VERSION ""

NS_ :

BS_:

BU_: LMFS RMFS TPMS TCU_ERAGLONASS E_APU PCCM NOX_2 NOX_1 ENGINE_CONTROL_MODULE TRANSMISSION INTARDER EBS TACHOGRAPH INSTRUMENT_CLUSTER CAMERA RADAR BCM

BO_ 2566741502 DM43: 22 Vector__XXX
 SG_ FlashRedStopLamp : 12|2@1+ (1,0) [0|3] "" Vector__XXX
 SG_ FlashProtectLamp : 8|2@1+ (1,0) [0|3] "" Vector__XXX
 SG_ FlashMalfuncIndicatorLamp : 14|2@1+ (1,0) [0|3] "" Vector__XXX
 SG_ FlashAmberWarningLamp : 10|2@1+ (1,0) [0|3] "" Vector__XXX
 SG_ MalfunctionIndicatorLampStatus : 6|2@1+ (1,0) [0|3] "" Vector__XXX
 SG_ AmberWarningLampStatus : 2|2@1+ (1,0) [0|3] "" Vector__XXX
 SG_ RedStopLampState : 4|2@1+ (1,0) [0|3] "" Vector__XXX
 SG_ ProtectLampStatus : 0|2@1+ (1,0) [0|3] "" Vector__XXX
 SG_ DTC5 : 144|32@1+ (1,0) [0|4294967295] "" Vector__XXX
 SG_ DTC4 : 112|32@1+ (1,0) [0|4294967295] "" Vector__XXX
 SG_ DTC3 : 80|32@1+ (1,0) [0|4294967295] "" Vector__XXX
 SG_ DTC2 : 48|32@1+ (1,0) [0|4294967295] "" Vector__XXX
 SG_ DTC1 : 16|32@1+ (1,0) [0|4294967295] "" Vector__XXX

BO_ 2566741758 DM42: 22 Vector__XXX
 SG_ FlashRedStopLamp : 12|2@1+ (1,0) [0|3] "" Vector__XXX
 SG_ FlashProtectLamp : 8|2@1+ (1,0) [0|3] "" Vector__XXX
 SG_ FlashMalfuncIndicatorLamp : 14|2@1+ (1,0) [0|3] "" Vector__XXX
 SG_ FlashAmberWarningLamp : 10|2@1+ (1,0) [0|3] "" Vector__XXX
 SG_ MalfunctionIndicatorLampStatus : 6|2@1+ (1,0) [0|3] "" Vector__XXX
 SG_ AmberWarningLampStatus : 2|2@1+ (1,0) [0|3] "" Vector__XXX
 SG_ RedStopLampState : 4|2@1+ (1,0) [0|3] "" Vector__XXX
 SG_ ProtectLampStatus : 0|2@1+ (1,0) [0|3] "" Vector__XXX
 SG_ DTC5 : 144|32@1+ (1,0) [0|4294967295] "" Vector__XXX
 SG_ DTC4 : 112|32@1+ (1,0) [0|4294967295] "" Vector__XXX
 SG_ DTC3 : 80|32@1+ (1,0) [0|4294967295] "" Vector__XXX
 SG_ DTC2 : 48|32@1+ (1,0) [0|4294967295] "" Vector__XXX
 SG_ DTC1 : 16|32@1+ (1,0) [0|4294967295] "" Vector__XXX

BO_ 2566742014 DM41: 22 Vector__XXX
 SG_ FlashRedStopLamp : 12|2@1+ (1,0) [0|3] "" Vector__XXX
 SG_ FlashProtectLamp : 8|2@1+ (1,0) [0|3] "" Vector__XXX
 SG_ FlashMalfuncIndicatorLamp : 14|2@1+ (1,0) [0|3] "" Vector__XXX
 SG_ FlashAmberWarningLamp : 10|2@1+ (1,0) [0|3] "" Vector__XXX
 SG_ MalfunctionIndicatorLampStatus : 6|2@1+ (1,0) [0|3] "" Vector__XXX
 SG_ AmberWarningLampStatus : 2|2@1+ (1,0) [0|3] "" Vector__XXX
 SG_ RedStopLampState : 4|2@1+ (1,0) [0|3] "" Vector__XXX
 SG_ ProtectLampStatus : 0|2@1+ (1,0) [0|3] "" Vector__XXX
 SG_ DTC5 : 144|32@1+ (1,0) [0|4294967295] "" Vector__XXX
 SG_ DTC4 : 112|32@1+ (1,0) [0|4294967295] "" Vector__XXX
 SG_ DTC3 : 80|32@1+ (1,0) [0|4294967295] "" Vector__XXX
 SG_ DTC2 : 48|32@1+ (1,0) [0|4294967295] "" Vector__XXX
 SG_ DTC1 : 16|32@1+ (1,0) [0|4294967295] "" Vector__XXX

BO_ 2560622334 DM35: 22 Vector__XXX
 SG_ FlashRedStopLamp : 12|2@1+ (1,0) [0|3] "" Vector__XXX
 SG_ FlashProtectLamp : 8|2@1+ (1,0) [0|3] "" Vector__XXX
 SG_ FlashMalfuncIndicatorLamp : 14|2@1+ (1,0) [0|3] "" Vector__XXX
 SG_ FlashAmberWarningLamp : 10|2@1+ (1,0) [0|3] "" Vector__XXX
 SG_ MalfunctionIndicatorLampStatus : 6|2@1+ (1,0) [0|3] "" Vector__XXX
 SG_ AmberWarningLampStatus : 2|2@1+ (1,0) [0|3] "" Vector__XXX
 SG_ RedStopLampState : 4|2@1+ (1,0) [0|3] "" Vector__XXX
 SG_ ProtectLampStatus : 0|2@1+ (1,0) [0|3] "" Vector__XXX
 SG_ DTC5 : 144|32@1+ (1,0) [0|4294967295] "" Vector__XXX
 SG_ DTC4 : 112|32@1+ (1,0) [0|4294967295] "" Vector__XXX
 SG_ DTC3 : 80|32@1+ (1,0) [0|4294967295] "" Vector__XXX
 SG_ DTC2 : 48|32@1+ (1,0) [0|4294967295] "" Vector__XXX
 SG_ DTC1 : 16|32@1+ (1,0) [0|4294967295] "" Vector__XXX

BO_ 2566744062 ZNVW: 8 Vector__XXX
 SG_ ZeroNetVehicleWeightChange : 0|2@1+ (1,0) [0|3] "" Vector__XXX

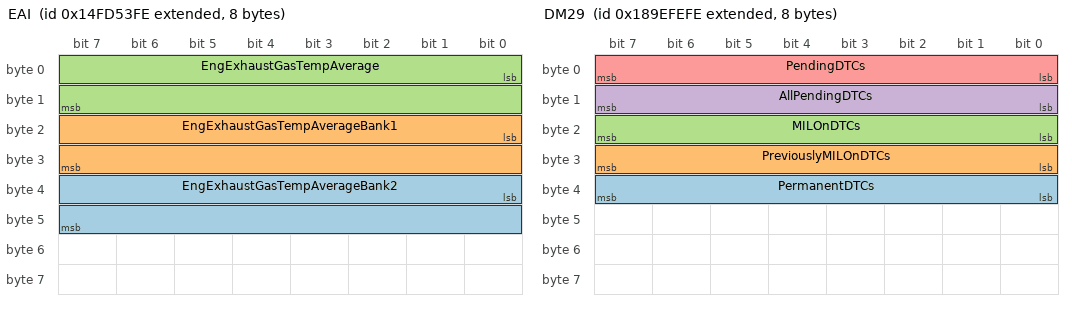
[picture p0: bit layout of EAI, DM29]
BO_ 2499630078 EAI: 8 Vector__XXX
 SG_ EngExhaustGasTempAverageBank2 : 32|16@1+ (0.03125,-273) [-273|1734.96875] "deg C" Vector__XXX
 SG_ EngExhaustGasTempAverageBank1 : 16|16@1+ (0.03125,-273) [-273|1734.96875] "deg C" Vector__XXX
 SG_ EngExhaustGasTempAverage : 0|16@1+ (0.03125,-273) [-273|1734.96875] "deg C" Vector__XXX

BO_ 2560556798 DM29: 8 Vector__XXX
 SG_ PermanentDTCs : 32|8@1+ (1,0) [0|255] "" Vector__XXX
 SG_ PreviouslyMILOnDTCs : 24|8@1+ (1,0) [0|255] "" Vector__XXX
 SG_ MILOnDTCs : 16|8@1+ (1,0) [0|255] "" Vector__XXX
 SG_ AllPendingDTCs : 8|8@1+ (1,0) [0|255] "" Vector__XXX
 SG_ PendingDTCs : 0|8@1+ (1,0) [0|255] "" Vector__XXX

BO_ 2566750462 DM28: 22 Vector__XXX
 SG_ FlashRedStopLamp : 12|2@1+ (1,0) [0|3] "" Vector__XXX
 SG_ FlashProtectLamp : 8|2@1+ (1,0) [0|3] "" Vector__XXX
 SG_ FlashMalfuncIndicatorLamp : 14|2@1+ (1,0) [0|3] "" Vector__XXX
 SG_ FlashAmberWarningLamp : 10|2@1+ (1,0) [0|3] "" Vector__XXX
 SG_ MalfunctionIndicatorLampStatus : 6|2@1+ (1,0) [0|3] "" Vector__XXX
 SG_ AmberWarningLampStatus : 2|2@1+ (1,0) [0|3] "" Vector__XXX
 SG_ RedStopLampState : 4|2@1+ (1,0) [0|3] "" Vector__XXX
 SG_ ProtectLampStatus : 0|2@1+ (1,0) [0|3] "" Vector__XXX
 SG_ DTC5 : 144|32@1+ (1,0) [0|4294967295] "" Vector__XXX
 SG_ DTC4 : 112|32@1+ (1,0) [0|4294967295] "" Vector__XXX
 SG_ DTC3 : 80|32@1+ (1,0) [0|4294967295] "" Vector__XXX
 SG_ DTC2 : 48|32@1+ (1,0) [0|4294967295] "" Vector__XXX
 SG_ DTC1 : 16|32@1+ (1,0) [0|4294967295] "" Vector__XXX

BO_ 2566750974 DM27: 22 Vector__XXX
 SG_ FlashRedStopLamp : 12|2@1+ (1,0) [0|3] "" Vector__XXX
 SG_ FlashProtectLamp : 8|2@1+ (1,0) [0|3] "" Vector__XXX
 SG_ FlashMalfuncIndicatorLamp : 14|2@1+ (1,0) [0|3] "" Vector__XXX
 SG_ FlashAmberWarningLamp : 10|2@1+ (1,0) [0|3] "" Vector__XXX
 SG_ MalfunctionIndicatorLampStatus : 6|2@1+ (1,0) [0|3] "" Vector__XXX
 SG_ AmberWarningLampStatus : 2|2@1+ (1,0) [0|3] "" Vector__XXX
 SG_ RedStopLampState : 4|2@1+ (1,0) [0|3] "" Vector__XXX
 SG_ ProtectLampStatus : 0|2@1+ (1,0) [0|3] "" Vector__XXX
 SG_ DTC5 : 144|32@1+ (1,0) [0|4294967295] "" Vector__XXX
 SG_ DTC4 : 112|32@1+ (1,0) [0|4294967295] "" Vector__XXX
 SG_ DTC3 : 80|32@1+ (1,0) [0|4294967295] "" Vector__XXX
 SG_ DTC2 : 48|32@1+ (1,0) [0|4294967295] "" Vector__XXX
 SG_ DTC1 : 16|32@1+ (1,0) [0|4294967295] "" Vector__XXX

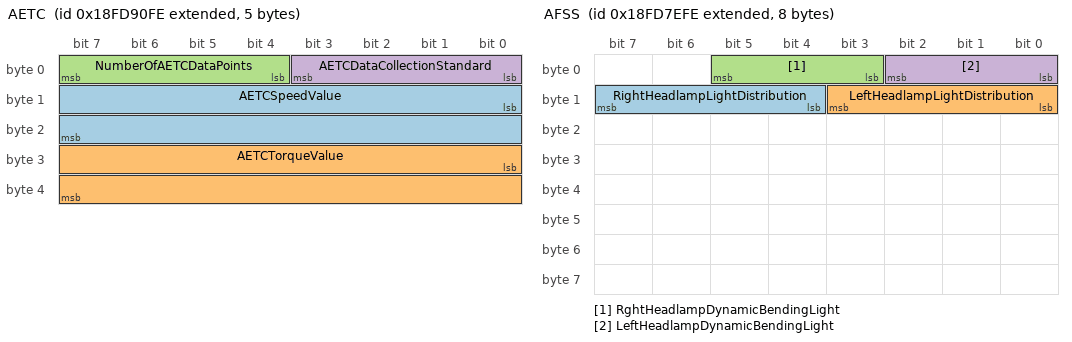
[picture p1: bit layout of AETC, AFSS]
BO_ 2566754558 AETC: 5 Vector__XXX
 SG_ AETCSpeedValue : 8|16@1- (1,0) [0|8031.875] "rpm" Vector__XXX
 SG_ AETCTorqueValue : 24|16@1+ (1,0) [0|64255] "Nm" Vector__XXX
 SG_ NumberOfAETCDataPoints : 4|4@1+ (1,0) [0|15] "" Vector__XXX
 SG_ AETCDataCollectionStandard : 0|4@1+ (1,0) [0|15] "" Vector__XXX

BO_ 2566749950 AFSS: 8 Vector__XXX
 SG_ RightHeadlampLightDistribution : 12|4@1+ (1,0) [0|15] "" Vector__XXX
 SG_ LeftHeadlampLightDistribution : 8|4@1+ (1,0) [0|15] "" Vector__XXX
 SG_ RghtHeadlampDynamicBendingLight : 3|3@1+ (1,0) [0|7] "" Vector__XXX
 SG_ LeftHeadlampDynamicBendingLight : 0|3@1+ (1,0) [0|7] "" Vector__XXX

BO_ 2566838539 AUXIO_T_EBS: 8 EBS
 SG_ AuxI_O16 : 24|2@1+ (1,0) [0|3] ""  PCCM,BCM
 SG_ AuxI_O15 : 26|2@1+ (1,0) [0|3] ""  PCCM,BCM
 SG_ AuxI_O14 : 28|2@1+ (1,0) [0|3] ""  PCCM,BCM
 SG_ AuxI_O13 : 30|2@1+ (1,0) [0|3] ""  PCCM,BCM
 SG_ AuxI_O12 : 16|2@1+ (1,0) [0|3] ""  PCCM,BCM
 SG_ AuxI_O11 : 18|2@1+ (1,0) [0|3] ""  PCCM,BCM
 SG_ AuxI_O10 : 20|2@1+ (1,0) [0|3] ""  PCCM,BCM
 SG_ AuxI_O09 : 22|2@1+ (1,0) [0|3] ""  PCCM,BCM
 SG_ AuxI_O08_GearboxNeutralPos_AUX : 8|2@1+ (1,0) [0|3] ""  PCCM,BCM
 SG_ AuxI_O07_TrailerABSFulOper_AUX : 10|2@1+ (1,0) [0|3] ""  PCCM,BCM
 SG_ AuxI_O06_TrailerABSDetected_AUX : 12|2@1+ (1,0) [0|3] ""  PCCM,BCM
 SG_ AuxI_O05_TrailerConnected_AUX : 14|2@1+ (1,0) [0|3] ""  PCCM,BCM
 SG_ AuxI_O04 : 0|2@1+ (1,0) [0|3] ""  PCCM,BCM
 SG_ AuxI_O03 : 2|2@1+ (1,0) [0|3] ""  PCCM,BCM
 SG_ AuxI_O01 : 6|2@1+ (1,0) [0|3] ""  PCCM,BCM
 SG_ AuxI_OChannel2 : 48|16@1+ (1,0) [0|65535] "counts"  PCCM,BCM
 SG_ AuxI_OChannel1 : 32|16@1+ (1,0) [0|65535] "counts"  PCCM,BCM

BO_ 2561146622 AUXIO2: 8 Vector__XXX
 SG_ AuxI_O45 : 62|2@1+ (1,0) [0|3] "" Vector__XXX
 SG_ AuxI_O46 : 60|2@1+ (1,0) [0|3] "" Vector__XXX
 SG_ AuxI_O47 : 58|2@1+ (1,0) [0|3] "" Vector__XXX
 SG_ AuxI_O48 : 56|2@1+ (1,0) [0|3] "" Vector__XXX
 SG_ AuxI_O41 : 54|2@1+ (1,0) [0|3] "" Vector__XXX
 SG_ AuxI_O42 : 52|2@1+ (1,0) [0|3] "" Vector__XXX
 SG_ AuxI_O43 : 50|2@1+ (1,0) [0|3] "" Vector__XXX
 SG_ AuxI_O44 : 48|2@1+ (1,0) [0|3] "" Vector__XXX
 SG_ AuxI_O37 : 46|2@1+ (1,0) [0|3] "" Vector__XXX
 SG_ AuxI_O38 : 44|2@1+ (1,0) [0|3] "" Vector__XXX
 SG_ AuxI_O39 : 42|2@1+ (1,0) [0|3] "" Vector__XXX
 SG_ AuxI_O40 : 40|2@1+ (1,0) [0|3] "" Vector__XXX
 SG_ AuxI_O33 : 38|2@1+ (1,0) [0|3] "" Vector__XXX
 SG_ AuxI_O34 : 36|2@1+ (1,0) [0|3] "" Vector__XXX
 SG_ AuxI_O35 : 34|2@1+ (1,0) [0|3] "" Vector__XXX
 SG_ AuxI_O36 : 32|2@1+ (1,0) [0|3] "" Vector__XXX
 SG_ AuxI_O29 : 30|2@1+ (1,0) [0|3] "" Vector__XXX
 SG_ AuxI_O30 : 28|2@1+ (1,0) [0|3] "" Vector__XXX
 SG_ AuxI_O31 : 26|2@1+ (1,0) [0|3] "" Vector__XXX
 SG_ AuxI_O32 : 24|2@1+ (1,0) [0|3] "" Vector__XXX
 SG_ AuxI_O25 : 22|2@1+ (1,0) [0|3] "" Vector__XXX
 SG_ AuxI_O26 : 20|2@1+ (1,0) [0|3] "" Vector__XXX
 SG_ AuxI_O27 : 18|2@1+ (1,0) [0|3] "" Vector__XXX
 SG_ AuxI_O28 : 16|2@1+ (1,0) [0|3] "" Vector__XXX
 SG_ AuxI_O21 : 14|2@1+ (1,0) [0|3] "" Vector__XXX
 SG_ AuxI_O22 : 12|2@1+ (1,0) [0|3] "" Vector__XXX
 SG_ AuxI_O23 : 10|2@1+ (1,0) [0|3] "" Vector__XXX
 SG_ AuxI_O24 : 8|2@1+ (1,0) [0|3] "" Vector__XXX
 SG_ AuxI_O17 : 6|2@1+ (1,0) [0|3] "" Vector__XXX
 SG_ AuxI_O18 : 4|2@1+ (1,0) [0|3] "" Vector__XXX
 SG_ AuxI_O19 : 2|2@1+ (1,0) [0|3] "" Vector__XXX
 SG_ AuxI_O20 : 0|2@1+ (1,0) [0|3] "" Vector__XXX

BO_ 2561081086 AUXIO3: 8 Vector__XXX
 SG_ AuxI_O77 : 62|2@1+ (1,0) [0|3] "" Vector__XXX
 SG_ AuxI_O78 : 60|2@1+ (1,0) [0|3] "" Vector__XXX
 SG_ AuxI_O79 : 58|2@1+ (1,0) [0|3] "" Vector__XXX
 SG_ AuxI_O80 : 56|2@1+ (1,0) [0|3] "" Vector__XXX
 SG_ AuxI_O73 : 54|2@1+ (1,0) [0|3] "" Vector__XXX
 SG_ AuxI_O74 : 52|2@1+ (1,0) [0|3] "" Vector__XXX
 SG_ AuxI_O75 : 50|2@1+ (1,0) [0|3] "" Vector__XXX
 SG_ AuxI_O76 : 48|2@1+ (1,0) [0|3] "" Vector__XXX
 SG_ AuxI_O69 : 46|2@1+ (1,0) [0|3] "" Vector__XXX
 SG_ AuxI_O70 : 44|2@1+ (1,0) [0|3] "" Vector__XXX
 SG_ AuxI_O71 : 42|2@1+ (1,0) [0|3] "" Vector__XXX
 SG_ AuxI_O72 : 40|2@1+ (1,0) [0|3] "" Vector__XXX
 SG_ AuxI_O65 : 38|2@1+ (1,0) [0|3] "" Vector__XXX
 SG_ AuxI_O66 : 36|2@1+ (1,0) [0|3] "" Vector__XXX
 SG_ AuxI_O67 : 34|2@1+ (1,0) [0|3] "" Vector__XXX
 SG_ AuxI_O68 : 32|2@1+ (1,0) [0|3] "" Vector__XXX
 SG_ AuxI_O61 : 30|2@1+ (1,0) [0|3] "" Vector__XXX
 SG_ AuxI_O62 : 28|2@1+ (1,0) [0|3] "" Vector__XXX
 SG_ AuxI_O63 : 26|2@1+ (1,0) [0|3] "" Vector__XXX
 SG_ AuxI_O64 : 24|2@1+ (1,0) [0|3] "" Vector__XXX
 SG_ AuxI_O57 : 22|2@1+ (1,0) [0|3] "" Vector__XXX
 SG_ AuxI_O58 : 20|2@1+ (1,0) [0|3] "" Vector__XXX
 SG_ AuxI_O59 : 18|2@1+ (1,0) [0|3] "" Vector__XXX
 SG_ AuxI_O60 : 16|2@1+ (1,0) [0|3] "" Vector__XXX
 SG_ AuxI_O53 : 14|2@1+ (1,0) [0|3] "" Vector__XXX
 SG_ AuxI_O54 : 12|2@1+ (1,0) [0|3] "" Vector__XXX
 SG_ AuxI_O55 : 10|2@1+ (1,0) [0|3] "" Vector__XXX
 SG_ AuxI_O56 : 8|2@1+ (1,0) [0|3] "" Vector__XXX
 SG_ AuxI_O49 : 6|2@1+ (1,0) [0|3] "" Vector__XXX
 SG_ AuxI_O50 : 4|2@1+ (1,0) [0|3] "" Vector__XXX
 SG_ AuxI_O51 : 2|2@1+ (1,0) [0|3] "" Vector__XXX
 SG_ AuxI_O52 : 0|2@1+ (1,0) [0|3] "" Vector__XXX

BO_ 2561015550 AUXIO4: 8 Vector__XXX
 SG_ AuxI_O92 : 16|2@1+ (1,0) [0|3] "" Vector__XXX
 SG_ AuxI_O85 : 14|2@1+ (1,0) [0|3] "" Vector__XXX
 SG_ AuxI_O86 : 12|2@1+ (1,0) [0|3] "" Vector__XXX
 SG_ AuxI_O87 : 10|2@1+ (1,0) [0|3] "" Vector__XXX
 SG_ AuxI_O88 : 8|2@1+ (1,0) [0|3] "" Vector__XXX
 SG_ AuxI_O81 : 6|2@1+ (1,0) [0|3] "" Vector__XXX
 SG_ AuxI_O82 : 4|2@1+ (1,0) [0|3] "" Vector__XXX
 SG_ AuxI_O83 : 2|2@1+ (1,0) [0|3] "" Vector__XXX
 SG_ AuxI_O84 : 0|2@1+ (1,0) [0|3] "" Vector__XXX
 SG_ AuxI_O109 : 62|2@1+ (1,0) [0|3] "" Vector__XXX
 SG_ AuxI_O110 : 60|2@1+ (1,0) [0|3] "" Vector__XXX
 SG_ AuxI_O111 : 58|2@1+ (1,0) [0|3] "" Vector__XXX
 SG_ AuxI_O112 : 56|2@1+ (1,0) [0|3] "" Vector__XXX
 SG_ AuxI_O105 : 54|2@1+ (1,0) [0|3] "" Vector__XXX
 SG_ AuxI_O106 : 52|2@1+ (1,0) [0|3] "" Vector__XXX
 SG_ AuxI_O107 : 50|2@1+ (1,0) [0|3] "" Vector__XXX
 SG_ AuxI_O108 : 48|2@1+ (1,0) [0|3] "" Vector__XXX
 SG_ AuxI_O101 : 46|2@1+ (1,0) [0|3] "" Vector__XXX
 SG_ AuxI_O102 : 44|2@1+ (1,0) [0|3] "" Vector__XXX
 SG_ AuxI_O103 : 42|2@1+ (1,0) [0|3] "" Vector__XXX
 SG_ AuxI_O104 : 40|2@1+ (1,0) [0|3] "" Vector__XXX
 SG_ AuxI_O97 : 38|2@1+ (1,0) [0|3] "" Vector__XXX
 SG_ AuxI_O98 : 36|2@1+ (1,0) [0|3] "" Vector__XXX
 SG_ AuxI_O99 : 34|2@1+ (1,0) [0|3] "" Vector__XXX
 SG_ AuxI_O100 : 32|2@1+ (1,0) [0|3] "" Vector__XXX
 SG_ AuxI_O93 : 30|2@1+ (1,0) [0|3] "" Vector__XXX
 SG_ AuxI_O94 : 28|2@1+ (1,0) [0|3] "" Vector__XXX
 SG_ AuxI_O95 : 26|2@1+ (1,0) [0|3] "" Vector__XXX
 SG_ AuxI_O96 : 24|2@1+ (1,0) [0|3] "" Vector__XXX
 SG_ AuxI_O89 : 22|2@1+ (1,0) [0|3] "" Vector__XXX
 SG_ AuxI_O90 : 20|2@1+ (1,0) [0|3] "" Vector__XXX
 SG_ AuxI_O91 : 18|2@1+ (1,0) [0|3] "" Vector__XXX

BO_ 2566746622 BSA: 8 Vector__XXX
 SG_ TrailerBrakeStrokeAxle5Right : 57|3@1+ (1,0) [0|7] "" Vector__XXX
 SG_ TrailerBrakeStrokeAxle5Left : 54|3@1+ (1,0) [0|7] "" Vector__XXX
 SG_ TrailerBrakeStrokeAxle4Right : 51|3@1+ (1,0) [0|7] "" Vector__XXX
 SG_ TrailerBrakeStrokeAxle4Left : 48|3@1+ (1,0) [0|7] "" Vector__XXX
 SG_ TrailerBrakeStrokeAxle3Right : 45|3@1+ (1,0) [0|7] "" Vector__XXX
 SG_ TrailerBrakeStrokeAxle3Left : 42|3@1+ (1,0) [0|7] "" Vector__XXX
 SG_ TrailerBrakeStrokeAxle2Right : 39|3@1+ (1,0) [0|7] "" Vector__XXX
 SG_ TrailerBrakeStrokeAxle2Left : 36|3@1+ (1,0) [0|7] "" Vector__XXX
 SG_ TrailerBrakeStrokeAxle1Right : 33|3@1+ (1,0) [0|7] "" Vector__XXX
 SG_ TrailerBrakeStrokeAxle1Left : 30|3@1+ (1,0) [0|7] "" Vector__XXX
 SG_ TractorBrakeStrokeAxle5Right : 27|3@1+ (1,0) [0|7] "" Vector__XXX
 SG_ TractorBrakeStrokeAxle5Left : 24|3@1+ (1,0) [0|7] "" Vector__XXX
 SG_ TractorBrakeStrokeAxle4Right : 21|3@1+ (1,0) [0|7] "" Vector__XXX
 SG_ TractorBrakeStrokeAxle4Left : 18|3@1+ (1,0) [0|7] "" Vector__XXX
 SG_ TractorBrakeStrokeAxle3Right : 15|3@1+ (1,0) [0|7] "" Vector__XXX
 SG_ TractorBrakeStrokeAxle3Left : 12|3@1+ (1,0) [0|7] "" Vector__XXX
 SG_ TractorBrakeStrokeAxle2Right : 9|3@1+ (1,0) [0|7] "" Vector__XXX
 SG_ TractorBrakeStrokeAxle2Left : 6|3@1+ (1,0) [0|7] "" Vector__XXX
 SG_ TractorBrakeStrokeAxle1Right : 3|3@1+ (1,0) [0|7] "" Vector__XXX
 SG_ TractorBrakeStrokeAxle1Left : 0|3@1+ (1,0) [0|7] "" Vector__XXX

BO_ 2566845950 AMB: 8 Vector__XXX
 SG_ EngAirIntakeTemp : 40|8@1+ (1,-40) [-40|210] "deg C" Vector__XXX
 SG_ BarometricPress : 0|8@1+ (0.5,0) [0|125] "kPa" Vector__XXX

BO_ 2566840062 AIR2: 8 Vector__XXX
 SG_ EngAirStartPress : 0|8@1+ (4,0) [0|1000] "kPa" Vector__XXX

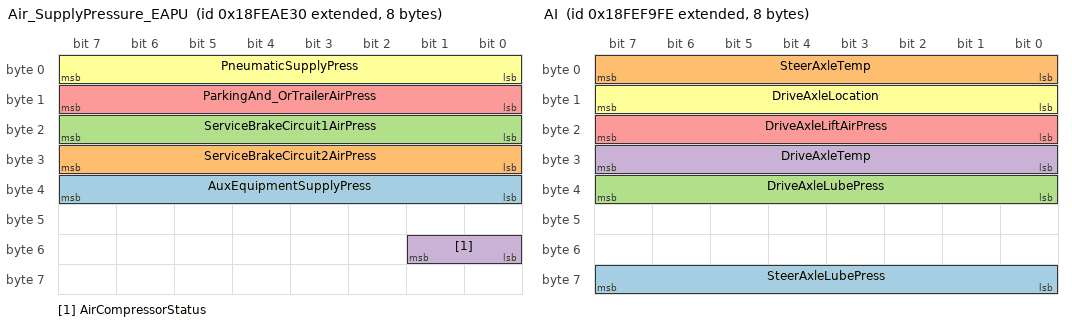
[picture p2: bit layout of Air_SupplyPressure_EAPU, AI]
BO_ 2566827568 Air_SupplyPressure_EAPU: 8 E_APU
 SG_ AuxEquipmentSupplyPress : 32|8@1+ (8,0) [0|2000] "kPa"  PCCM
 SG_ ServiceBrakeCircuit2AirPress : 24|8@1+ (8,0) [0|2000] "kPa"  PCCM,INSTRUMENT_CLUSTER,BCM
 SG_ ServiceBrakeCircuit1AirPress : 16|8@1+ (8,0) [0|2000] "kPa"  PCCM,INSTRUMENT_CLUSTER,BCM
 SG_ AirCompressorStatus : 48|2@1+ (1,0) [0|3] ""  PCCM,INSTRUMENT_CLUSTER,BCM
 SG_ ParkingAnd_OrTrailerAirPress : 8|8@1+ (8,0) [0|2000] "kPa"  PCCM,INSTRUMENT_CLUSTER,BCM
 SG_ PneumaticSupplyPress : 0|8@1+ (8,0) [0|2000] "kPa"  PCCM,INSTRUMENT_CLUSTER,BCM

BO_ 2566846974 AI: 8 Vector__XXX
 SG_ SteerAxleLubePress : 56|8@1+ (4,0) [0|1000] "kPa" Vector__XXX
 SG_ SteerAxleTemp : 0|8@1+ (1,-40) [-40|210] "deg C" Vector__XXX
 SG_ DriveAxleLubePress : 32|8@1+ (4,0) [0|1000] "kPa" Vector__XXX
 SG_ DriveAxleTemp : 24|8@1+ (1,-40) [-40|210] "deg C" Vector__XXX
 SG_ DriveAxleLiftAirPress : 16|8@1+ (4,0) [0|1000] "kPa" Vector__XXX
 SG_ DriveAxleLocation : 8|8@1+ (1,0) [0|255] "" Vector__XXX

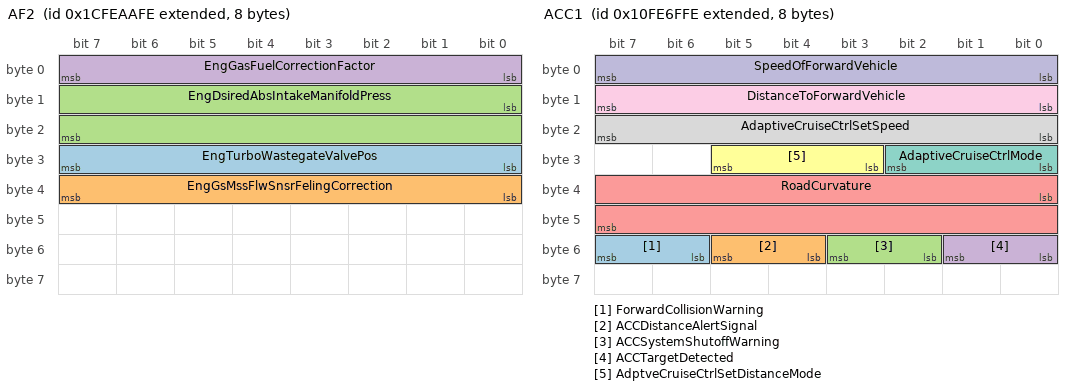
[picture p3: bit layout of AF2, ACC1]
BO_ 2633935614 AF2: 8 Vector__XXX
 SG_ EngTurboWastegateValvePos : 24|8@1+ (0.4,0) [0|100] "%" Vector__XXX
 SG_ EngGsMssFlwSnsrFelingCorrection : 32|8@1+ (1,-125) [-125|125] "%" Vector__XXX
 SG_ EngDsiredAbsIntakeManifoldPress : 8|16@1+ (0.1,0) [0|6425.5] "kPa" Vector__XXX
 SG_ EngGasFuelCorrectionFactor : 0|8@1+ (1,0) [0|250] "%" Vector__XXX

BO_ 2566803745 ACC2: 8 BCM
 SG_ RequestedACCDistanceMode : 5|3@1+ (1,0) [0|7] "SED"  RADAR
 SG_ ACCUsageDemand_ACC2 : 0|2@1+ (1,0) [0|3] ""  RADAR

BO_ 2432593918 ACC1: 8 Vector__XXX
 SG_ ForwardCollisionWarning : 54|2@1+ (1,0) [0|3] "" Vector__XXX
 SG_ ACCDistanceAlertSignal : 52|2@1+ (1,0) [0|3] "" Vector__XXX
 SG_ ACCSystemShutoffWarning : 50|2@1+ (1,0) [0|3] "" Vector__XXX
 SG_ ACCTargetDetected : 48|2@1+ (1,0) [0|3] "" Vector__XXX
 SG_ RoadCurvature : 32|16@1+ (0.0078125,-250) [-250|251.992] "1/km" Vector__XXX
 SG_ AdptveCruiseCtrlSetDistanceMode : 27|3@1+ (1,0) [0|7] "" Vector__XXX
 SG_ AdaptiveCruiseCtrlMode : 24|3@1+ (1,0) [0|7] "" Vector__XXX
 SG_ AdaptiveCruiseCtrlSetSpeed : 16|8@1+ (1,0) [0|250] "km/h" Vector__XXX
 SG_ DistanceToForwardVehicle : 8|8@1+ (1,0) [0|250] "m" Vector__XXX
 SG_ SpeedOfForwardVehicle : 0|8@1+ (1,0) [0|250] "km/h" Vector__XXX

BO_ 2633935102 AC: 8 Vector__XXX
 SG_ ArticulationAngle : 0|8@1+ (1,-125) [-125|125] "deg" Vector__XXX

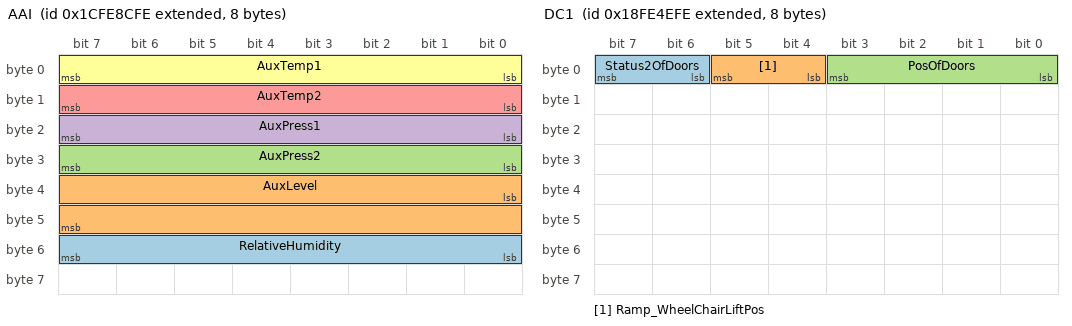
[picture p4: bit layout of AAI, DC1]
BO_ 2633927934 AAI: 8 Vector__XXX
 SG_ RelativeHumidity : 48|8@1+ (0.4,0) [0|100] "%" Vector__XXX
 SG_ AuxLevel : 32|16@1+ (0.1,0) [0|6425.5] "mm" Vector__XXX
 SG_ AuxPress2 : 24|8@1+ (16,0) [0|4000] "kPa" Vector__XXX
 SG_ AuxPress1 : 16|8@1+ (16,0) [0|4000] "kPa" Vector__XXX
 SG_ AuxTemp2 : 8|8@1+ (1,-40) [-40|210] "deg C" Vector__XXX
 SG_ AuxTemp1 : 0|8@1+ (1,-40) [-40|210] "deg C" Vector__XXX

BO_ 2566847998 A1: 8 Vector__XXX
 SG_ EngBlowerBypassValvePos : 0|8@1+ (0.4,0) [0|100] "%" Vector__XXX
 SG_ EngGasSupplyPress : 8|16@1+ (0.5,0) [0|32127.5] "kPa" Vector__XXX

BO_ 2565406462 ACKM: 8 Vector__XXX
 SG_ AddressBusy m3 : 32|8@1+ (1,0) [0|255] "" Vector__XXX
 SG_ ControlByte M : 0|8@1+ (1,0) [0|255] "" Vector__XXX
 SG_ GroupFunctionValue : 8|8@1+ (1,0) [0|255] "" Vector__XXX
 SG_ AddressAccessDenied m2 : 32|8@1+ (1,0) [0|255] "" Vector__XXX
 SG_ AddressNegativeAcknowledgement m1 : 32|8@1+ (1,0) [0|255] "" Vector__XXX
 SG_ AddressAcknowledged m0 : 32|8@1+ (1,0) [0|255] "" Vector__XXX

BO_ 2566803198 DC1: 8 Vector__XXX
 SG_ Status2OfDoors : 6|2@1+ (1,0) [0|3] "" Vector__XXX
 SG_ Ramp_WheelChairLiftPos : 4|2@1+ (1,0) [0|3] "" Vector__XXX
 SG_ PosOfDoors : 0|4@1+ (1,0) [0|15] "" Vector__XXX

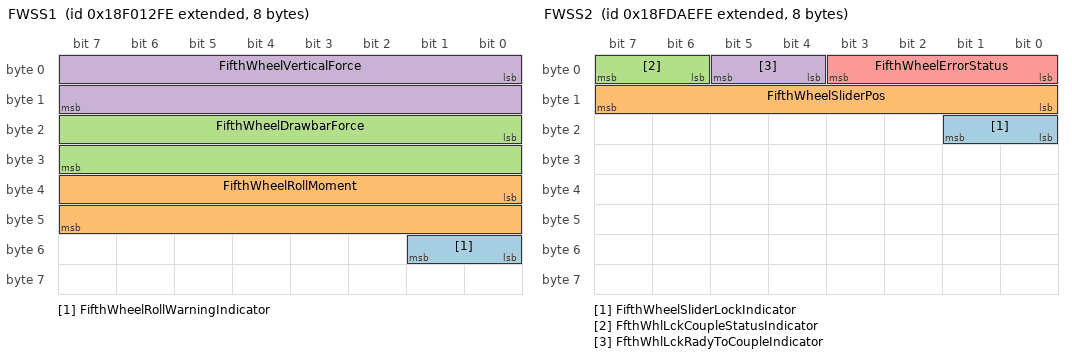
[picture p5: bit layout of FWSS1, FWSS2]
BO_ 2565870334 FWSS1: 8 Vector__XXX
 SG_ FifthWheelRollWarningIndicator : 48|2@1+ (1,0) [0|3] "" Vector__XXX
 SG_ FifthWheelRollMoment : 32|16@1+ (10,-320000) [-320000|322550] "N" Vector__XXX
 SG_ FifthWheelDrawbarForce : 16|16@1+ (10,-320000) [-320000|322550] "N" Vector__XXX
 SG_ FifthWheelVerticalForce : 0|16@1+ (5,0) [0|321275] "N" Vector__XXX

BO_ 2566762238 FWSS2: 8 Vector__XXX
 SG_ FifthWheelSliderLockIndicator : 16|2@1+ (1,0) [0|3] "" Vector__XXX
 SG_ FifthWheelSliderPos : 8|8@1+ (10,0) [0|2500] "mm" Vector__XXX
 SG_ FfthWhlLckCoupleStatusIndicator : 6|2@1+ (1,0) [0|3] "" Vector__XXX
 SG_ FfthWhlLckRadyToCoupleIndicator : 4|2@1+ (1,0) [0|3] "" Vector__XXX
 SG_ FifthWheelErrorStatus : 0|4@1+ (1,0) [0|15] "" Vector__XXX

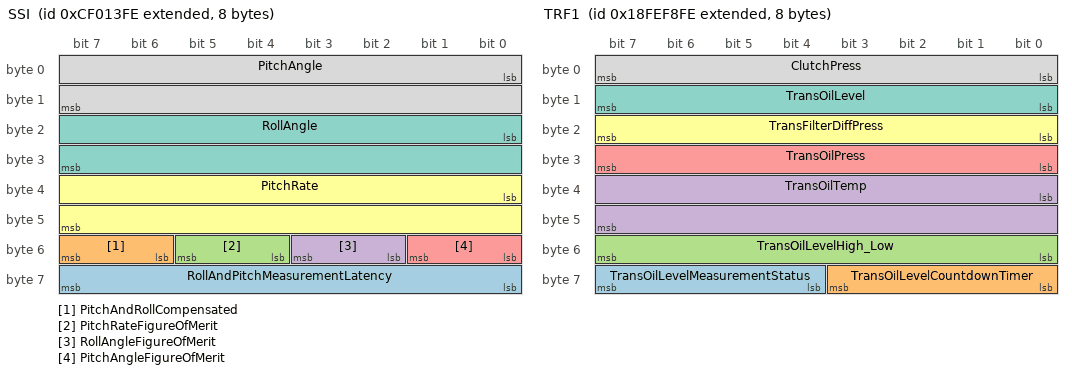
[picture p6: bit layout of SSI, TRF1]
BO_ 2364543998 SSI: 8 Vector__XXX
 SG_ RollAndPitchMeasurementLatency : 56|8@1+ (0.5,0) [0|125] "ms" Vector__XXX
 SG_ PitchAndRollCompensated : 54|2@1+ (1,0) [0|3] "" Vector__XXX
 SG_ PitchRateFigureOfMerit : 52|2@1+ (1,0) [0|3] "" Vector__XXX
 SG_ RollAngleFigureOfMerit : 50|2@1+ (1,0) [0|3] "" Vector__XXX
 SG_ PitchAngleFigureOfMerit : 48|2@1+ (1,0) [0|3] "" Vector__XXX
 SG_ PitchRate : 32|16@1+ (0.002,-64) [-64|64.51] "deg/sec" Vector__XXX
 SG_ RollAngle : 16|16@1+ (0.002,-64) [-64|64.51] "deg" Vector__XXX
 SG_ PitchAngle : 0|16@1+ (0.002,-64) [-64|64.51] "deg" Vector__XXX

BO_ 2566846718 TRF1: 8 Vector__XXX
 SG_ TransOilLevelMeasurementStatus : 60|4@1+ (1,0) [0|15] "" Vector__XXX
 SG_ TransOilLevelCountdownTimer : 56|4@1+ (1,0) [0|15] "" Vector__XXX
 SG_ TransOilLevelHigh_Low : 48|8@1+ (0.5,-62.5) [-62.5|62.5] "L" Vector__XXX
 SG_ TransOilTemp : 32|16@1+ (0.03125,-273) [-273|1734.96875] "deg C" Vector__XXX
 SG_ TransOilPress : 24|8@1+ (16,0) [0|4000] "kPa" Vector__XXX
 SG_ TransFilterDiffPress : 16|8@1+ (2,0) [0|500] "kPa" Vector__XXX
 SG_ TransOilLevel : 8|8@1+ (0.4,0) [0|100] "%" Vector__XXX
 SG_ ClutchPress : 0|8@1+ (16,0) [0|4000] "kPa" Vector__XXX

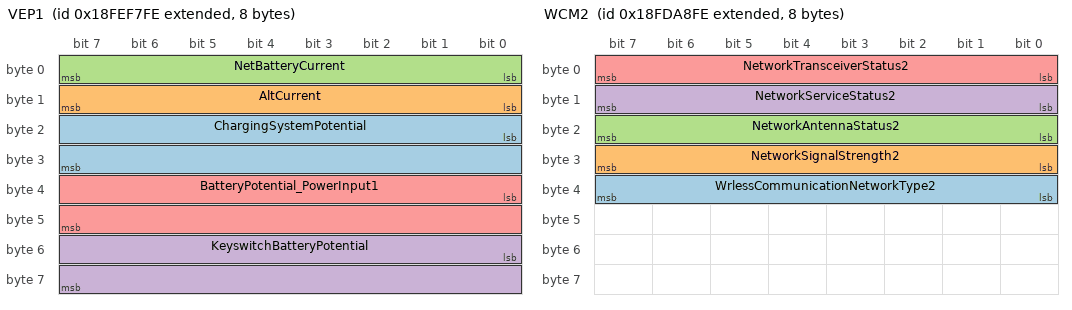
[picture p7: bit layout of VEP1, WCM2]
BO_ 2566846462 VEP1: 8 Vector__XXX
 SG_ ChargingSystemPotential : 16|16@1+ (0.05,0) [0|3212.75] "V" Vector__XXX
 SG_ AltCurrent : 8|8@1+ (1,0) [0|250] "A" Vector__XXX
 SG_ NetBatteryCurrent : 0|8@1+ (1,-125) [-125|125] "A" Vector__XXX
 SG_ KeyswitchBatteryPotential : 48|16@1+ (0.05,0) [0|3212.75] "V" Vector__XXX
 SG_ BatteryPotential_PowerInput1 : 32|16@1+ (0.05,0) [0|3212.75] "V" Vector__XXX

BO_ 2566760702 WCM2: 8 Vector__XXX
 SG_ WrlessCommunicationNetworkType2 : 32|8@1+ (1,0) [0|255] "" Vector__XXX
 SG_ NetworkSignalStrength2 : 24|8@1+ (0.4,0) [0|100] "%" Vector__XXX
 SG_ NetworkAntennaStatus2 : 16|8@1+ (1,0) [0|255] "" Vector__XXX
 SG_ NetworkServiceStatus2 : 8|8@1+ (1,0) [0|255] "" Vector__XXX
 SG_ NetworkTransceiverStatus2 : 0|8@1+ (1,0) [0|255] "" Vector__XXX

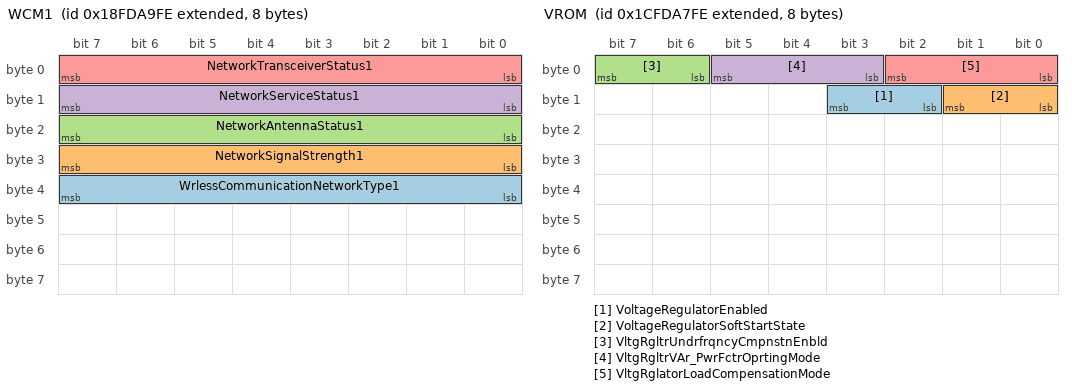
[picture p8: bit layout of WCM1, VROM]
BO_ 2566760958 WCM1: 8 Vector__XXX
 SG_ WrlessCommunicationNetworkType1 : 32|8@1+ (1,0) [0|255] "" Vector__XXX
 SG_ NetworkSignalStrength1 : 24|8@1+ (0.4,0) [0|100] "%" Vector__XXX
 SG_ NetworkAntennaStatus1 : 16|8@1+ (1,0) [0|255] "" Vector__XXX
 SG_ NetworkServiceStatus1 : 8|8@1+ (1,0) [0|255] "" Vector__XXX
 SG_ NetworkTransceiverStatus1 : 0|8@1+ (1,0) [0|255] "" Vector__XXX

BO_ 2633869310 VROM: 8 Vector__XXX
 SG_ VoltageRegulatorEnabled : 10|2@1+ (1,0) [0|3] "" Vector__XXX
 SG_ VoltageRegulatorSoftStartState : 8|2@1+ (1,0) [0|3] "" Vector__XXX
 SG_ VltgRgltrUndrfrqncyCmpnstnEnbld : 6|2@1+ (1,0) [0|3] "" Vector__XXX
 SG_ VltgRgltrVAr_PwrFctrOprtingMode : 3|3@1+ (1,0) [0|7] "" Vector__XXX
 SG_ VltgRglatorLoadCompensationMode : 0|3@1+ (1,0) [0|7] "" Vector__XXX

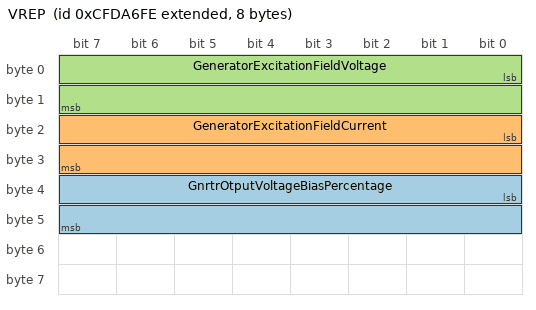
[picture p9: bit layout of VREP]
BO_ 2365433598 VREP: 8 Vector__XXX
 SG_ GnrtrOtputVoltageBiasPercentage : 32|16@1+ (0.1,-100) [-100|100] "%" Vector__XXX
 SG_ GeneratorExcitationFieldCurrent : 16|16@1+ (0.05,0) [0|3217.5] "A" Vector__XXX
 SG_ GeneratorExcitationFieldVoltage : 0|16@1+ (0.05,-1605.625) [-1605.625|1606.375] "V" Vector__XXX

CM_ BO_ 2565928476 "- 1s when no data to transmit; Segment, Stub or Profiles data sent, in the empty slots, at 100ms";
CM_ BO_ 2564554494 "Reserved for ISO 15765";
CM_ SG_ 2564554494 ProtocolCtrlInformation "Part of Network Protocol Control Information (N_PCI) of a ISO 15765 message.";
CM_ BO_ 2564488958 "Reserved for ISO 15765";
CM_ SG_ 2564488958 ProtocolCtrlInformation "Part of Network Protocol Control Information (N_PCI) of a ISO 15765 message.";
CM_ BO_ 2566741502 "Class A, Previously Active";
CM_ SG_ 2566741502 FlashRedStopLamp "This parameter provides the capability to flash the RSL (SPN 3039).";
CM_ SG_ 2566741502 FlashProtectLamp "This parameter provides the capability to flash the engine protect lamp (SPN 3041).";
CM_ SG_ 2566741502 FlashMalfuncIndicatorLamp "This parameter provides the capability to flash the MIL (SPN 3038).";
CM_ SG_ 2566741502 FlashAmberWarningLamp "This parameter provides the capability to flash the AWL (SPN 3040). ";
CM_ SG_ 2566741502 MalfunctionIndicatorLampStatus "A lamp used to relay only emissions-related trouble code information.";
CM_ SG_ 2566741502 AmberWarningLampStatus "This lamp is used to relay trouble code information that is reporting a problem with the vehicle system but the vehicle need
not be immediately stopped.";
CM_ SG_ 2566741502 RedStopLampState "This lamp is uesed to relay trouble code information that is of a severe enought condition that it warrants stopping the vehicle.";
CM_ SG_ 2566741502 ProtectLampStatus "This lamp is used to relay trouble code informatio that is reporting a problem with a vehicle system that is most
probably not electronic subsystem related.";
CM_ SG_ 2566741502 DTC5 "Diagnostic Trouble Code";
CM_ SG_ 2566741502 DTC4 "Diagnostic Trouble Code";
CM_ SG_ 2566741502 DTC3 "Diagnostic Trouble Code";
CM_ SG_ 2566741502 DTC2 "Diagnostic Trouble Code";
CM_ SG_ 2566741502 DTC1 "Diagnostic Trouble Code";
CM_ BO_ 2566741758 "Class A, Confirmed and Active";
CM_ SG_ 2566741758 FlashRedStopLamp "This parameter provides the capability to flash the RSL (SPN 3039).";
CM_ SG_ 2566741758 FlashProtectLamp "This parameter provides the capability to flash the engine protect lamp (SPN 3041).";
CM_ SG_ 2566741758 FlashMalfuncIndicatorLamp "This parameter provides the capability to flash the MIL (SPN 3038).";
CM_ SG_ 2566741758 FlashAmberWarningLamp "This parameter provides the capability to flash the AWL (SPN 3040). ";
CM_ SG_ 2566741758 MalfunctionIndicatorLampStatus "A lamp used to relay only emissions-related trouble code information.";
CM_ SG_ 2566741758 AmberWarningLampStatus "This lamp is used to relay trouble code information that is reporting a problem with the vehicle system but the vehicle need
not be immediately stopped.";
CM_ SG_ 2566741758 RedStopLampState "This lamp is uesed to relay trouble code information that is of a severe enought condition that it warrants stopping the vehicle.";
CM_ SG_ 2566741758 ProtectLampStatus "This lamp is used to relay trouble code informatio that is reporting a problem with a vehicle system that is most
probably not electronic subsystem related.";
CM_ SG_ 2566741758 DTC5 "Diagnostic Trouble Code";
CM_ SG_ 2566741758 DTC4 "Diagnostic Trouble Code";
CM_ SG_ 2566741758 DTC3 "Diagnostic Trouble Code";
CM_ SG_ 2566741758 DTC2 "Diagnostic Trouble Code";
CM_ SG_ 2566741758 DTC1 "Diagnostic Trouble Code";
CM_ BO_ 2566742014 "Class A, Pending";
CM_ SG_ 2566742014 FlashRedStopLamp "This parameter provides the capability to flash the RSL (SPN 3039).";
CM_ SG_ 2566742014 FlashProtectLamp "This parameter provides the capability to flash the engine protect lamp (SPN 3041).";
CM_ SG_ 2566742014 FlashMalfuncIndicatorLamp "This parameter provides the capability to flash the MIL (SPN 3038).";
CM_ SG_ 2566742014 FlashAmberWarningLamp "This parameter provides the capability to flash the AWL (SPN 3040). ";
CM_ SG_ 2566742014 MalfunctionIndicatorLampStatus "A lamp used to relay only emissions-related trouble code information.";
CM_ SG_ 2566742014 AmberWarningLampStatus "This lamp is used to relay trouble code information that is reporting a problem with the vehicle system but the vehicle need
not be immediately stopped.";
CM_ SG_ 2566742014 RedStopLampState "This lamp is uesed to relay trouble code information that is of a severe enought condition that it warrants stopping the vehicle.";
CM_ SG_ 2566742014 ProtectLampStatus "This lamp is used to relay trouble code informatio that is reporting a problem with a vehicle system that is most
probably not electronic subsystem related.";
CM_ SG_ 2566742014 DTC5 "Diagnostic Trouble Code";
CM_ SG_ 2566742014 DTC4 "Diagnostic Trouble Code";
CM_ SG_ 2566742014 DTC3 "Diagnostic Trouble Code";
CM_ SG_ 2566742014 DTC2 "Diagnostic Trouble Code";
CM_ SG_ 2566742014 DTC1 "Diagnostic Trouble Code";
CM_ BO_ 2560622334 "Immediate Fault Status ";
CM_ SG_ 2560622334 FlashRedStopLamp "This parameter provides the capability to flash the RSL (SPN 3039).";
CM_ SG_ 2560622334 FlashProtectLamp "This parameter provides the capability to flash the engine protect lamp (SPN 3041).";
CM_ SG_ 2560622334 FlashMalfuncIndicatorLamp "This parameter provides the capability to flash the MIL (SPN 3038).";
CM_ SG_ 2560622334 FlashAmberWarningLamp "This parameter provides the capability to flash the AWL (SPN 3040). ";
CM_ SG_ 2560622334 MalfunctionIndicatorLampStatus "A lamp used to relay only emissions-related trouble code information.";
CM_ SG_ 2560622334 AmberWarningLampStatus "This lamp is used to relay trouble code information that is reporting a problem with the vehicle system but the vehicle need
not be immediately stopped.";
CM_ SG_ 2560622334 RedStopLampState "This lamp is uesed to relay trouble code information that is of a severe enought condition that it warrants stopping the vehicle.";
CM_ SG_ 2560622334 ProtectLampStatus "This lamp is used to relay trouble code informatio that is reporting a problem with a vehicle system that is most
probably not electronic subsystem related.";
CM_ SG_ 2560622334 DTC5 "Diagnostic Trouble Code";
CM_ SG_ 2560622334 DTC4 "Diagnostic Trouble Code";
CM_ SG_ 2560622334 DTC3 "Diagnostic Trouble Code";
CM_ SG_ 2560622334 DTC2 "Diagnostic Trouble Code";
CM_ SG_ 2560622334 DTC1 "Diagnostic Trouble Code";
CM_ BO_ 2566744062 "Zero Net Vehicle Weight Change";
CM_ SG_ 2566744062 ZeroNetVehicleWeightChange "Zero Net Vehicle Weight Change command.";
CM_ BO_ 2499630078 "Reports averaged engine information";
CM_ SG_ 2499630078 EngExhaustGasTempAverageBank2 "The calculated average temperature based upon all of the Bank 2 (right bank) engine exhaust port temperatures.";
CM_ SG_ 2499630078 EngExhaustGasTempAverageBank1 "The calculated average temperature based upon all of the Bank 1 (left bank) engine exhaust port temperatures.";
CM_ SG_ 2499630078 EngExhaustGasTempAverage "The calculated average temperature based upon all of the engine exhaust port temperatures.";
CM_ BO_ 2560556798 "DTC Counts";
CM_ SG_ 2560556798 PermanentDTCs "Identifies the current number of permanent DTCs";
CM_ SG_ 2560556798 PreviouslyMILOnDTCs "Identifies the current number of previously MIL-On DTCs";
CM_ SG_ 2560556798 MILOnDTCs "Identifies the current number of MIL-On DTCs";
CM_ SG_ 2560556798 AllPendingDTCs "Identifies the current total number of pending DTCs, including emission related";
CM_ SG_ 2560556798 PendingDTCs "Identifies the current number of emission related pending DTCs";
CM_ BO_ 2566750462 "Permanent DTCs";
CM_ SG_ 2566750462 FlashRedStopLamp "This parameter provides the capability to flash the RSL (SPN 3039).";
CM_ SG_ 2566750462 FlashProtectLamp "This parameter provides the capability to flash the engine protect lamp (SPN 3041).";
CM_ SG_ 2566750462 FlashMalfuncIndicatorLamp "This parameter provides the capability to flash the MIL (SPN 3038).";
CM_ SG_ 2566750462 FlashAmberWarningLamp "This parameter provides the capability to flash the AWL (SPN 3040). ";
CM_ SG_ 2566750462 MalfunctionIndicatorLampStatus "A lamp used to relay only emissions-related trouble code information.";
CM_ SG_ 2566750462 AmberWarningLampStatus "This lamp is used to relay trouble code information that is reporting a problem with the vehicle system but the vehicle need
not be immediately stopped.";
CM_ SG_ 2566750462 RedStopLampState "This lamp is uesed to relay trouble code information that is of a severe enought condition that it warrants stopping the vehicle.";
CM_ SG_ 2566750462 ProtectLampStatus "This lamp is used to relay trouble code informatio that is reporting a problem with a vehicle system that is most
probably not electronic subsystem related.";
CM_ SG_ 2566750462 DTC5 "Diagnostic Trouble Code";
CM_ SG_ 2566750462 DTC4 "Diagnostic Trouble Code";
CM_ SG_ 2566750462 DTC3 "Diagnostic Trouble Code";
CM_ SG_ 2566750462 DTC2 "Diagnostic Trouble Code";
CM_ SG_ 2566750462 DTC1 "Diagnostic Trouble Code";
CM_ BO_ 2566750974 "All Pending DTCs";
CM_ SG_ 2566750974 FlashRedStopLamp "This parameter provides the capability to flash the RSL (SPN 3039).";
CM_ SG_ 2566750974 FlashProtectLamp "This parameter provides the capability to flash the engine protect lamp (SPN 3041).";
CM_ SG_ 2566750974 FlashMalfuncIndicatorLamp "This parameter provides the capability to flash the MIL (SPN 3038).";
CM_ SG_ 2566750974 FlashAmberWarningLamp "This parameter provides the capability to flash the AWL (SPN 3040). ";
CM_ SG_ 2566750974 MalfunctionIndicatorLampStatus "A lamp used to relay only emissions-related trouble code information.";
CM_ SG_ 2566750974 AmberWarningLampStatus "This lamp is used to relay trouble code information that is reporting a problem with the vehicle system but the vehicle need
not be immediately stopped.";
CM_ SG_ 2566750974 RedStopLampState "This lamp is uesed to relay trouble code information that is of a severe enought condition that it warrants stopping the vehicle.";
CM_ SG_ 2566750974 ProtectLampStatus "This lamp is used to relay trouble code informatio that is reporting a problem with a vehicle system that is most
probably not electronic subsystem related.";
CM_ SG_ 2566750974 DTC5 "Diagnostic Trouble Code";
CM_ SG_ 2566750974 DTC4 "Diagnostic Trouble Code";
CM_ SG_ 2566750974 DTC3 "Diagnostic Trouble Code";
CM_ SG_ 2566750974 DTC2 "Diagnostic Trouble Code";
CM_ SG_ 2566750974 DTC1 "Diagnostic Trouble Code";
CM_ BO_ 2566754558 "Advertised Engine Torque Curve";
CM_ SG_ 2566754558 AETCTorqueValue "Engine torque value of the data points in PGN 64912 – Advertised Engine Torque Curve (AETC).";
CM_ SG_ 2566754558 NumberOfAETCDataPoints "Indicates the number of speed / torque data points contained in the Advertised Engine Torque Curve broadcast (AETC).";
CM_ SG_ 2566754558 AETCDataCollectionStandard "Indicates the standardized method by which torque data was obtained for the Advertised Engine Torque Curve (AETC).";
CM_ BO_ 2566749950 "Adaptive Front-Lighting System Status";
CM_ SG_ 2566749950 RightHeadlampLightDistribution "This parameter indicates what kind of light distribution is set by the AFS system for the right headlamp.";
CM_ SG_ 2566749950 LeftHeadlampLightDistribution "This parameter indicates what kind of light distribution is set by the AFS system for the left headlamp.";
CM_ SG_ 2566749950 RghtHeadlampDynamicBendingLight "This parameter indicates whether the dynamic bending light of the left headlamp is working properly.";
CM_ SG_ 2566749950 LeftHeadlampDynamicBendingLight "This parameter indicates whether the dynamic bending light of the left headlamp is working properly.";
CM_ BO_ 2566838539 "Auxiliary Input/Output Status 1";
CM_ SG_ 2566838539 AuxI_O16 "Identifies the current status of auxiliary input/output functions that are configured uniquely per application.";
CM_ SG_ 2566838539 AuxI_O15 "Identifies the current status of auxiliary input/output functions that are configured uniquely per application.";
CM_ SG_ 2566838539 AuxI_O14 "Identifies the current status of auxiliary input/output functions that are configured uniquely per application.";
CM_ SG_ 2566838539 AuxI_O13 "Identifies the current status of auxiliary input/output functions that are configured uniquely per application.";
CM_ SG_ 2566838539 AuxI_O12 "Identifies the current status of auxiliary input/output functions that are configured uniquely per application.";
CM_ SG_ 2566838539 AuxI_O11 "Identifies the current status of auxiliary input/output functions that are configured uniquely per application.";
CM_ SG_ 2566838539 AuxI_O10 "Identifies the current status of auxiliary input/output functions that are configured uniquely per application.";
CM_ SG_ 2566838539 AuxI_O09 "Identifies the current status of auxiliary input/output functions that are configured uniquely per application.";
CM_ SG_ 2566838539 AuxI_O08_GearboxNeutralPos_AUX "Identifies the current status of auxiliary input/output functions that are configured uniquely per application.";
CM_ SG_ 2566838539 AuxI_O07_TrailerABSFulOper_AUX "Identifies the current status of auxiliary input/output functions that are configured uniquely per application.";
CM_ SG_ 2566838539 AuxI_O06_TrailerABSDetected_AUX "Identifies the current status of auxiliary input/output functions that are configured uniquely per application.";
CM_ SG_ 2566838539 AuxI_O05_TrailerConnected_AUX "Identifies the current status of auxiliary input/output functions that are configured uniquely per application.";
CM_ SG_ 2566838539 AuxI_O04 "Identifies the current status of auxiliary input/output functions that are configured uniquely per application.";
CM_ SG_ 2566838539 AuxI_O03 "Identifies the current status of auxiliary input/output functions that are configured uniquely per application.";
CM_ SG_ 2566838539 AuxI_O01 "Identifies the current status of auxiliary input/output functions that are configured uniquely per application.";
CM_ SG_ 2566838539 AuxI_OChannel2 "Auxiliary channel of data (16 bit) read by the ECU.";
CM_ SG_ 2566838539 AuxI_OChannel1 "Auxiliary channel of data (16 bit) read by the ECU.";
CM_ BO_ 2561146622 "Auxiliary Input/Output Status 2";
CM_ SG_ 2561146622 AuxI_O45 "Identifies the current status of auxiliary input/output functions that are configured uniquely per application.";
CM_ SG_ 2561146622 AuxI_O46 "Identifies the current status of auxiliary input/output functions that are configured uniquely per application.";
CM_ SG_ 2561146622 AuxI_O47 "Identifies the current status of auxiliary input/output functions that are configured uniquely per application.";
CM_ SG_ 2561146622 AuxI_O48 "Identifies the current status of auxiliary input/output functions that are configured uniquely per application.";
CM_ SG_ 2561146622 AuxI_O41 "Identifies the current status of auxiliary input/output functions that are configured uniquely per application.";
CM_ SG_ 2561146622 AuxI_O42 "Identifies the current status of auxiliary input/output functions that are configured uniquely per application.";
CM_ SG_ 2561146622 AuxI_O43 "Identifies the current status of auxiliary input/output functions that are configured uniquely per application.";
CM_ SG_ 2561146622 AuxI_O44 "Identifies the current status of auxiliary input/output functions that are configured uniquely per application.";
CM_ SG_ 2561146622 AuxI_O37 "Identifies the current status of auxiliary input/output functions that are configured uniquely per application.";
CM_ SG_ 2561146622 AuxI_O38 "Identifies the current status of auxiliary input/output functions that are configured uniquely per application.";
CM_ SG_ 2561146622 AuxI_O39 "Identifies the current status of auxiliary input/output functions that are configured uniquely per application.";
CM_ SG_ 2561146622 AuxI_O40 "Identifies the current status of auxiliary input/output functions that are configured uniquely per application.";
CM_ SG_ 2561146622 AuxI_O33 "Identifies the current status of auxiliary input/output functions that are configured uniquely per application.";
CM_ SG_ 2561146622 AuxI_O34 "Identifies the current status of auxiliary input/output functions that are configured uniquely per application.";
CM_ SG_ 2561146622 AuxI_O35 "Identifies the current status of auxiliary input/output functions that are configured uniquely per application.";
CM_ SG_ 2561146622 AuxI_O36 "Identifies the current status of auxiliary input/output functions that are configured uniquely per application.";
CM_ SG_ 2561146622 AuxI_O29 "Identifies the current status of auxiliary input/output functions that are configured uniquely per application.";
CM_ SG_ 2561146622 AuxI_O30 "Identifies the current status of auxiliary input/output functions that are configured uniquely per application.";
CM_ SG_ 2561146622 AuxI_O31 "Identifies the current status of auxiliary input/output functions that are configured uniquely per application.";
CM_ SG_ 2561146622 AuxI_O32 "Identifies the current status of auxiliary input/output functions that are configured uniquely per application.";
CM_ SG_ 2561146622 AuxI_O25 "Identifies the current status of auxiliary input/output functions that are configured uniquely per application.";
CM_ SG_ 2561146622 AuxI_O26 "Identifies the current status of auxiliary input/output functions that are configured uniquely per application.";
CM_ SG_ 2561146622 AuxI_O27 "Identifies the current status of auxiliary input/output functions that are configured uniquely per application.";
CM_ SG_ 2561146622 AuxI_O28 "Identifies the current status of auxiliary input/output functions that are configured uniquely per application.";
CM_ SG_ 2561146622 AuxI_O21 "Identifies the current status of auxiliary input/output functions that are configured uniquely per application.";
CM_ SG_ 2561146622 AuxI_O22 "Identifies the current status of auxiliary input/output functions that are configured uniquely per application.";
CM_ SG_ 2561146622 AuxI_O23 "Identifies the current status of auxiliary input/output functions that are configured uniquely per application.";
CM_ SG_ 2561146622 AuxI_O24 "Identifies the current status of auxiliary input/output functions that are configured uniquely per application.";
CM_ SG_ 2561146622 AuxI_O17 "Identifies the current status of auxiliary input/output functions that are configured uniquely per application.";
CM_ SG_ 2561146622 AuxI_O18 "Identifies the current status of auxiliary input/output functions that are configured uniquely per application.";
CM_ SG_ 2561146622 AuxI_O19 "Identifies the current status of auxiliary input/output functions that are configured uniquely per application.";
CM_ SG_ 2561146622 AuxI_O20 "Identifies the current status of auxiliary input/output functions that are configured uniquely per application.";
CM_ BO_ 2561081086 "Auxiliary Input/Output Status 3";
CM_ SG_ 2561081086 AuxI_O77 "Identifies the current status of auxiliary input/output functions that are configured uniquely per application.";
CM_ SG_ 2561081086 AuxI_O78 "Identifies the current status of auxiliary input/output functions that are configured uniquely per application.";
CM_ SG_ 2561081086 AuxI_O79 "Identifies the current status of auxiliary input/output functions that are configured uniquely per application.";
CM_ SG_ 2561081086 AuxI_O80 "Identifies the current status of auxiliary input/output functions that are configured uniquely per application.";
CM_ SG_ 2561081086 AuxI_O73 "Identifies the current status of auxiliary input/output functions that are configured uniquely per application.";
CM_ SG_ 2561081086 AuxI_O74 "Identifies the current status of auxiliary input/output functions that are configured uniquely per application.";
CM_ SG_ 2561081086 AuxI_O75 "Identifies the current status of auxiliary input/output functions that are configured uniquely per application.";
CM_ SG_ 2561081086 AuxI_O76 "Identifies the current status of auxiliary input/output functions that are configured uniquely per application.";
CM_ SG_ 2561081086 AuxI_O69 "Identifies the current status of auxiliary input/output functions that are configured uniquely per application.";
CM_ SG_ 2561081086 AuxI_O70 "Identifies the current status of auxiliary input/output functions that are configured uniquely per application.";
CM_ SG_ 2561081086 AuxI_O71 "Identifies the current status of auxiliary input/output functions that are configured uniquely per application.";
CM_ SG_ 2561081086 AuxI_O72 "Identifies the current status of auxiliary input/output functions that are configured uniquely per application.";
CM_ SG_ 2561081086 AuxI_O65 "Identifies the current status of auxiliary input/output functions that are configured uniquely per application.";
CM_ SG_ 2561081086 AuxI_O66 "Identifies the current status of auxiliary input/output functions that are configured uniquely per application.";
CM_ SG_ 2561081086 AuxI_O67 "Identifies the current status of auxiliary input/output functions that are configured uniquely per application.";
CM_ SG_ 2561081086 AuxI_O68 "Identifies the current status of auxiliary input/output functions that are configured uniquely per application.";
CM_ SG_ 2561081086 AuxI_O61 "Identifies the current status of auxiliary input/output functions that are configured uniquely per application.";
CM_ SG_ 2561081086 AuxI_O62 "Identifies the current status of auxiliary input/output functions that are configured uniquely per application.";
CM_ SG_ 2561081086 AuxI_O63 "Identifies the current status of auxiliary input/output functions that are configured uniquely per application.";
CM_ SG_ 2561081086 AuxI_O64 "Identifies the current status of auxiliary input/output functions that are configured uniquely per application.";
CM_ SG_ 2561081086 AuxI_O57 "Identifies the current status of auxiliary input/output functions that are configured uniquely per application.";
CM_ SG_ 2561081086 AuxI_O58 "Identifies the current status of auxiliary input/output functions that are configured uniquely per application.";
CM_ SG_ 2561081086 AuxI_O59 "Identifies the current status of auxiliary input/output functions that are configured uniquely per application.";
CM_ SG_ 2561081086 AuxI_O60 "Identifies the current status of auxiliary input/output functions that are configured uniquely per application.";
CM_ SG_ 2561081086 AuxI_O53 "Identifies the current status of auxiliary input/output functions that are configured uniquely per application.";
CM_ SG_ 2561081086 AuxI_O54 "Identifies the current status of auxiliary input/output functions that are configured uniquely per application.";
CM_ SG_ 2561081086 AuxI_O55 "Identifies the current status of auxiliary input/output functions that are configured uniquely per application.";
CM_ SG_ 2561081086 AuxI_O56 "Identifies the current status of auxiliary input/output functions that are configured uniquely per application.";
CM_ SG_ 2561081086 AuxI_O49 "Identifies the current status of auxiliary input/output functions that are configured uniquely per application.";
CM_ SG_ 2561081086 AuxI_O50 "Identifies the current status of auxiliary input/output functions that are configured uniquely per application.";
CM_ SG_ 2561081086 AuxI_O51 "Identifies the current status of auxiliary input/output functions that are configured uniquely per application.";
CM_ SG_ 2561081086 AuxI_O52 "Identifies the current status of auxiliary input/output functions that are configured uniquely per application.";
CM_ BO_ 2561015550 "Auxiliary Input/Output Status 4";
CM_ SG_ 2561015550 AuxI_O92 "Identifies the current status of auxiliary input/output functions that are configured uniquely per application.";
CM_ SG_ 2561015550 AuxI_O85 "Identifies the current status of auxiliary input/output functions that are configured uniquely per application.";
CM_ SG_ 2561015550 AuxI_O86 "Identifies the current status of auxiliary input/output functions that are configured uniquely per application.";
CM_ SG_ 2561015550 AuxI_O87 "Identifies the current status of auxiliary input/output functions that are configured uniquely per application.";
CM_ SG_ 2561015550 AuxI_O88 "Identifies the current status of auxiliary input/output functions that are configured uniquely per application.";
CM_ SG_ 2561015550 AuxI_O81 "Identifies the current status of auxiliary input/output functions that are configured uniquely per application.";
CM_ SG_ 2561015550 AuxI_O82 "Identifies the current status of auxiliary input/output functions that are configured uniquely per application.";
CM_ SG_ 2561015550 AuxI_O83 "Identifies the current status of auxiliary input/output functions that are configured uniquely per application.";
CM_ SG_ 2561015550 AuxI_O84 "Identifies the current status of auxiliary input/output functions that are configured uniquely per application.";
CM_ SG_ 2561015550 AuxI_O109 "Identifies the current status of auxiliary input/output functions that are configured uniquely per application.";
CM_ SG_ 2561015550 AuxI_O110 "Identifies the current status of auxiliary input/output functions that are configured uniquely per application.";
CM_ SG_ 2561015550 AuxI_O111 "Identifies the current status of auxiliary input/output functions that are configured uniquely per application.";
CM_ SG_ 2561015550 AuxI_O112 "Identifies the current status of auxiliary input/output functions that are configured uniquely per application.";
CM_ SG_ 2561015550 AuxI_O105 "Identifies the current status of auxiliary input/output functions that are configured uniquely per application.";
CM_ SG_ 2561015550 AuxI_O106 "Identifies the current status of auxiliary input/output functions that are configured uniquely per application.";
CM_ SG_ 2561015550 AuxI_O107 "Identifies the current status of auxiliary input/output functions that are configured uniquely per application.";
CM_ SG_ 2561015550 AuxI_O108 "Identifies the current status of auxiliary input/output functions that are configured uniquely per application.";
CM_ SG_ 2561015550 AuxI_O101 "Identifies the current status of auxiliary input/output functions that are configured uniquely per application.";
CM_ SG_ 2561015550 AuxI_O102 "Identifies the current status of auxiliary input/output functions that are configured uniquely per application.";
CM_ SG_ 2561015550 AuxI_O103 "Identifies the current status of auxiliary input/output functions that are configured uniquely per application.";
CM_ SG_ 2561015550 AuxI_O104 "Identifies the current status of auxiliary input/output functions that are configured uniquely per application.";
CM_ SG_ 2561015550 AuxI_O97 "Identifies the current status of auxiliary input/output functions that are configured uniquely per application.";
CM_ SG_ 2561015550 AuxI_O98 "Identifies the current status of auxiliary input/output functions that are configured uniquely per application.";
CM_ SG_ 2561015550 AuxI_O99 "Identifies the current status of auxiliary input/output functions that are configured uniquely per application.";
CM_ SG_ 2561015550 AuxI_O100 "Identifies the current status of auxiliary input/output functions that are configured uniquely per application.";
CM_ SG_ 2561015550 AuxI_O93 "Identifies the current status of auxiliary input/output functions that are configured uniquely per application.";
CM_ SG_ 2561015550 AuxI_O94 "Identifies the current status of auxiliary input/output functions that are configured uniquely per application.";
CM_ SG_ 2561015550 AuxI_O95 "Identifies the current status of auxiliary input/output functions that are configured uniquely per application.";
CM_ SG_ 2561015550 AuxI_O96 "Identifies the current status of auxiliary input/output functions that are configured uniquely per application.";
CM_ SG_ 2561015550 AuxI_O89 "Identifies the current status of auxiliary input/output functions that are configured uniquely per application.";
CM_ SG_ 2561015550 AuxI_O90 "Identifies the current status of auxiliary input/output functions that are configured uniquely per application.";
CM_ SG_ 2561015550 AuxI_O91 "Identifies the current status of auxiliary input/output functions that are configured uniquely per application.";
CM_ BO_ 2566746622 "Brake actuator stroke status";
CM_ SG_ 2566746622 TrailerBrakeStrokeAxle5Right "Brake stroke status for right brake actuator on trailer axle 5.";
CM_ SG_ 2566746622 TrailerBrakeStrokeAxle5Left "Brake stroke status for left brake actuator on trailer axle 5.";
CM_ SG_ 2566746622 TrailerBrakeStrokeAxle4Right "Brake stroke status for right brake actuator on trailer axle 4.";
CM_ SG_ 2566746622 TrailerBrakeStrokeAxle4Left "Brake stroke status for left brake actuator on trailer axle 4.";
CM_ SG_ 2566746622 TrailerBrakeStrokeAxle3Right "Brake stroke status for right brake actuator on trailer axle 3.";
CM_ SG_ 2566746622 TrailerBrakeStrokeAxle3Left "Brake stroke status for left brake actuator on trailer axle 3.";
CM_ SG_ 2566746622 TrailerBrakeStrokeAxle2Right "Brake stroke status for right brake actuator on trailer axle 2.";
CM_ SG_ 2566746622 TrailerBrakeStrokeAxle2Left "Brake stroke status for left brake actuator on trailer axle 2.";
CM_ SG_ 2566746622 TrailerBrakeStrokeAxle1Right "Brake stroke status for right brake actuator on trailer axle 1.";
CM_ SG_ 2566746622 TrailerBrakeStrokeAxle1Left "Brake stroke status for left brake actuator on trailerr axle 1.";
CM_ SG_ 2566746622 TractorBrakeStrokeAxle5Right "Brake stroke status for right brake actuator on tractor axle 5.";
CM_ SG_ 2566746622 TractorBrakeStrokeAxle5Left "Brake stroke status for left brake actuator on tractor axle 5.";
CM_ SG_ 2566746622 TractorBrakeStrokeAxle4Right "Brake stroke status for right brake actuator on tractor axle 4.";
CM_ SG_ 2566746622 TractorBrakeStrokeAxle4Left "Brake stroke status for left brake actuator on tractor axle 4.";
CM_ SG_ 2566746622 TractorBrakeStrokeAxle3Right "Brake stroke status for right brake actuator on tractor axle 3.";
CM_ SG_ 2566746622 TractorBrakeStrokeAxle3Left "Brake stroke status for left brake actuator on tractor axle 3.";
CM_ SG_ 2566746622 TractorBrakeStrokeAxle2Right "Brake stroke status for right brake actuator on tractor axle 2.";
CM_ SG_ 2566746622 TractorBrakeStrokeAxle2Left "Brake stroke status for left brake actuator on tractor axle 2.";
CM_ SG_ 2566746622 TractorBrakeStrokeAxle1Right "Brake stroke status for right brake actuator on tractor axle 1.";
CM_ SG_ 2566746622 TractorBrakeStrokeAxle1Left "Brake stroke status for left brake actuator on tractor axle 1.";
CM_ BO_ 2566845950 "Ambient Conditions";
CM_ SG_ 2566845950 EngAirIntakeTemp "Temperature of air entering vehicle air induction system.";
CM_ SG_ 2566845950 BarometricPress "Absolute air pressure of the atmosphere.";
CM_ BO_ 2566840062 "Air Start Pressure";
CM_ SG_ 2566840062 EngAirStartPress "Gage pressure of air in an engine starting system that utilizes compressed air to provide the force required to rotate the";
CM_ BO_ 2566827568 "Air Supply Pressure";
CM_ SG_ 2566827568 ServiceBrakeCircuit2AirPress "The pneumatic pressure in the secondary service brake circuit or reservoir, supplying the front axle.";
CM_ SG_ 2566827568 ServiceBrakeCircuit1AirPress "The pneumatic pressure in the primary service brake circuit or reservoir, supplying the rear axle.";
CM_ SG_ 2566827568 AirCompressorStatus "Indicates whether the air compressor is actively compressing air.";
CM_ SG_ 2566827568 ParkingAnd_OrTrailerAirPress "The pneumatic pressure in the circuit or reservoir for the parking brake and/or the trailer supply.";
CM_ SG_ 2566827568 PneumaticSupplyPress "The pneumatic pressure in the main reservoir, sometimes referred to as the wet tank.";
CM_ BO_ 2566846974 "Axle Information";
CM_ SG_ 2566846974 SteerAxleLubePress "The steering axle lubricant pressure.";
CM_ SG_ 2566846974 SteerAxleTemp "Temperature of lubricant in steering axle.";
CM_ SG_ 2566846974 DriveAxleLubePress "The drive axle lubricant pressure with location determined by Drive Axle Location (SPN 930).";
CM_ SG_ 2566846974 DriveAxleTemp "Temperature of axle lubricant in drive axle.";
CM_ SG_ 2566846974 DriveAxleLiftAirPress "Gage pressure of air in system that utilizes compressed air to provide force between axle and frame.";
CM_ SG_ 2566846974 DriveAxleLocation "To identify to which of several similar devices (such as tires or fuel tanks) the information applies.";
CM_ BO_ 2633935614 "Alternate Fuel 2";
CM_ SG_ 2633935614 EngTurboWastegateValvePos "The position of the turbocharger wastegate valve (not the electronic wastegate control valve).";
CM_ SG_ 2633935614 EngGsMssFlwSnsrFelingCorrection "The amount of fuel the Gas Mass Flow Sensor is sensing should be added or subtracted compared to the maximum";
CM_ SG_ 2633935614 EngDsiredAbsIntakeManifoldPress "The desired absolute intake manifold pressure of the engine.";
CM_ SG_ 2633935614 EngGasFuelCorrectionFactor "A correction to a predefined gaseous fuel energy (expressed in energy per unit volume) represented as a percentage.";
CM_ BO_ 2566803745 "Adaptive Cruise Control, Operator Input";
CM_ SG_ 2566803745 ACCUsageDemand_ACC2 "This parameter indicates the drivers demand to activate or deactivate ACC keeping distance control.";
CM_ BO_ 2432593918 "Adaptive Cruise Control";
CM_ SG_ 2432593918 ForwardCollisionWarning "This parameter indicates if a collision is imminent and strong driver reaction either by braking hard or by an avoidance";
CM_ SG_ 2432593918 ACCDistanceAlertSignal "Signal to indicate to the operator that the ACC system is not able to maintain the distance to the target.";
CM_ SG_ 2432593918 ACCSystemShutoffWarning "Signal to warn the driver of system deactivation due to non-driver actions.";
CM_ SG_ 2432593918 ACCTargetDetected "Signal to indicate to the driver that the ACC system has detected a target.";
CM_ SG_ 2432593918 RoadCurvature "Estimated value of the current road curvature for use by the adaptive cruise control system.";
CM_ SG_ 2432593918 AdptveCruiseCtrlSetDistanceMode "Selected distance mode for adaptive cruise control.";
CM_ SG_ 2432593918 AdaptiveCruiseCtrlMode "This parameter is used to indicate the current state, or mode, of operation by the Adaptive Cruise Control (ACC) device.";
CM_ SG_ 2432593918 AdaptiveCruiseCtrlSetSpeed "Value of the desired (chosen) velocity of the adaptive cruise control system.";
CM_ SG_ 2432593918 DistanceToForwardVehicle "Distance to the preceding vehicle situated within 250 m in the same lane and moving in the same direction.";
CM_ SG_ 2432593918 SpeedOfForwardVehicle "Absolute velocity of the preceding vehicle situated within 250 m in the same lane and moving in the same direction.";
CM_ BO_ 2633935102 "Articulation Control";
CM_ SG_ 2633935102 ArticulationAngle "Angle of deflection of an articulated transit vehicle.";
CM_ BO_ 2633927934 "Auxiliary Analog Information";
CM_ SG_ 2633927934 RelativeHumidity "Measures humidity of combustion air prior to entry into turbocharger";
CM_ SG_ 2633927934 AuxLevel "Level measured by a sensor.";
CM_ SG_ 2633927934 AuxPress2 "Pressure measured by auxiliary pressure sensor #2.";
CM_ SG_ 2633927934 AuxPress1 "Pressure measured by auxiliary pressure sensor #1.";
CM_ SG_ 2633927934 AuxTemp2 "Temperature measured by auxiliary temperature sensor #2.";
CM_ SG_ 2633927934 AuxTemp1 "Temperature measured by auxiliary temperature sensor #1.";
CM_ BO_ 2566847998 "Alternate Fuel 1";
CM_ SG_ 2566847998 EngBlowerBypassValvePos "Relative position of the blower bypass valve.";
CM_ SG_ 2566847998 EngGasSupplyPress "Gage pressure of gas supply to fuel metering device.";
CM_ BO_ 2565406462 "Acknowledgment Message";
CM_ SG_ 2565406462 GroupFunctionValue "Group Function of PGN being acknowledged. This field identifies for a device the specific group function of a PGN being acknowledged or declined.  This field is not used if the PGN being acknowledged or declined is not a group function PGN.";
CM_ BO_ 2566803198 "Door Control 1";
CM_ SG_ 2566803198 Status2OfDoors "Composite indication of all bus door statuses.";
CM_ SG_ 2566803198 Ramp_WheelChairLiftPos "Signal which indicates the actual position of the ramp / wheel chair lift.";
CM_ SG_ 2566803198 PosOfDoors "Signal which indicates the actual position of the doors.";
CM_ BO_ 2565870334 "Fifth Wheel Smart Systems 1";
CM_ SG_ 2565870334 FifthWheelRollWarningIndicator "Indicates to the vehicle operator that the roll moment has exceeded a preset limit.";
CM_ SG_ 2565870334 FifthWheelRollMoment "Fifth wheel roll moment force - If the moment is positive, the trailer is rolling clockwise relative to the normal vehicle";
CM_ SG_ 2565870334 FifthWheelDrawbarForce "Fifth wheel drawbar force, with the trailer held stationary a positive force is generated by the vehicle pulling forward.";
CM_ SG_ 2565870334 FifthWheelVerticalForce "The amount of load being applied to the fifth wheel by the trailer.";
CM_ BO_ 2566762238 "Fifth Wheel Smart Systems 2";
CM_ SG_ 2566762238 FifthWheelSliderLockIndicator "Indicates to vehicle operator that the fifth wheel slider is in position and locked.";
CM_ SG_ 2566762238 FifthWheelSliderPos "Slider position measurement.";
CM_ SG_ 2566762238 FfthWhlLckCoupleStatusIndicator "Indicates results of coupling operation to the vehicle operator.";
CM_ SG_ 2566762238 FfthWhlLckRadyToCoupleIndicator "Indicates to the vehicle operator that the fifth wheel lock is open and ready to couple.";
CM_ SG_ 2566762238 FifthWheelErrorStatus "Fifth wheel error state which conveys information when coupling status is incomplete or bad.";
CM_ BO_ 2364543998 "Slope Sensor Information";
CM_ SG_ 2364543998 RollAndPitchMeasurementLatency "The estimated measurement latency of the measurement.";
CM_ SG_ 2364543998 PitchAndRollCompensated "Compensated mode for the pitch and roll measurements.";
CM_ SG_ 2364543998 PitchRateFigureOfMerit "Figure of merit for the pitch rate measurement.";
CM_ SG_ 2364543998 RollAngleFigureOfMerit "Figure of merit for roll angle measurement.";
CM_ SG_ 2364543998 PitchAngleFigureOfMerit "Figure of merit for pitch angle measurement.";
CM_ SG_ 2364543998 PitchRate "Pitch rate is the rate-of-change of the pitch angle over time, where the pitch angle vector is in the direction of travel of the";
CM_ SG_ 2364543998 RollAngle "The angle between the vehicle y-axis and the ground plane.";
CM_ SG_ 2364543998 PitchAngle "The angle between the vehicle x-axis and the ground plane.";
CM_ BO_ 2566846718 "Transmission Fluids 1";
CM_ SG_ 2566846718 TransOilLevelMeasurementStatus "Indicates if conditions are acceptable to obtain a valid transmission oil level measurement as conveyed in SPN 124";
CM_ SG_ 2566846718 TransOilLevelCountdownTimer "Once all vehicle conditions (such as vehicle stopped, etc) are met, some transmissions may require a ‘settling time’ to";
CM_ SG_ 2566846718 TransOilLevelHigh_Low "Amount of current volume of transmission sump oil compared to recommended volume.";
CM_ SG_ 2566846718 TransOilTemp "Temperature of the transmission lubricant.";
CM_ SG_ 2566846718 TransOilPress "Gage pressure of lubrication fluid in transmission, measured after pump.";
CM_ SG_ 2566846718 TransFilterDiffPress "Change in transmission fluid pressure, measured after the filter, due to accumulation of solid or semisolid material on or in";
CM_ SG_ 2566846718 TransOilLevel "Ratio of volume of transmission sump oil to recommended volume.";
CM_ SG_ 2566846718 ClutchPress "Gage pressure of oil within a wet clutch.";
CM_ BO_ 2566846462 "Vehicle Electrical Power 1";
CM_ SG_ 2566846462 ChargingSystemPotential "Electrical potential measured at the charging system output.";
CM_ SG_ 2566846462 AltCurrent "Measure of electrical current flow from the alternator.";
CM_ SG_ 2566846462 NetBatteryCurrent "Net flow of electrical current into/out of the battery or batteries.";
CM_ SG_ 2566846462 KeyswitchBatteryPotential "Battery potential measured at the input of the electronic control unit supplied through a keyswitch or similar switching";
CM_ SG_ 2566846462 BatteryPotential_PowerInput1 "This parameter measures the first source of battery potential as measured at the input of the ECM/actuator etc.";
CM_ BO_ 2566760702 "Wireless Communications Message 2";
CM_ SG_ 2566760702 WrlessCommunicationNetworkType2 "Type of Wireless Communication Network";
CM_ SG_ 2566760702 NetworkSignalStrength2 "Indicates the signal strength for the wireless communications network type.";
CM_ SG_ 2566760702 NetworkAntennaStatus2 "Indicates the status of the antenna for the wireless communications network type";
CM_ SG_ 2566760702 NetworkServiceStatus2 "Indicates the status of the Service for the wireless communications network type";
CM_ SG_ 2566760702 NetworkTransceiverStatus2 "Indicates the status of the transceiver for the wireless communications network type";
CM_ BO_ 2566760958 "Wireless Communications Message 1";
CM_ SG_ 2566760958 WrlessCommunicationNetworkType1 "Type of Wireless Communication Network";
CM_ SG_ 2566760958 NetworkSignalStrength1 "Indicates the signal strength for the wireless communications network type.";
CM_ SG_ 2566760958 NetworkAntennaStatus1 "Indicates the status of the antenna for the wireless communications network type";
CM_ SG_ 2566760958 NetworkServiceStatus1 "Indicates the status of the Service for the wireless communications network type";
CM_ SG_ 2566760958 NetworkTransceiverStatus1 "Indicates the status of the transceiver for the wireless communications network type";
CM_ BO_ 2633869310 "Voltage Regulator Operating Mode";
CM_ SG_ 2633869310 VoltageRegulatorEnabled "State signal indicating the Voltage regulator enabled.";
CM_ SG_ 2633869310 VoltageRegulatorSoftStartState "State signal indicating the mode of the Voltage regulator soft start function.";
CM_ SG_ 2633869310 VltgRgltrUndrfrqncyCmpnstnEnbld "State signal indicating the operating mode for underfrequency compensation.";
CM_ SG_ 2633869310 VltgRglatorLoadCompensationMode "State signal indicating the voltage regulator load compensation mode.";
CM_ BO_ 2365433598 "Voltage regulator excitation status";
CM_ SG_ 2365433598 GeneratorExcitationFieldCurrent "Measured signal that represents the generator excitation field current.";
CM_ SG_ 2365433598 GeneratorExcitationFieldVoltage "Measured signal that represents the generator excitation field voltage.";
BA_DEF_ SG_  "SigType" ENUM  "Default","Range","RangeSigned","ASCII","Discrete","Control","ReferencePGN","DTC","StringDelimiter","StringLength","StringLengthControl";
BA_DEF_ SG_  "GenSigStartValue" INT 0 10000;
BA_DEF_ SG_  "GenSigSendType" ENUM  "Cyclic","OnWrite","reserved","OnChange","reserved","reserved","reserved","NoSigSendType";
BA_DEF_ SG_  "GenSigILSupport" ENUM  "Yes","No";
BA_DEF_ SG_  "GenSigEVName" STRING ;
BA_DEF_ SG_  "SPN" INT 0 524287;
BA_DEF_ BO_  "GenMsgStartDelayTime" INT 0 100000;
BA_DEF_ BO_  "GenMsgILSupport" ENUM  "Yes","No";
BA_DEF_ BO_  "GenMsgDelayTime" INT 0 1000;
BA_DEF_ BO_  "GenMsgRequestable" INT 0 1;
BA_DEF_ BO_  "GenMsgSendType" ENUM  "cyclic","Spontaneus","cyclicIfActive","reserved","reserved","reserved","reserved","reserved","noMsgSendType","OnRequest";
BA_DEF_ BO_  "VFrameFormat" ENUM  "StandardCAN","ExtendedCAN","reserved","J1939PG";
BA_DEF_ BO_  "GenMsgCycleTime" INT 0 3600000;
BA_DEF_ SG_  "SystemSignalLongSymbol" STRING ;
BA_DEF_DEF_  "SigType" "Default";
BA_DEF_DEF_  "GenSigStartValue" 0;
BA_DEF_DEF_  "GenSigSendType" "NoSigSendType";
BA_DEF_DEF_  "GenSigILSupport" "Yes";
BA_DEF_DEF_  "GenSigEVName" "Env@Nodename_@Signame";
BA_DEF_DEF_  "SPN" 0;
BA_DEF_DEF_  "GenMsgStartDelayTime" 0;
BA_DEF_DEF_  "GenMsgILSupport" "Yes";
BA_DEF_DEF_  "GenMsgDelayTime" 0;
BA_DEF_DEF_  "GenMsgRequestable" 1;
BA_DEF_DEF_  "GenMsgSendType" "noMsgSendType";
BA_DEF_DEF_  "VFrameFormat" "J1939PG";
BA_DEF_DEF_  "GenMsgCycleTime" 0;
BA_DEF_DEF_  "SystemSignalLongSymbol" "";
BA_ "GenMsgStartDelayTime" BO_ 2565928476 8;
BA_ "GenMsgCycleTime" BO_ 2499630078 500;
BA_ "GenMsgSendType" BO_ 2499630078 0;
BA_ "GenMsgSendType" BO_ 2566838539 0;
BA_ "GenMsgCycleTime" BO_ 2566838539 100;
BA_ "GenMsgCycleTime" BO_ 2566746622 1000;
BA_ "GenMsgSendType" BO_ 2566746622 0;
BA_ "GenMsgCycleTime" BO_ 2566845950 1000;
BA_ "GenMsgSendType" BO_ 2566845950 0;
BA_ "GenMsgCycleTime" BO_ 2566827568 1000;
BA_ "GenMsgSendType" BO_ 2566827568 0;
BA_ "GenMsgCycleTime" BO_ 2566846974 1000;
BA_ "GenMsgSendType" BO_ 2566846974 0;
BA_ "GenMsgCycleTime" BO_ 2566803745 250;
BA_ "GenMsgSendType" BO_ 2566803745 0;
BA_ "GenMsgCycleTime" BO_ 2432593918 100;
BA_ "GenMsgSendType" BO_ 2432593918 0;
BA_ "GenMsgCycleTime" BO_ 2566847998 500;
BA_ "GenMsgSendType" BO_ 2566847998 0;
BA_ "GenMsgCycleTime" BO_ 2565406462 200;
BA_ "GenMsgCycleTime" BO_ 2566803198 100;
BA_ "GenMsgSendType" BO_ 2566803198 0;
BA_ "GenMsgCycleTime" BO_ 2565870334 50;
BA_ "GenMsgSendType" BO_ 2565870334 0;
BA_ "GenMsgCycleTime" BO_ 2364543998 10;
BA_ "GenMsgSendType" BO_ 2364543998 0;
BA_ "GenMsgCycleTime" BO_ 2566846718 1000;
BA_ "GenMsgSendType" BO_ 2566846718 0;
BA_ "GenMsgCycleTime" BO_ 2566846462 1000;
BA_ "GenMsgSendType" BO_ 2566846462 0;
BA_ "GenMsgCycleTime" BO_ 2633869310 1000;
BA_ "GenMsgSendType" BO_ 2633869310 0;
BA_ "GenMsgCycleTime" BO_ 2365433598 100;
BA_ "GenMsgSendType" BO_ 2365433598 0;
BA_ "GenSigStartValue" SG_ 2565928476 Stub_FormOfWay 3;
BA_ "GenSigStartValue" SG_ 2565928476 Stub_TurnAngle 255;
BA_ "SigType" SG_ 2565928476 Stub_TurnAngle 1;
BA_ "SigType" SG_ 2565928476 Stub_RightOfWay 4;
BA_ "GenSigStartValue" SG_ 2565928476 Stub_RightOfWay 3;
BA_ "GenSigStartValue" SG_ 2565928476 Stub_RelProb 31;
BA_ "SigType" SG_ 2565928476 Stub_PartOfCalcRoute 4;
BA_ "GenSigStartValue" SG_ 2565928476 Stub_PartOfCalcRoute 3;
BA_ "GenSigStartValue" SG_ 2565928476 Stub_Ofs 8191;
BA_ "SigType" SG_ 2565928476 Stub_NumOfLanesInOppDir 4;
BA_ "GenSigStartValue" SG_ 2565928476 Stub_NumOfLanesInOppDir 3;
BA_ "GenSigStartValue" SG_ 2565928476 Stub_NumOfLanesInDrivDir 7;
BA_ "GenSigStartValue" SG_ 2565928476 Stub_FunctRoadClass 7;
BA_ "SigType" SG_ 2565928476 Stub_ComplexInters 4;
BA_ "GenSigStartValue" SG_ 2565928476 Stub_ComplexInters 3;
BA_ "SigType" SG_ 2565928476 Seg_Tunnel 4;
BA_ "GenSigStartValue" SG_ 2565928476 Seg_Tunnel 3;
BA_ "GenSigStartValue" SG_ 2565928476 Seg_RelProb 31;
BA_ "SigType" SG_ 2565928476 Seg_PartOfCalcRoute 4;
BA_ "GenSigStartValue" SG_ 2565928476 Seg_PartOfCalcRoute 3;
BA_ "GenSigStartValue" SG_ 2565928476 Seg_Ofs 8191;
BA_ "SigType" SG_ 2565928476 Seg_NumOfLanesInOppDir 4;
BA_ "GenSigStartValue" SG_ 2565928476 Seg_NumOfLanesInOppDir 3;
BA_ "GenSigStartValue" SG_ 2565928476 Seg_NumOfLanesInDrivDir 7;
BA_ "GenSigStartValue" SG_ 2565928476 Seg_FunctRoadClass 7;
BA_ "GenSigStartValue" SG_ 2565928476 Seg_FormOfWay 3;
BA_ "GenSigStartValue" SG_ 2565928476 Seg_EffSpeedLimType 7;
BA_ "GenSigStartValue" SG_ 2565928476 Seg_EffSpeedLim 31;
BA_ "SigType" SG_ 2565928476 Seg_DividedRoad 4;
BA_ "GenSigStartValue" SG_ 2565928476 Seg_DividedRoad 3;
BA_ "SigType" SG_ 2565928476 Seg_ComplexInters 4;
BA_ "GenSigStartValue" SG_ 2565928476 Seg_ComplexInters 3;
BA_ "SigType" SG_ 2565928476 Seg_BuiltUpArea 4;
BA_ "GenSigStartValue" SG_ 2565928476 Seg_BuiltUpArea 3;
BA_ "SigType" SG_ 2565928476 Seg_Bridge 4;
BA_ "GenSigStartValue" SG_ 2565928476 Seg_Bridge 3;
BA_ "GenSigStartValue" SG_ 2565928476 ProfShort_Val1_9_RsvdForStdTypes 1023;
BA_ "GenSigStartValue" SG_ 2565928476 ProfShort_Val1_8_HeadChg 1023;
BA_ "GenSigStartValue" SG_ 2565928476 ProfShort_Val1_7_VarSpeedSignPos 1023;
BA_ "GenSigStartValue" SG_ 2565928476 ProfShort_Val1_6_RoadCond 1023;
BA_ "GenSigStartValue" SG_ 2565928476 ProfShort_Val1_5_RoadAcc 1023;
BA_ "GenSigStartValue" SG_ 2565928476 ProfShort_Val1_4_Slope 1023;
BA_ "GenSigStartValue" SG_ 2565928476 ProfShort_Val1_3_Slope 1023;
BA_ "GenSigStartValue" SG_ 2565928476 ProfShort_Val1_2_RouteNumTypes 1023;
BA_ "GenSigStartValue" SG_ 2565928476 ProfShort_Val1_1_Curv 1023;
BA_ "GenSigStartValue" SG_ 2565928476 ProfShort_Val1_16_RsvdForSysSpec 1023;
BA_ "GenSigStartValue" SG_ 2565928476 ProfShort_Val0_9_RsvdForStdTypes 1023;
BA_ "GenSigStartValue" SG_ 2565928476 ProfShort_Val0_8_HeadChg 254;
BA_ "GenSigStartValue" SG_ 2565928476 ProfShort_Val0_6_RoadCond 1023;
BA_ "GenSigStartValue" SG_ 2565928476 ProfShort_Val0_4_Slope 1023;
BA_ "GenSigStartValue" SG_ 2565928476 ProfShort_Val0_3_Slope 1023;
BA_ "GenSigStartValue" SG_ 2565928476 ProfShort_Val0_1_Curv 1023;
BA_ "GenSigStartValue" SG_ 2565928476 ProfShort_Val0_16_RsvdForSysSpec 1023;
BA_ "GenSigStartValue" SG_ 2565928476 ProfShort_Ofs 8191;
BA_ "SigType" SG_ 2565928476 ProfShort_Accur 4;
BA_ "GenSigStartValue" SG_ 2565928476 ProfShort_Accur 3;
BA_ "SigType" SG_ 2565928476 ProfLong_Val2Lat 1;
BA_ "SigType" SG_ 2565928476 ProfLong_Val1Long 1;
BA_ "GenSigStartValue" SG_ 2565928476 ProfLong_Ofs 8191;
BA_ "GenSigStartValue" SG_ 2565928476 Pos_Speed 511;
BA_ "SigType" SG_ 2565928476 Pos_RelHead 1;
BA_ "GenSigStartValue" SG_ 2565928476 Pos_RelHead 255;
BA_ "GenSigStartValue" SG_ 2565928476 Pos_PosProb 31;
BA_ "GenSigStartValue" SG_ 2565928476 Pos_PosConf 7;
BA_ "GenSigStartValue" SG_ 2565928476 Pos_PosAge 511;
BA_ "GenSigStartValue" SG_ 2565928476 Pos_Ofs 8191;
BA_ "GenSigStartValue" SG_ 2565928476 MsgType 6;
BA_ "GenSigStartValue" SG_ 2565928476 Meta_MapProvider 7;
BA_ "GenSigStartValue" SG_ 2565928476 Meta_DrivSide 1;
BA_ "SPN" SG_ 2566741502 FlashRedStopLamp 3039;
BA_ "SigType" SG_ 2566741502 FlashRedStopLamp 4;
BA_ "SPN" SG_ 2566741502 FlashProtectLamp 3041;
BA_ "SigType" SG_ 2566741502 FlashProtectLamp 4;
BA_ "SPN" SG_ 2566741502 FlashMalfuncIndicatorLamp 3038;
BA_ "SigType" SG_ 2566741502 FlashMalfuncIndicatorLamp 4;
BA_ "SPN" SG_ 2566741502 FlashAmberWarningLamp 3040;
BA_ "SigType" SG_ 2566741502 FlashAmberWarningLamp 4;
BA_ "SPN" SG_ 2566741502 MalfunctionIndicatorLampStatus 1213;
BA_ "SigType" SG_ 2566741502 MalfunctionIndicatorLampStatus 4;
BA_ "SPN" SG_ 2566741502 AmberWarningLampStatus 624;
BA_ "SigType" SG_ 2566741502 AmberWarningLampStatus 4;
BA_ "SPN" SG_ 2566741502 RedStopLampState 623;
BA_ "SigType" SG_ 2566741502 RedStopLampState 4;
BA_ "SPN" SG_ 2566741502 ProtectLampStatus 987;
BA_ "SigType" SG_ 2566741502 ProtectLampStatus 4;
BA_ "SigType" SG_ 2566741502 DTC5 7;
BA_ "SigType" SG_ 2566741502 DTC4 7;
BA_ "SigType" SG_ 2566741502 DTC3 7;
BA_ "SigType" SG_ 2566741502 DTC2 7;
BA_ "SigType" SG_ 2566741502 DTC1 7;
BA_ "SPN" SG_ 2566741758 FlashRedStopLamp 3039;
BA_ "SigType" SG_ 2566741758 FlashRedStopLamp 4;
BA_ "SPN" SG_ 2566741758 FlashProtectLamp 3041;
BA_ "SigType" SG_ 2566741758 FlashProtectLamp 4;
BA_ "SPN" SG_ 2566741758 FlashMalfuncIndicatorLamp 3038;
BA_ "SigType" SG_ 2566741758 FlashMalfuncIndicatorLamp 4;
BA_ "SPN" SG_ 2566741758 FlashAmberWarningLamp 3040;
BA_ "SigType" SG_ 2566741758 FlashAmberWarningLamp 4;
BA_ "SPN" SG_ 2566741758 MalfunctionIndicatorLampStatus 1213;
BA_ "SigType" SG_ 2566741758 MalfunctionIndicatorLampStatus 4;
BA_ "SPN" SG_ 2566741758 AmberWarningLampStatus 624;
BA_ "SigType" SG_ 2566741758 AmberWarningLampStatus 4;
BA_ "SPN" SG_ 2566741758 RedStopLampState 623;
BA_ "SigType" SG_ 2566741758 RedStopLampState 4;
BA_ "SPN" SG_ 2566741758 ProtectLampStatus 987;
BA_ "SigType" SG_ 2566741758 ProtectLampStatus 4;
BA_ "SigType" SG_ 2566741758 DTC5 7;
BA_ "SigType" SG_ 2566741758 DTC4 7;
BA_ "SigType" SG_ 2566741758 DTC3 7;
BA_ "SigType" SG_ 2566741758 DTC2 7;
BA_ "SigType" SG_ 2566741758 DTC1 7;
BA_ "SPN" SG_ 2566742014 FlashRedStopLamp 3039;
BA_ "SigType" SG_ 2566742014 FlashRedStopLamp 4;
BA_ "SPN" SG_ 2566742014 FlashProtectLamp 3041;
BA_ "SigType" SG_ 2566742014 FlashProtectLamp 4;
BA_ "SPN" SG_ 2566742014 FlashMalfuncIndicatorLamp 3038;
BA_ "SigType" SG_ 2566742014 FlashMalfuncIndicatorLamp 4;
BA_ "SPN" SG_ 2566742014 FlashAmberWarningLamp 3040;
BA_ "SigType" SG_ 2566742014 FlashAmberWarningLamp 4;
BA_ "SPN" SG_ 2566742014 MalfunctionIndicatorLampStatus 1213;
BA_ "SigType" SG_ 2566742014 MalfunctionIndicatorLampStatus 4;
BA_ "SPN" SG_ 2566742014 AmberWarningLampStatus 624;
BA_ "SigType" SG_ 2566742014 AmberWarningLampStatus 4;
BA_ "SPN" SG_ 2566742014 RedStopLampState 623;
BA_ "SigType" SG_ 2566742014 RedStopLampState 4;
BA_ "SPN" SG_ 2566742014 ProtectLampStatus 987;
BA_ "SigType" SG_ 2566742014 ProtectLampStatus 4;
BA_ "SigType" SG_ 2566742014 DTC5 7;
BA_ "SigType" SG_ 2566742014 DTC4 7;
BA_ "SigType" SG_ 2566742014 DTC3 7;
BA_ "SigType" SG_ 2566742014 DTC2 7;
BA_ "SigType" SG_ 2566742014 DTC1 7;
BA_ "SPN" SG_ 2560622334 FlashRedStopLamp 3039;
BA_ "SigType" SG_ 2560622334 FlashRedStopLamp 4;
BA_ "SPN" SG_ 2560622334 FlashProtectLamp 3041;
BA_ "SigType" SG_ 2560622334 FlashProtectLamp 4;
BA_ "SPN" SG_ 2560622334 FlashMalfuncIndicatorLamp 3038;
BA_ "SigType" SG_ 2560622334 FlashMalfuncIndicatorLamp 4;
BA_ "SPN" SG_ 2560622334 FlashAmberWarningLamp 3040;
BA_ "SigType" SG_ 2560622334 FlashAmberWarningLamp 4;
BA_ "SPN" SG_ 2560622334 MalfunctionIndicatorLampStatus 1213;
BA_ "SigType" SG_ 2560622334 MalfunctionIndicatorLampStatus 4;
BA_ "SPN" SG_ 2560622334 AmberWarningLampStatus 624;
BA_ "SigType" SG_ 2560622334 AmberWarningLampStatus 4;
BA_ "SPN" SG_ 2560622334 RedStopLampState 623;
BA_ "SigType" SG_ 2560622334 RedStopLampState 4;
BA_ "SPN" SG_ 2560622334 ProtectLampStatus 987;
BA_ "SigType" SG_ 2560622334 ProtectLampStatus 4;
BA_ "SigType" SG_ 2560622334 DTC5 7;
BA_ "SigType" SG_ 2560622334 DTC4 7;
BA_ "SigType" SG_ 2560622334 DTC3 7;
BA_ "SigType" SG_ 2560622334 DTC2 7;
BA_ "SigType" SG_ 2560622334 DTC1 7;
BA_ "SPN" SG_ 2566744062 ZeroNetVehicleWeightChange 4075;
BA_ "SigType" SG_ 2566744062 ZeroNetVehicleWeightChange 4;
BA_ "SPN" SG_ 2499630078 EngExhaustGasTempAverageBank2 4152;
BA_ "SigType" SG_ 2499630078 EngExhaustGasTempAverageBank2 1;
BA_ "SPN" SG_ 2499630078 EngExhaustGasTempAverageBank1 4153;
BA_ "SigType" SG_ 2499630078 EngExhaustGasTempAverageBank1 1;
BA_ "SPN" SG_ 2499630078 EngExhaustGasTempAverage 4151;
BA_ "SigType" SG_ 2499630078 EngExhaustGasTempAverage 1;
BA_ "SPN" SG_ 2560556798 PermanentDTCs 4108;
BA_ "SigType" SG_ 2560556798 PermanentDTCs 1;
BA_ "SPN" SG_ 2560556798 PreviouslyMILOnDTCs 4107;
BA_ "SigType" SG_ 2560556798 PreviouslyMILOnDTCs 1;
BA_ "SPN" SG_ 2560556798 MILOnDTCs 4106;
BA_ "SigType" SG_ 2560556798 MILOnDTCs 1;
BA_ "SPN" SG_ 2560556798 AllPendingDTCs 4105;
BA_ "SigType" SG_ 2560556798 AllPendingDTCs 1;
BA_ "SPN" SG_ 2560556798 PendingDTCs 4104;
BA_ "SigType" SG_ 2560556798 PendingDTCs 1;
BA_ "SPN" SG_ 2566750462 FlashRedStopLamp 3039;
BA_ "SigType" SG_ 2566750462 FlashRedStopLamp 4;
BA_ "SPN" SG_ 2566750462 FlashProtectLamp 3041;
BA_ "SigType" SG_ 2566750462 FlashProtectLamp 4;
BA_ "SPN" SG_ 2566750462 FlashMalfuncIndicatorLamp 3038;
BA_ "SigType" SG_ 2566750462 FlashMalfuncIndicatorLamp 4;
BA_ "SPN" SG_ 2566750462 FlashAmberWarningLamp 3040;
BA_ "SigType" SG_ 2566750462 FlashAmberWarningLamp 4;
BA_ "SPN" SG_ 2566750462 MalfunctionIndicatorLampStatus 1213;
BA_ "SigType" SG_ 2566750462 MalfunctionIndicatorLampStatus 4;
BA_ "SPN" SG_ 2566750462 AmberWarningLampStatus 624;
BA_ "SigType" SG_ 2566750462 AmberWarningLampStatus 4;
BA_ "SPN" SG_ 2566750462 RedStopLampState 623;
BA_ "SigType" SG_ 2566750462 RedStopLampState 4;
BA_ "SPN" SG_ 2566750462 ProtectLampStatus 987;
BA_ "SigType" SG_ 2566750462 ProtectLampStatus 4;
BA_ "SigType" SG_ 2566750462 DTC5 7;
BA_ "SigType" SG_ 2566750462 DTC4 7;
BA_ "SigType" SG_ 2566750462 DTC3 7;
BA_ "SigType" SG_ 2566750462 DTC2 7;
BA_ "SigType" SG_ 2566750462 DTC1 7;
BA_ "SPN" SG_ 2566750974 FlashRedStopLamp 3039;
BA_ "SigType" SG_ 2566750974 FlashRedStopLamp 4;
BA_ "SPN" SG_ 2566750974 FlashProtectLamp 3041;
BA_ "SigType" SG_ 2566750974 FlashProtectLamp 4;
BA_ "SPN" SG_ 2566750974 FlashMalfuncIndicatorLamp 3038;
BA_ "SigType" SG_ 2566750974 FlashMalfuncIndicatorLamp 4;
BA_ "SPN" SG_ 2566750974 FlashAmberWarningLamp 3040;
BA_ "SigType" SG_ 2566750974 FlashAmberWarningLamp 4;
BA_ "SPN" SG_ 2566750974 MalfunctionIndicatorLampStatus 1213;
BA_ "SigType" SG_ 2566750974 MalfunctionIndicatorLampStatus 4;
BA_ "SPN" SG_ 2566750974 AmberWarningLampStatus 624;
BA_ "SigType" SG_ 2566750974 AmberWarningLampStatus 4;
BA_ "SPN" SG_ 2566750974 RedStopLampState 623;
BA_ "SigType" SG_ 2566750974 RedStopLampState 4;
BA_ "SPN" SG_ 2566750974 ProtectLampStatus 987;
BA_ "SigType" SG_ 2566750974 ProtectLampStatus 4;
BA_ "SigType" SG_ 2566750974 DTC5 7;
BA_ "SigType" SG_ 2566750974 DTC4 7;
BA_ "SigType" SG_ 2566750974 DTC3 7;
BA_ "SigType" SG_ 2566750974 DTC2 7;
BA_ "SigType" SG_ 2566750974 DTC1 7;
BA_ "SPN" SG_ 2566754558 AETCSpeedValue 3560;
BA_ "SPN" SG_ 2566754558 AETCTorqueValue 3561;
BA_ "SigType" SG_ 2566754558 AETCTorqueValue 1;
BA_ "SPN" SG_ 2566754558 NumberOfAETCDataPoints 3559;
BA_ "SPN" SG_ 2566754558 AETCDataCollectionStandard 3558;
BA_ "SigType" SG_ 2566754558 AETCDataCollectionStandard 4;
BA_ "SPN" SG_ 2566749950 RightHeadlampLightDistribution 3694;
BA_ "SigType" SG_ 2566749950 RightHeadlampLightDistribution 4;
BA_ "SPN" SG_ 2566749950 LeftHeadlampLightDistribution 3693;
BA_ "SigType" SG_ 2566749950 LeftHeadlampLightDistribution 4;
BA_ "SPN" SG_ 2566749950 RghtHeadlampDynamicBendingLight 3692;
BA_ "SPN" SG_ 2566749950 LeftHeadlampDynamicBendingLight 3691;
BA_ "SPN" SG_ 2566838539 AuxI_O16 716;
BA_ "SigType" SG_ 2566838539 AuxI_O16 4;
BA_ "GenSigStartValue" SG_ 2566838539 AuxI_O16 3;
BA_ "SPN" SG_ 2566838539 AuxI_O15 715;
BA_ "SigType" SG_ 2566838539 AuxI_O15 4;
BA_ "GenSigStartValue" SG_ 2566838539 AuxI_O15 3;
BA_ "SPN" SG_ 2566838539 AuxI_O14 714;
BA_ "SigType" SG_ 2566838539 AuxI_O14 4;
BA_ "GenSigStartValue" SG_ 2566838539 AuxI_O14 3;
BA_ "SPN" SG_ 2566838539 AuxI_O13 713;
BA_ "SigType" SG_ 2566838539 AuxI_O13 4;
BA_ "GenSigStartValue" SG_ 2566838539 AuxI_O13 3;
BA_ "SPN" SG_ 2566838539 AuxI_O12 712;
BA_ "SigType" SG_ 2566838539 AuxI_O12 4;
BA_ "GenSigStartValue" SG_ 2566838539 AuxI_O12 3;
BA_ "SPN" SG_ 2566838539 AuxI_O11 711;
BA_ "SigType" SG_ 2566838539 AuxI_O11 4;
BA_ "GenSigStartValue" SG_ 2566838539 AuxI_O11 3;
BA_ "SPN" SG_ 2566838539 AuxI_O10 710;
BA_ "SigType" SG_ 2566838539 AuxI_O10 4;
BA_ "GenSigStartValue" SG_ 2566838539 AuxI_O10 3;
BA_ "SPN" SG_ 2566838539 AuxI_O09 709;
BA_ "SigType" SG_ 2566838539 AuxI_O09 4;
BA_ "GenSigStartValue" SG_ 2566838539 AuxI_O09 3;
BA_ "GenSigStartValue" SG_ 2566838539 AuxI_O08_GearboxNeutralPos_AUX 3;
BA_ "SPN" SG_ 2566838539 AuxI_O08_GearboxNeutralPos_AUX 708;
BA_ "SigType" SG_ 2566838539 AuxI_O08_GearboxNeutralPos_AUX 4;
BA_ "GenSigStartValue" SG_ 2566838539 AuxI_O07_TrailerABSFulOper_AUX 3;
BA_ "SPN" SG_ 2566838539 AuxI_O07_TrailerABSFulOper_AUX 707;
BA_ "SigType" SG_ 2566838539 AuxI_O07_TrailerABSFulOper_AUX 4;
BA_ "GenSigStartValue" SG_ 2566838539 AuxI_O06_TrailerABSDetected_AUX 3;
BA_ "SPN" SG_ 2566838539 AuxI_O06_TrailerABSDetected_AUX 706;
BA_ "SigType" SG_ 2566838539 AuxI_O06_TrailerABSDetected_AUX 4;
BA_ "SPN" SG_ 2566838539 AuxI_O05_TrailerConnected_AUX 705;
BA_ "SigType" SG_ 2566838539 AuxI_O05_TrailerConnected_AUX 4;
BA_ "GenSigStartValue" SG_ 2566838539 AuxI_O05_TrailerConnected_AUX 3;
BA_ "SPN" SG_ 2566838539 AuxI_O04 704;
BA_ "SigType" SG_ 2566838539 AuxI_O04 4;
BA_ "GenSigStartValue" SG_ 2566838539 AuxI_O04 3;
BA_ "SPN" SG_ 2566838539 AuxI_O03 703;
BA_ "SigType" SG_ 2566838539 AuxI_O03 4;
BA_ "GenSigStartValue" SG_ 2566838539 AuxI_O03 3;
BA_ "SPN" SG_ 2566838539 AuxI_O01 701;
BA_ "SigType" SG_ 2566838539 AuxI_O01 4;
BA_ "GenSigStartValue" SG_ 2566838539 AuxI_O01 3;
BA_ "SPN" SG_ 2566838539 AuxI_OChannel2 1084;
BA_ "SigType" SG_ 2566838539 AuxI_OChannel2 1;
BA_ "SPN" SG_ 2566838539 AuxI_OChannel1 1083;
BA_ "SigType" SG_ 2566838539 AuxI_OChannel1 1;
BA_ "SPN" SG_ 2561146622 AuxI_O45 3868;
BA_ "SigType" SG_ 2561146622 AuxI_O45 4;
BA_ "SPN" SG_ 2561146622 AuxI_O46 3869;
BA_ "SigType" SG_ 2561146622 AuxI_O46 4;
BA_ "SPN" SG_ 2561146622 AuxI_O47 3870;
BA_ "SigType" SG_ 2561146622 AuxI_O47 4;
BA_ "SPN" SG_ 2561146622 AuxI_O48 3871;
BA_ "SigType" SG_ 2561146622 AuxI_O48 4;
BA_ "SPN" SG_ 2561146622 AuxI_O41 3864;
BA_ "SigType" SG_ 2561146622 AuxI_O41 4;
BA_ "SPN" SG_ 2561146622 AuxI_O42 3865;
BA_ "SigType" SG_ 2561146622 AuxI_O42 4;
BA_ "SPN" SG_ 2561146622 AuxI_O43 3866;
BA_ "SigType" SG_ 2561146622 AuxI_O43 4;
BA_ "SPN" SG_ 2561146622 AuxI_O44 3867;
BA_ "SigType" SG_ 2561146622 AuxI_O44 4;
BA_ "SPN" SG_ 2561146622 AuxI_O37 3860;
BA_ "SigType" SG_ 2561146622 AuxI_O37 4;
BA_ "SPN" SG_ 2561146622 AuxI_O38 3861;
BA_ "SigType" SG_ 2561146622 AuxI_O38 4;
BA_ "SPN" SG_ 2561146622 AuxI_O39 3862;
BA_ "SigType" SG_ 2561146622 AuxI_O39 4;
BA_ "SPN" SG_ 2561146622 AuxI_O40 3863;
BA_ "SigType" SG_ 2561146622 AuxI_O40 4;
BA_ "SPN" SG_ 2561146622 AuxI_O33 3856;
BA_ "SigType" SG_ 2561146622 AuxI_O33 4;
BA_ "SPN" SG_ 2561146622 AuxI_O34 3857;
BA_ "SigType" SG_ 2561146622 AuxI_O34 4;
BA_ "SPN" SG_ 2561146622 AuxI_O35 3858;
BA_ "SigType" SG_ 2561146622 AuxI_O35 4;
BA_ "SPN" SG_ 2561146622 AuxI_O36 3859;
BA_ "SigType" SG_ 2561146622 AuxI_O36 4;
BA_ "SPN" SG_ 2561146622 AuxI_O29 3852;
BA_ "SigType" SG_ 2561146622 AuxI_O29 4;
BA_ "SPN" SG_ 2561146622 AuxI_O30 3853;
BA_ "SigType" SG_ 2561146622 AuxI_O30 4;
BA_ "SPN" SG_ 2561146622 AuxI_O31 3854;
BA_ "SigType" SG_ 2561146622 AuxI_O31 4;
BA_ "SPN" SG_ 2561146622 AuxI_O32 3855;
BA_ "SigType" SG_ 2561146622 AuxI_O32 4;
BA_ "SPN" SG_ 2561146622 AuxI_O25 3848;
BA_ "SigType" SG_ 2561146622 AuxI_O25 4;
BA_ "SPN" SG_ 2561146622 AuxI_O26 3849;
BA_ "SigType" SG_ 2561146622 AuxI_O26 4;
BA_ "SPN" SG_ 2561146622 AuxI_O27 3850;
BA_ "SigType" SG_ 2561146622 AuxI_O27 4;
BA_ "SPN" SG_ 2561146622 AuxI_O28 3851;
BA_ "SigType" SG_ 2561146622 AuxI_O28 4;
BA_ "SPN" SG_ 2561146622 AuxI_O21 3844;
BA_ "SigType" SG_ 2561146622 AuxI_O21 4;
BA_ "SPN" SG_ 2561146622 AuxI_O22 3845;
BA_ "SigType" SG_ 2561146622 AuxI_O22 4;
BA_ "SPN" SG_ 2561146622 AuxI_O23 3846;
BA_ "SigType" SG_ 2561146622 AuxI_O23 4;
BA_ "SPN" SG_ 2561146622 AuxI_O24 3847;
BA_ "SigType" SG_ 2561146622 AuxI_O24 4;
BA_ "SPN" SG_ 2561146622 AuxI_O17 3840;
BA_ "SigType" SG_ 2561146622 AuxI_O17 4;
BA_ "SPN" SG_ 2561146622 AuxI_O18 3841;
BA_ "SigType" SG_ 2561146622 AuxI_O18 4;
BA_ "SPN" SG_ 2561146622 AuxI_O19 3842;
BA_ "SigType" SG_ 2561146622 AuxI_O19 4;
BA_ "SPN" SG_ 2561146622 AuxI_O20 3843;
BA_ "SigType" SG_ 2561146622 AuxI_O20 4;
BA_ "SPN" SG_ 2561081086 AuxI_O77 3900;
BA_ "SigType" SG_ 2561081086 AuxI_O77 4;
BA_ "SPN" SG_ 2561081086 AuxI_O78 3901;
BA_ "SigType" SG_ 2561081086 AuxI_O78 4;
BA_ "SPN" SG_ 2561081086 AuxI_O79 3902;
BA_ "SigType" SG_ 2561081086 AuxI_O79 4;
BA_ "SPN" SG_ 2561081086 AuxI_O80 3903;
BA_ "SigType" SG_ 2561081086 AuxI_O80 4;
BA_ "SPN" SG_ 2561081086 AuxI_O73 3896;
BA_ "SigType" SG_ 2561081086 AuxI_O73 4;
BA_ "SPN" SG_ 2561081086 AuxI_O74 3897;
BA_ "SigType" SG_ 2561081086 AuxI_O74 4;
BA_ "SPN" SG_ 2561081086 AuxI_O75 3898;
BA_ "SigType" SG_ 2561081086 AuxI_O75 4;
BA_ "SPN" SG_ 2561081086 AuxI_O76 3899;
BA_ "SigType" SG_ 2561081086 AuxI_O76 4;
BA_ "SPN" SG_ 2561081086 AuxI_O69 3892;
BA_ "SigType" SG_ 2561081086 AuxI_O69 4;
BA_ "SPN" SG_ 2561081086 AuxI_O70 3893;
BA_ "SigType" SG_ 2561081086 AuxI_O70 4;
BA_ "SPN" SG_ 2561081086 AuxI_O71 3894;
BA_ "SigType" SG_ 2561081086 AuxI_O71 4;
BA_ "SPN" SG_ 2561081086 AuxI_O72 3895;
BA_ "SigType" SG_ 2561081086 AuxI_O72 4;
BA_ "SPN" SG_ 2561081086 AuxI_O65 3888;
BA_ "SigType" SG_ 2561081086 AuxI_O65 4;
BA_ "SPN" SG_ 2561081086 AuxI_O66 3889;
BA_ "SigType" SG_ 2561081086 AuxI_O66 4;
BA_ "SPN" SG_ 2561081086 AuxI_O67 3890;
BA_ "SigType" SG_ 2561081086 AuxI_O67 4;
BA_ "SPN" SG_ 2561081086 AuxI_O68 3891;
BA_ "SigType" SG_ 2561081086 AuxI_O68 4;
BA_ "SPN" SG_ 2561081086 AuxI_O61 3884;
BA_ "SigType" SG_ 2561081086 AuxI_O61 4;
BA_ "SPN" SG_ 2561081086 AuxI_O62 3885;
BA_ "SigType" SG_ 2561081086 AuxI_O62 4;
BA_ "SPN" SG_ 2561081086 AuxI_O63 3886;
BA_ "SigType" SG_ 2561081086 AuxI_O63 4;
BA_ "SPN" SG_ 2561081086 AuxI_O64 3887;
BA_ "SigType" SG_ 2561081086 AuxI_O64 4;
BA_ "SPN" SG_ 2561081086 AuxI_O57 3880;
BA_ "SigType" SG_ 2561081086 AuxI_O57 4;
BA_ "SPN" SG_ 2561081086 AuxI_O58 3881;
BA_ "SigType" SG_ 2561081086 AuxI_O58 4;
BA_ "SPN" SG_ 2561081086 AuxI_O59 3882;
BA_ "SigType" SG_ 2561081086 AuxI_O59 4;
BA_ "SPN" SG_ 2561081086 AuxI_O60 3883;
BA_ "SigType" SG_ 2561081086 AuxI_O60 4;
BA_ "SPN" SG_ 2561081086 AuxI_O53 3876;
BA_ "SigType" SG_ 2561081086 AuxI_O53 4;
BA_ "SPN" SG_ 2561081086 AuxI_O54 3877;
BA_ "SigType" SG_ 2561081086 AuxI_O54 4;
BA_ "SPN" SG_ 2561081086 AuxI_O55 3878;
BA_ "SigType" SG_ 2561081086 AuxI_O55 4;
BA_ "SPN" SG_ 2561081086 AuxI_O56 3879;
BA_ "SigType" SG_ 2561081086 AuxI_O56 4;
BA_ "SPN" SG_ 2561081086 AuxI_O49 3872;
BA_ "SigType" SG_ 2561081086 AuxI_O49 4;
BA_ "SPN" SG_ 2561081086 AuxI_O50 3873;
BA_ "SigType" SG_ 2561081086 AuxI_O50 4;
BA_ "SPN" SG_ 2561081086 AuxI_O51 3874;
BA_ "SigType" SG_ 2561081086 AuxI_O51 4;
BA_ "SPN" SG_ 2561081086 AuxI_O52 3875;
BA_ "SigType" SG_ 2561081086 AuxI_O52 4;
BA_ "SPN" SG_ 2561015550 AuxI_O92 3915;
BA_ "SigType" SG_ 2561015550 AuxI_O92 4;
BA_ "SPN" SG_ 2561015550 AuxI_O85 3908;
BA_ "SigType" SG_ 2561015550 AuxI_O85 4;
BA_ "SPN" SG_ 2561015550 AuxI_O86 3909;
BA_ "SigType" SG_ 2561015550 AuxI_O86 4;
BA_ "SPN" SG_ 2561015550 AuxI_O87 3910;
BA_ "SigType" SG_ 2561015550 AuxI_O87 4;
BA_ "SPN" SG_ 2561015550 AuxI_O88 3911;
BA_ "SigType" SG_ 2561015550 AuxI_O88 4;
BA_ "SPN" SG_ 2561015550 AuxI_O81 3904;
BA_ "SigType" SG_ 2561015550 AuxI_O81 4;
BA_ "SPN" SG_ 2561015550 AuxI_O82 3905;
BA_ "SigType" SG_ 2561015550 AuxI_O82 4;
BA_ "SPN" SG_ 2561015550 AuxI_O83 3906;
BA_ "SigType" SG_ 2561015550 AuxI_O83 4;
BA_ "SPN" SG_ 2561015550 AuxI_O84 3907;
BA_ "SigType" SG_ 2561015550 AuxI_O84 4;
BA_ "SPN" SG_ 2561015550 AuxI_O109 3932;
BA_ "SigType" SG_ 2561015550 AuxI_O109 4;
BA_ "SPN" SG_ 2561015550 AuxI_O110 3933;
BA_ "SigType" SG_ 2561015550 AuxI_O110 4;
BA_ "SPN" SG_ 2561015550 AuxI_O111 3934;
BA_ "SigType" SG_ 2561015550 AuxI_O111 4;
BA_ "SPN" SG_ 2561015550 AuxI_O112 3935;
BA_ "SigType" SG_ 2561015550 AuxI_O112 4;
BA_ "SPN" SG_ 2561015550 AuxI_O105 3928;
BA_ "SigType" SG_ 2561015550 AuxI_O105 4;
BA_ "SPN" SG_ 2561015550 AuxI_O106 3929;
BA_ "SigType" SG_ 2561015550 AuxI_O106 4;
BA_ "SPN" SG_ 2561015550 AuxI_O107 3930;
BA_ "SigType" SG_ 2561015550 AuxI_O107 4;
BA_ "SPN" SG_ 2561015550 AuxI_O108 3931;
BA_ "SigType" SG_ 2561015550 AuxI_O108 4;
BA_ "SPN" SG_ 2561015550 AuxI_O101 3924;
BA_ "SigType" SG_ 2561015550 AuxI_O101 4;
BA_ "SPN" SG_ 2561015550 AuxI_O102 3925;
BA_ "SigType" SG_ 2561015550 AuxI_O102 4;
BA_ "SPN" SG_ 2561015550 AuxI_O103 3926;
BA_ "SigType" SG_ 2561015550 AuxI_O103 4;
BA_ "SPN" SG_ 2561015550 AuxI_O104 3927;
BA_ "SigType" SG_ 2561015550 AuxI_O104 4;
BA_ "SPN" SG_ 2561015550 AuxI_O97 3920;
BA_ "SigType" SG_ 2561015550 AuxI_O97 4;
BA_ "SPN" SG_ 2561015550 AuxI_O98 3921;
BA_ "SigType" SG_ 2561015550 AuxI_O98 4;
BA_ "SPN" SG_ 2561015550 AuxI_O99 3922;
BA_ "SigType" SG_ 2561015550 AuxI_O99 4;
BA_ "SPN" SG_ 2561015550 AuxI_O100 3923;
BA_ "SigType" SG_ 2561015550 AuxI_O100 4;
BA_ "SPN" SG_ 2561015550 AuxI_O93 3916;
BA_ "SigType" SG_ 2561015550 AuxI_O93 4;
BA_ "SPN" SG_ 2561015550 AuxI_O94 3917;
BA_ "SigType" SG_ 2561015550 AuxI_O94 4;
BA_ "SPN" SG_ 2561015550 AuxI_O95 3918;
BA_ "SigType" SG_ 2561015550 AuxI_O95 4;
BA_ "SPN" SG_ 2561015550 AuxI_O96 3919;
BA_ "SigType" SG_ 2561015550 AuxI_O96 4;
BA_ "SPN" SG_ 2561015550 AuxI_O89 3912;
BA_ "SigType" SG_ 2561015550 AuxI_O89 4;
BA_ "SPN" SG_ 2561015550 AuxI_O90 3913;
BA_ "SigType" SG_ 2561015550 AuxI_O90 4;
BA_ "SPN" SG_ 2561015550 AuxI_O91 3914;
BA_ "SigType" SG_ 2561015550 AuxI_O91 4;
BA_ "SPN" SG_ 2566746622 TrailerBrakeStrokeAxle5Right 3804;
BA_ "SPN" SG_ 2566746622 TrailerBrakeStrokeAxle5Left 3803;
BA_ "SPN" SG_ 2566746622 TrailerBrakeStrokeAxle4Right 3802;
BA_ "SPN" SG_ 2566746622 TrailerBrakeStrokeAxle4Left 3801;
BA_ "SPN" SG_ 2566746622 TrailerBrakeStrokeAxle3Right 3800;
BA_ "SPN" SG_ 2566746622 TrailerBrakeStrokeAxle3Left 3799;
BA_ "SPN" SG_ 2566746622 TrailerBrakeStrokeAxle2Right 3798;
BA_ "SPN" SG_ 2566746622 TrailerBrakeStrokeAxle2Left 3797;
BA_ "SPN" SG_ 2566746622 TrailerBrakeStrokeAxle1Right 3796;
BA_ "SPN" SG_ 2566746622 TrailerBrakeStrokeAxle1Left 3795;
BA_ "SPN" SG_ 2566746622 TractorBrakeStrokeAxle5Right 3794;
BA_ "SPN" SG_ 2566746622 TractorBrakeStrokeAxle5Left 3793;
BA_ "SPN" SG_ 2566746622 TractorBrakeStrokeAxle4Right 3792;
BA_ "SPN" SG_ 2566746622 TractorBrakeStrokeAxle4Left 3791;
BA_ "SPN" SG_ 2566746622 TractorBrakeStrokeAxle3Right 3790;
BA_ "SPN" SG_ 2566746622 TractorBrakeStrokeAxle3Left 3789;
BA_ "SPN" SG_ 2566746622 TractorBrakeStrokeAxle2Right 3788;
BA_ "SPN" SG_ 2566746622 TractorBrakeStrokeAxle2Left 3787;
BA_ "SPN" SG_ 2566746622 TractorBrakeStrokeAxle1Right 3786;
BA_ "SPN" SG_ 2566746622 TractorBrakeStrokeAxle1Left 3785;
BA_ "SPN" SG_ 2566845950 EngAirIntakeTemp 172;
BA_ "SigType" SG_ 2566845950 EngAirIntakeTemp 1;
BA_ "SPN" SG_ 2566845950 BarometricPress 108;
BA_ "SigType" SG_ 2566845950 BarometricPress 1;
BA_ "SPN" SG_ 2566840062 EngAirStartPress 82;
BA_ "SigType" SG_ 2566840062 EngAirStartPress 1;
BA_ "GenSigStartValue" SG_ 2566827568 AuxEquipmentSupplyPress 31.875;
BA_ "SPN" SG_ 2566827568 ServiceBrakeCircuit2AirPress 1088;
BA_ "SigType" SG_ 2566827568 ServiceBrakeCircuit2AirPress 1;
BA_ "SPN" SG_ 2566827568 ServiceBrakeCircuit1AirPress 1087;
BA_ "SigType" SG_ 2566827568 ServiceBrakeCircuit1AirPress 1;
BA_ "SPN" SG_ 2566827568 AirCompressorStatus 1351;
BA_ "SigType" SG_ 2566827568 AirCompressorStatus 4;
BA_ "GenSigStartValue" SG_ 2566827568 AirCompressorStatus 255;
BA_ "SPN" SG_ 2566827568 ParkingAnd_OrTrailerAirPress 1086;
BA_ "SigType" SG_ 2566827568 ParkingAnd_OrTrailerAirPress 1;
BA_ "GenSigStartValue" SG_ 2566827568 ParkingAnd_OrTrailerAirPress 31.875;
BA_ "SPN" SG_ 2566827568 PneumaticSupplyPress 46;
BA_ "SigType" SG_ 2566827568 PneumaticSupplyPress 1;
BA_ "GenSigStartValue" SG_ 2566827568 PneumaticSupplyPress 31.875;
BA_ "SPN" SG_ 2566846974 SteerAxleLubePress 2614;
BA_ "SigType" SG_ 2566846974 SteerAxleLubePress 1;
BA_ "SPN" SG_ 2566846974 SteerAxleTemp 75;
BA_ "SigType" SG_ 2566846974 SteerAxleTemp 1;
BA_ "SPN" SG_ 2566846974 DriveAxleLubePress 2613;
BA_ "SigType" SG_ 2566846974 DriveAxleLubePress 1;
BA_ "SPN" SG_ 2566846974 DriveAxleTemp 578;
BA_ "SigType" SG_ 2566846974 DriveAxleTemp 1;
BA_ "SPN" SG_ 2566846974 DriveAxleLiftAirPress 579;
BA_ "SigType" SG_ 2566846974 DriveAxleLiftAirPress 1;
BA_ "SPN" SG_ 2566846974 DriveAxleLocation 930;
BA_ "SigType" SG_ 2566846974 DriveAxleLocation 1;
BA_ "SPN" SG_ 2633935614 EngTurboWastegateValvePos 1693;
BA_ "SigType" SG_ 2633935614 EngTurboWastegateValvePos 1;
BA_ "SPN" SG_ 2633935614 EngGsMssFlwSnsrFelingCorrection 1694;
BA_ "SigType" SG_ 2633935614 EngGsMssFlwSnsrFelingCorrection 1;
BA_ "SPN" SG_ 2633935614 EngDsiredAbsIntakeManifoldPress 1692;
BA_ "SigType" SG_ 2633935614 EngDsiredAbsIntakeManifoldPress 1;
BA_ "SPN" SG_ 2633935614 EngGasFuelCorrectionFactor 1116;
BA_ "SigType" SG_ 2633935614 EngGasFuelCorrectionFactor 1;
BA_ "SigType" SG_ 2566803745 ACCUsageDemand_ACC2 4;
BA_ "SPN" SG_ 2566803745 ACCUsageDemand_ACC2 5023;
BA_ "SPN" SG_ 2432593918 ForwardCollisionWarning 5022;
BA_ "SigType" SG_ 2432593918 ForwardCollisionWarning 4;
BA_ "SPN" SG_ 2432593918 ACCDistanceAlertSignal 1796;
BA_ "SigType" SG_ 2432593918 ACCDistanceAlertSignal 4;
BA_ "SPN" SG_ 2432593918 ACCSystemShutoffWarning 1797;
BA_ "SigType" SG_ 2432593918 ACCSystemShutoffWarning 4;
BA_ "SPN" SG_ 2432593918 ACCTargetDetected 1798;
BA_ "SigType" SG_ 2432593918 ACCTargetDetected 4;
BA_ "SPN" SG_ 2432593918 RoadCurvature 1591;
BA_ "SigType" SG_ 2432593918 RoadCurvature 1;
BA_ "SPN" SG_ 2432593918 AdptveCruiseCtrlSetDistanceMode 1589;
BA_ "SPN" SG_ 2432593918 AdaptiveCruiseCtrlMode 1590;
BA_ "SPN" SG_ 2432593918 AdaptiveCruiseCtrlSetSpeed 1588;
BA_ "SigType" SG_ 2432593918 AdaptiveCruiseCtrlSetSpeed 1;
BA_ "SPN" SG_ 2432593918 DistanceToForwardVehicle 1587;
BA_ "SigType" SG_ 2432593918 DistanceToForwardVehicle 1;
BA_ "SPN" SG_ 2432593918 SpeedOfForwardVehicle 1586;
BA_ "SigType" SG_ 2432593918 SpeedOfForwardVehicle 1;
BA_ "SPN" SG_ 2633935102 ArticulationAngle 1120;
BA_ "SigType" SG_ 2633935102 ArticulationAngle 1;
BA_ "SPN" SG_ 2633927934 RelativeHumidity 354;
BA_ "SigType" SG_ 2633927934 RelativeHumidity 1;
BA_ "SPN" SG_ 2633927934 AuxLevel 3087;
BA_ "SigType" SG_ 2633927934 AuxLevel 1;
BA_ "SPN" SG_ 2633927934 AuxPress2 1388;
BA_ "SigType" SG_ 2633927934 AuxPress2 1;
BA_ "SPN" SG_ 2633927934 AuxPress1 1387;
BA_ "SigType" SG_ 2633927934 AuxPress1 1;
BA_ "SPN" SG_ 2633927934 AuxTemp2 442;
BA_ "SigType" SG_ 2633927934 AuxTemp2 1;
BA_ "SPN" SG_ 2633927934 AuxTemp1 441;
BA_ "SigType" SG_ 2633927934 AuxTemp1 1;
BA_ "SPN" SG_ 2566847998 EngBlowerBypassValvePos 72;
BA_ "SigType" SG_ 2566847998 EngBlowerBypassValvePos 1;
BA_ "SPN" SG_ 2566847998 EngGasSupplyPress 159;
BA_ "SigType" SG_ 2566847998 EngGasSupplyPress 1;
BA_ "SPN" SG_ 2565406462 ControlByte 2541;
BA_ "SPN" SG_ 2565406462 GroupFunctionValue 2542;
BA_ "SigType" SG_ 2565406462 GroupFunctionValue 1;
BA_ "SPN" SG_ 2566803198 Status2OfDoors 3411;
BA_ "SigType" SG_ 2566803198 Status2OfDoors 4;
BA_ "SPN" SG_ 2566803198 Ramp_WheelChairLiftPos 1820;
BA_ "SigType" SG_ 2566803198 Ramp_WheelChairLiftPos 4;
BA_ "SPN" SG_ 2566803198 PosOfDoors 1821;
BA_ "SigType" SG_ 2566803198 PosOfDoors 4;
BA_ "SPN" SG_ 2565870334 FifthWheelRollWarningIndicator 3317;
BA_ "SigType" SG_ 2565870334 FifthWheelRollWarningIndicator 4;
BA_ "SPN" SG_ 2565870334 FifthWheelRollMoment 3310;
BA_ "SigType" SG_ 2565870334 FifthWheelRollMoment 1;
BA_ "SPN" SG_ 2565870334 FifthWheelDrawbarForce 3309;
BA_ "SigType" SG_ 2565870334 FifthWheelDrawbarForce 1;
BA_ "SPN" SG_ 2565870334 FifthWheelVerticalForce 3308;
BA_ "SigType" SG_ 2565870334 FifthWheelVerticalForce 1;
BA_ "SPN" SG_ 2566762238 FifthWheelSliderLockIndicator 3316;
BA_ "SigType" SG_ 2566762238 FifthWheelSliderLockIndicator 4;
BA_ "SPN" SG_ 2566762238 FifthWheelSliderPos 3311;
BA_ "SigType" SG_ 2566762238 FifthWheelSliderPos 1;
BA_ "SPN" SG_ 2566762238 FfthWhlLckCoupleStatusIndicator 3313;
BA_ "SigType" SG_ 2566762238 FfthWhlLckCoupleStatusIndicator 4;
BA_ "SPN" SG_ 2566762238 FfthWhlLckRadyToCoupleIndicator 3312;
BA_ "SigType" SG_ 2566762238 FfthWhlLckRadyToCoupleIndicator 4;
BA_ "SPN" SG_ 2566762238 FifthWheelErrorStatus 3307;
BA_ "SigType" SG_ 2566762238 FifthWheelErrorStatus 4;
BA_ "SPN" SG_ 2364543998 RollAndPitchMeasurementLatency 3327;
BA_ "SigType" SG_ 2364543998 RollAndPitchMeasurementLatency 1;
BA_ "SPN" SG_ 2364543998 PitchAndRollCompensated 3326;
BA_ "SigType" SG_ 2364543998 PitchAndRollCompensated 4;
BA_ "SPN" SG_ 2364543998 PitchRateFigureOfMerit 3325;
BA_ "SigType" SG_ 2364543998 PitchRateFigureOfMerit 4;
BA_ "SPN" SG_ 2364543998 RollAngleFigureOfMerit 3324;
BA_ "SigType" SG_ 2364543998 RollAngleFigureOfMerit 4;
BA_ "SPN" SG_ 2364543998 PitchAngleFigureOfMerit 3323;
BA_ "SigType" SG_ 2364543998 PitchAngleFigureOfMerit 4;
BA_ "SPN" SG_ 2364543998 PitchRate 3322;
BA_ "SigType" SG_ 2364543998 PitchRate 1;
BA_ "SPN" SG_ 2364543998 RollAngle 3319;
BA_ "SigType" SG_ 2364543998 RollAngle 1;
BA_ "SPN" SG_ 2364543998 PitchAngle 3318;
BA_ "SigType" SG_ 2364543998 PitchAngle 1;
BA_ "SPN" SG_ 2566846718 TransOilLevelMeasurementStatus 3026;
BA_ "SigType" SG_ 2566846718 TransOilLevelMeasurementStatus 4;
BA_ "SPN" SG_ 2566846718 TransOilLevelCountdownTimer 3028;
BA_ "SigType" SG_ 2566846718 TransOilLevelCountdownTimer 4;
BA_ "SPN" SG_ 2566846718 TransOilLevelHigh_Low 3027;
BA_ "SigType" SG_ 2566846718 TransOilLevelHigh_Low 1;
BA_ "SPN" SG_ 2566846718 TransOilTemp 177;
BA_ "SigType" SG_ 2566846718 TransOilTemp 1;
BA_ "SPN" SG_ 2566846718 TransOilPress 127;
BA_ "SigType" SG_ 2566846718 TransOilPress 1;
BA_ "SPN" SG_ 2566846718 TransFilterDiffPress 126;
BA_ "SigType" SG_ 2566846718 TransFilterDiffPress 1;
BA_ "SPN" SG_ 2566846718 TransOilLevel 124;
BA_ "SigType" SG_ 2566846718 TransOilLevel 1;
BA_ "SPN" SG_ 2566846718 ClutchPress 123;
BA_ "SigType" SG_ 2566846718 ClutchPress 1;
BA_ "SPN" SG_ 2566846462 ChargingSystemPotential 167;
BA_ "SigType" SG_ 2566846462 ChargingSystemPotential 1;
BA_ "SPN" SG_ 2566846462 AltCurrent 115;
BA_ "SigType" SG_ 2566846462 AltCurrent 1;
BA_ "SPN" SG_ 2566846462 NetBatteryCurrent 114;
BA_ "SigType" SG_ 2566846462 NetBatteryCurrent 1;
BA_ "SPN" SG_ 2566846462 KeyswitchBatteryPotential 158;
BA_ "SigType" SG_ 2566846462 KeyswitchBatteryPotential 1;
BA_ "SPN" SG_ 2566846462 BatteryPotential_PowerInput1 168;
BA_ "SigType" SG_ 2566846462 BatteryPotential_PowerInput1 1;
BA_ "SPN" SG_ 2566760702 WrlessCommunicationNetworkType2 3446;
BA_ "SigType" SG_ 2566760702 WrlessCommunicationNetworkType2 1;
BA_ "SPN" SG_ 2566760702 NetworkSignalStrength2 3445;
BA_ "SigType" SG_ 2566760702 NetworkSignalStrength2 1;
BA_ "SPN" SG_ 2566760702 NetworkAntennaStatus2 3444;
BA_ "SigType" SG_ 2566760702 NetworkAntennaStatus2 1;
BA_ "SPN" SG_ 2566760702 NetworkServiceStatus2 3443;
BA_ "SigType" SG_ 2566760702 NetworkServiceStatus2 1;
BA_ "SPN" SG_ 2566760702 NetworkTransceiverStatus2 3442;
BA_ "SigType" SG_ 2566760702 NetworkTransceiverStatus2 1;
BA_ "SPN" SG_ 2566760958 WrlessCommunicationNetworkType1 3372;
BA_ "SigType" SG_ 2566760958 WrlessCommunicationNetworkType1 1;
BA_ "SPN" SG_ 2566760958 NetworkSignalStrength1 3371;
BA_ "SigType" SG_ 2566760958 NetworkSignalStrength1 1;
BA_ "SPN" SG_ 2566760958 NetworkAntennaStatus1 3370;
BA_ "SigType" SG_ 2566760958 NetworkAntennaStatus1 1;
BA_ "SPN" SG_ 2566760958 NetworkServiceStatus1 3369;
BA_ "SigType" SG_ 2566760958 NetworkServiceStatus1 1;
BA_ "SPN" SG_ 2566760958 NetworkTransceiverStatus1 3368;
BA_ "SigType" SG_ 2566760958 NetworkTransceiverStatus1 1;
BA_ "SPN" SG_ 2633869310 VoltageRegulatorEnabled 3379;
BA_ "SigType" SG_ 2633869310 VoltageRegulatorEnabled 4;
BA_ "SPN" SG_ 2633869310 VoltageRegulatorSoftStartState 3378;
BA_ "SigType" SG_ 2633869310 VoltageRegulatorSoftStartState 4;
BA_ "SPN" SG_ 2633869310 VltgRgltrUndrfrqncyCmpnstnEnbld 3377;
BA_ "SigType" SG_ 2633869310 VltgRgltrUndrfrqncyCmpnstnEnbld 4;
BA_ "SPN" SG_ 2633869310 VltgRgltrVAr_PwrFctrOprtingMode 3376;
BA_ "SPN" SG_ 2633869310 VltgRglatorLoadCompensationMode 3375;
BA_ "SPN" SG_ 2365433598 GnrtrOtputVoltageBiasPercentage 3382;
BA_ "SigType" SG_ 2365433598 GnrtrOtputVoltageBiasPercentage 1;
BA_ "SPN" SG_ 2365433598 GeneratorExcitationFieldCurrent 3381;
BA_ "SigType" SG_ 2365433598 GeneratorExcitationFieldCurrent 1;
BA_ "SPN" SG_ 2365433598 GeneratorExcitationFieldVoltage 3380;
BA_ "SigType" SG_ 2365433598 GeneratorExcitationFieldVoltage 1;
VAL_ 2565928476 Stub_Update 1 "True" 0 "False" ;
VAL_ 2565928476 Stub_TurnAngle 255 "N/A" 254 "Unknown" 253 "1.417° left from path dir" 252 "2.835° left from path dir" 251 "4.252° left from path dir" 250 "5.669° left from path dir" 249 "7.087° left from path dir" 248 "8.504° left from path dir" 247 "9.921° left from path dir" 246 "11.339° left from path dir" 245 "12.756° left from path dir" 244 "14.173° left from path dir" 243 "15.591° left from path dir" 242 "17.008° left from path dir" 241 "18.425° left from path dir" 240 "19.843° left from path dir" 239 "21.26° left from path dir" 238 "22.677° left from path dir" 237 "24.094° left from path dir" 236 "25.512° left from path dir" 235 "26.929° left from path dir" 234 "28.346° left from path dir" 233 "29.764° left from path dir" 232 "31.181° left from path dir" 231 "32.598° left from path dir" 230 "34.016° left from path dir" 229 "35.433° left from path dir" 228 "36.85° left from path dir" 227 "38.268° left from path dir" 226 "39.685° left from path dir" 225 "41.102° left from path dir" 224 "42.52° left from path dir" 223 "43.937° left from path dir" 222 "45.354° left from path dir" 221 "46.772° left from path dir" 220 "48.189° left from path dir" 219 "49.606° left from path dir" 218 "51.024° left from path dir" 217 "52.441° left from path dir" 216 "53.858° left from path dir" 215 "55.276° left from path dir" 214 "56.693° left from path dir" 213 "58.11° left from path dir" 212 "59.528° left from path dir" 211 "60.945° left from path dir" 210 "62.362° left from path dir" 209 "63.78° left from path dir" 208 "65.197° left from path dir" 207 "66.614° left from path dir" 206 "68.031° left from path dir" 205 "69.449° left from path dir" 204 "70.866° left from path dir" 203 "72.283° left from path dir" 202 "73.701° left from path dir" 201 "75.118° left from path dir" 200 "76.535° left from path dir" 199 "77.953° left from path dir" 198 "79.37° left from path dir" 197 "80.787° left from path dir" 196 "82.205° left from path dir" 195 "83.622° left from path dir" 194 "85.039° left from path dir" 193 "86.457° left from path dir" 192 "87.874° left from path dir" 191 "89.291° left from path dir" 190 "90.709° left from path dir" 189 "92.126° left from path dir" 188 "93.543° left from path dir" 187 "94.961° left from path dir" 186 "96.378° left from path dir" 185 "97.795° left from path dir" 184 "99.213° left from path dir" 183 "100.63° left from path dir" 182 "102.047° left from path dir" 181 "103.465° left from path dir" 180 "104.882° left from path dir" 179 "106.299° left from path dir" 178 "107.717° left from path dir" 177 "109.134° left from path dir" 176 "110.551° left from path dir" 175 "111.969° left from path dir" 174 "113.386° left from path dir" 173 "114.803° left from path dir" 172 "116.22° left from path dir" 171 "117.638° left from path dir" 170 "119.055° left from path dir" 169 "120.472° left from path dir" 168 "121.89° left from path dir" 167 "123.307° left from path dir" 166 "124.724° left from path dir" 165 "126.142° left from path dir" 164 "127.559° left from path dir" 163 "128.976° left from path dir" 162 "130.394° left from path dir" 161 "131.811° left from path dir" 160 "133.228° left from path dir" 159 "134.646° left from path dir" 158 "136.063° left from path dir" 157 "137.48° left from path dir" 156 "138.898° left from path dir" 155 "140.315° left from path dir" 154 "141.732° left from path dir" 153 "143.15° left from path dir" 152 "144.567° left from path dir" 151 "145.984° left from path dir" 150 "147.402° left from path dir" 149 "148.819° left from path dir" 148 "150.236° left from path dir" 147 "151.654° left from path dir" 146 "153.071° left from path dir" 145 "154.488° left from path dir" 144 "155.906° left from path dir" 143 "157.323° left from path dir" 142 "158.74° left from path dir" 141 "160.157° left from path dir" 140 "161.575° left from path dir" 139 "162.992° left from path dir" 138 "164.409° left from path dir" 137 "165.827° left from path dir" 136 "167.244° left from path dir" 135 "168.661° left from path dir" 134 "170.079° left from path dir" 133 "171.496° left from path dir" 132 "172.913° left from path dir" 131 "174.331° left from path dir" 130 "175.748° left from path dir" 129 "177.165° left from path dir" 128 "178.583° left from path dir" 127 "Opposite direction" 126 "178.583° right from path dir" 125 "177.165° right from path dir" 124 "175.748° right from path dir" 123 "174.331° right from path dir" 122 "172.913° right from path dir" 121 "171.496° right from path dir" 120 "170.079° right from path dir" 119 "168.661° right from path dir" 118 "167.244° right from path dir" 117 "165.827° right from path dir" 116 "164.409° right from path dir" 115 "162.992° right from path dir" 114 "161.575° right from path dir" 113 "160.157° right from path dir" 112 "158.74° right from path dir" 111 "157.323° right from path dir" 110 "155.906° right from path dir" 109 "154.488° right from path dir" 108 "153.071° right from path dir" 107 "151.654° right from path dir" 106 "150.236° right from path dir" 105 "148.819° right from path dir" 104 "147.402° right from path dir" 103 "145.984° right from path dir" 102 "144.567° right from path dir" 101 "143.15° right from path dir" 100 "141.732° right from path dir" 99 "140.315° right from path dir" 98 "138.898° right from path dir" 97 "137.48° right from path dir" 96 "136.063° right from path dir" 95 "134.646° right from path dir" 94 "133.228° right from path dir" 93 "131.811° right from path dir" 92 "130.394° right from path dir" 91 "128.976° right from path dir" 90 "127.559° right from path dir" 89 "126.142° right from path dir" 88 "124.724° right from path dir" 87 "123.307° right from path dir" 86 "121.89° right from path dir" 85 "120.472° right from path dir" 84 "119.055° right from path dir" 83 "117.638° right from path dir" 82 "116.22° right from path dir" 81 "114.803° right from path dir" 80 "113.386° right from path dir" 79 "111.969° right from path dir" 78 "110.551° right from path dir" 77 "109.134° right from path dir" 76 "107.717° right from path dir" 75 "106.299° right from path dir" 74 "104.882° right from path dir" 73 "103.465° right from path dir" 72 "102.047° right from path dir" 71 "100.63° right from path dir" 70 "99.213° right from path dir" 69 "97.795° right from path dir" 68 "96.378° right from path dir" 67 "94.961° right from path dir" 66 "93.543° right from path dir" 65 "92.126° right from path dir" 64 "90.709° right from path dir" 63 "89.291° right from path dir" 62 "87.874° right from path dir" 61 "86.457° right from path dir" 60 "85.039° right from path dir" 59 "83.622° right from path dir" 58 "82.205° right from path dir" 57 "80.787° right from path dir" 56 "79.37° right from path dir" 55 "77.953° right from path dir" 54 "76.535° right from path dir" 53 "75.118° right from path dir" 52 "73.701° right from path dir" 51 "72.283° right from path dir" 50 "70.866° right from path dir" 49 "69.449° right from path dir" 48 "68.031° right from path dir" 47 "66.614° right from path dir" 46 "65.197° right from path dir" 45 "63.78° right from path dir" 44 "62.362° right from path dir" 43 "60.945° right from path dir" 42 "59.528° right from path dir" 41 "58.11° right from path dir" 40 "56.693° right from path dir" 39 "55.276° right from path dir" 38 "53.858° right from path dir" 37 "52.441° right from path dir" 36 "51.024° right from path dir" 35 "49.606° right from path dir" 34 "48.189° right from path dir" 33 "46.772° right from path dir" 32 "45.354° right from path dir" 31 "43.937° right from path dir" 30 "42.52° right from path dir" 29 "41.102° right from path dir" 28 "39.685° right from path dir" 27 "38.268° right from path dir" 26 "36.85° right from path dir" 25 "35.433° right from path dir" 24 "34.016° right from path dir" 23 "32.598° right from path dir" 22 "31.181° right from path dir" 21 "29.764° right from path dir" 20 "28.346° right from path dir" 19 "26.929° right from path dir" 18 "25.512° right from path dir" 17 "24.094° right from path dir" 16 "22.677° right from path dir" 15 "21.26° right from path dir" 14 "19.843° right from path dir" 13 "18.425° right from path dir" 12 "17.008° right from path dir" 11 "15.591° right from path dir" 10 "14.173° right from path dir" 9 "12.756° right from path dir" 8 "11.339° right from path dir" 7 "9.921° right from path dir" 6 "8.504° right from path dir" 5 "7.087° right from path dir" 4 "5.669° right from path dir" 3 "4.252° right from path dir" 2 "2.835° right from path dir" 1 "1.417° right from path dir" 0 "In path direction" ;
VAL_ 2565928476 Stub_SubPathIx 7 "Reserved" 6 "HEADING CHANGE" 5 "Not further appended" 0 "Unknown" ;
VAL_ 2565928476 Stub_RightOfWay 3 "N/A" 2 "Unknown" 1 "Sub-path has right-of-way" 0 "Parent path has right-of-way" ;
VAL_ 2565928476 Stub_Retr 1 "True" 0 "False" ;
VAL_ 2565928476 Stub_RelProb 31 "Unknown or N/A" 0 "Driving not allowed on this segm" ;
VAL_ 2565928476 Stub_PathIx 7 "Reserved" 4 "Msg refer to cur.pos. segm" 0 "Unknown" ;
VAL_ 2565928476 Stub_PartOfCalcRoute 3 "N/A" 2 "Unknown" 1 "Part of Calculated Route" 0 "Not part of Calculated Route" ;
VAL_ 2565928476 Stub_Ofs 8191 "Invalid" ;
VAL_ 2565928476 Stub_NumOfLanesInOppDir 3 "N/A" 2 "2 or more lanes" 1 "1 lane only" 0 "One-direction road" ;
VAL_ 2565928476 Stub_NumOfLanesInDrivDir 7 "N/A" 6 "6 or more lanes" 5 "5 lanes" 4 "4 lanes" 3 "3 lanes" 2 "2 lanes" 1 "1 lane" 0 "One-direction road in wrong dir" ;
VAL_ 2565928476 Stub_FunctRoadClass 7 "N/A" 6 "Class 6" 5 "Class 5" 4 "Class 4" 3 "Class 3" 2 "Class 2" 1 "Class 1" 0 "Unknown" ;
VAL_ 2565928476 Stub_ComplexInters 3 "N/A" 2 "Unknown" 1 "Part of a complex intersection" 0 "Not part of complex intersection" ;
VAL_ 2565928476 Seg_Update 1 "True" 0 "False" ;
VAL_ 2565928476 Seg_Tunnel 3 "N/A" 2 "Unknown" 1 "Part of a tunnel" 0 "Not part of a tunnel" ;
VAL_ 2565928476 Seg_Retr 1 "True" 0 "False" ;
VAL_ 2565928476 Seg_RelProb 31 "Unknown or N/A" 0 "Driving not allowed on this segm" ;
VAL_ 2565928476 Seg_PathIx 7 "Reserved" 4 "Msg refer to cur.pos. segm" 0 "Unknown" ;
VAL_ 2565928476 Seg_PartOfCalcRoute 3 "N/A" 2 "Unknown" 1 "Part of Calculated Route" 0 "Not part of Calculated Route" ;
VAL_ 2565928476 Seg_Ofs 8191 "Invalid" ;
VAL_ 2565928476 Seg_NumOfLanesInOppDir 3 "N/A" 2 "2 or more lanes" 1 "1 lane only" 0 "One-direction road" ;
VAL_ 2565928476 Seg_NumOfLanesInDrivDir 7 "N/A" 6 "6 or more lanes" 5 "5 lanes" 4 "4 lanes" 3 "3 lanes" 2 "2 lanes" 1 "1 lane" 0 "One-direction road in wrong dir" ;
VAL_ 2565928476 Seg_FunctRoadClass 7 "N/A" 6 "Class 6" 5 "Class 5" 4 "Class 4" 3 "Class 3" 2 "Class 2" 1 "Class 1" 0 "Unknown" ;
VAL_ 2565928476 Seg_FormOfWay 14 "Pedestrian Zone" 13 "Service Entrance/Exit" 12 "CarPark Entrance/Exit" 11 "Service/Frontage Rd" 10 "SlipRd, not on Freeway/CntrldAcc" 9 "Freeway/CntrldAccess SlipRd" 8 "Parallel Road" 7 "Reserved" 6 "Reserved" 5 "Traffic Square/Special Traffic" 4 "Roundabout Circle" 3 "Single Carriageway (default)" 2 "Multiple Carriageway/Digitized" 1 "Freeway/CntrldAccess Rd" 0 "Unknown" ;
VAL_ 2565928476 Seg_EffSpeedLimType 7 "Unknown" 6 "Explicit, snow" 5 "Explicit, rain" 4 "Explicit, time of day" 3 "Explicit, by day" 2 "Explicit, by night" 1 "Explicit, on traffic sign" 0 "Implicit" ;
VAL_ 2565928476 Seg_EffSpeedLim 31 "N/A" 30 "Unlimited" 29 "160km/h(mph)" 28 "150km/h(mph)" 27 "140km/h(mph)" 26 "130km/h(mph)" 25 "120km/h(mph)" 24 "115km/h(mph)" 23 "110km/h(mph)" 22 "105km/h(mph)" 21 "100km/h(mph)" 20 "95km/h(mph)" 19 "90km/h(mph)" 18 "85km/h(mph)" 17 "80km/h(mph)" 16 "75km/h(mph)" 15 "70km/h(mph)" 14 "65km/h(mph)" 13 "60km/h(mph)" 12 "55km/h(mph)" 11 "50km/h(mph)" 10 "45km/h(mph)" 9 "40km/h(mph)" 8 "35km/h(mph)" 7 "30km/h(mph)" 6 "25km/h(mph)" 5 "20km/h(mph)" 4 "15km/h(mph)" 3 "10km/h(mph)" 2 "7km/h(mph)" 1 "= 5km/h(mph)" 0 "Unknown" ;
VAL_ 2565928476 Seg_DividedRoad 3 "N/A" 2 "Unknown" 1 "Part of a divided/dual road" 0 "Not part of a divided/dual road" ;
VAL_ 2565928476 Seg_ComplexInters 3 "Description for the value '0x3'" 2 "Unknown" 1 "Part of a complex intersection" 0 "Not part of complex intersection" ;
VAL_ 2565928476 Seg_BuiltUpArea 3 "Description for the value '0x3'" 2 "Unknown" 1 "Part of a built-up area" 0 "Not part of a built-up area" ;
VAL_ 2565928476 Seg_Bridge 3 "N/A" 2 "Unknown" 1 "Part of a bridge" 0 "Not part of a bridge" ;
VAL_ 2565928476 ProfShort_Val1_9_RsvdForStdTypes 1023 "Description for the value '0x0'" ;
VAL_ 2565928476 ProfShort_Val1_8_HeadChg 256 "N/A" 255 "N/A" 254 "Unknown" 253 "1.417° left from path dir" 252 "2.835° left from path dir" 251 "4.252° left from path dir" 250 "5.669° left from path dir" 249 "7.087° left from path dir" 248 "8.504° left from path dir" 247 "9.921° left from path dir" 246 "11.339° left from path dir" 245 "12.756° left from path dir" 244 "14.173° left from path dir" 243 "15.591° left from path dir" 242 "17.008° left from path dir" 241 "18.425° left from path dir" 240 "19.843° left from path dir" 239 "21.26° left from path dir" 238 "22.677° left from path dir" 237 "24.094° left from path dir" 236 "25.512° left from path dir" 235 "26.929° left from path dir" 234 "28.346° left from path dir" 233 "29.764° left from path dir" 232 "31.181° left from path dir" 231 "32.598° left from path dir" 230 "34.016° left from path dir" 229 "35.433° left from path dir" 228 "36.85° left from path dir" 227 "38.268° left from path dir" 226 "39.685° left from path dir" 225 "41.102° left from path dir" 224 "42.52° left from path dir" 223 "43.937° left from path dir" 222 "45.354° left from path dir" 221 "46.772° left from path dir" 220 "48.189° left from path dir" 219 "49.606° left from path dir" 218 "51.024° left from path dir" 217 "52.441° left from path dir" 216 "53.858° left from path dir" 215 "55.276° left from path dir" 214 "56.693° left from path dir" 213 "58.11° left from path dir" 212 "59.528° left from path dir" 211 "60.945° left from path dir" 210 "62.362° left from path dir" 209 "63.78° left from path dir" 208 "65.197° left from path dir" 207 "66.614° left from path dir" 206 "68.031° left from path dir" 205 "69.449° left from path dir" 204 "70.866° left from path dir" 203 "72.283° left from path dir" 202 "73.701° left from path dir" 201 "75.118° left from path dir" 200 "76.535° left from path dir" 199 "77.953° left from path dir" 198 "79.37° left from path dir" 197 "80.787° left from path dir" 196 "82.205° left from path dir" 195 "83.622° left from path dir" 194 "85.039° left from path dir" 193 "86.457° left from path dir" 192 "87.874° left from path dir" 191 "89.291° left from path dir" 190 "90.709° left from path dir" 189 "92.126° left from path dir" 188 "93.543° left from path dir" 187 "94.961° left from path dir" 186 "96.378° left from path dir" 185 "97.795° left from path dir" 184 "99.213° left from path dir" 183 "100.63° left from path dir" 182 "102.047° left from path dir" 181 "103.465° left from path dir" 180 "104.882° left from path dir" 179 "106.299° left from path dir" 178 "107.717° left from path dir" 177 "109.134° left from path dir" 176 "110.551° left from path dir" 175 "111.969° left from path dir" 174 "113.386° left from path dir" 173 "114.803° left from path dir" 172 "116.22° left from path dir" 171 "117.638° left from path dir" 170 "119.055° left from path dir" 169 "120.472° left from path dir" 168 "121.89° left from path dir" 167 "123.307° left from path dir" 166 "124.724° left from path dir" 165 "126.142° left from path dir" 164 "127.559° left from path dir" 163 "128.976° left from path dir" 162 "130.394° left from path dir" 161 "131.811° left from path dir" 160 "133.228° left from path dir" 159 "134.646° left from path dir" 158 "136.063° left from path dir" 157 "137.48° left from path dir" 156 "138.898° left from path dir" 155 "140.315° left from path dir" 154 "141.732° left from path dir" 153 "143.15° left from path dir" 152 "144.567° left from path dir" 151 "145.984° left from path dir" 150 "147.402° left from path dir" 149 "148.819° left from path dir" 148 "150.236° left from path dir" 147 "151.654° left from path dir" 146 "153.071° left from path dir" 145 "154.488° left from path dir" 144 "155.906° left from path dir" 143 "157.323° left from path dir" 142 "158.74° left from path dir" 141 "160.157° left from path dir" 140 "161.575° left from path dir" 139 "162.992° left from path dir" 138 "164.409° left from path dir" 137 "165.827° left from path dir" 136 "167.244° left from path dir" 135 "168.661° left from path dir" 134 "170.079° left from path dir" 133 "171.496° left from path dir" 132 "172.913° left from path dir" 131 "174.331° left from path dir" 130 "175.748° left from path dir" 129 "177.165° left from path dir" 128 "178.583° left from path dir" 127 "Opposite direction" 126 "178.583° right from path dir" 125 "177.165° right from path dir" 124 "175.748° right from path dir" 123 "174.331° right from path dir" 122 "172.913° right from path dir" 121 "171.496° right from path dir" 120 "170.079° right from path dir" 119 "168.661° right from path dir" 118 "167.244° right from path dir" 117 "165.827° right from path dir" 116 "164.409° right from path dir" 115 "162.992° right from path dir" 114 "161.575° right from path dir" 113 "160.157° right from path dir" 112 "158.74° right from path dir" 111 "157.323° right from path dir" 110 "155.906° right from path dir" 109 "154.488° right from path dir" 108 "153.071° right from path dir" 107 "151.654° right from path dir" 106 "150.236° right from path dir" 105 "148.819° right from path dir" 104 "147.402° right from path dir" 103 "145.984° right from path dir" 102 "144.567° right from path dir" 101 "143.15° right from path dir" 100 "141.732° right from path dir" 99 "140.315° right from path dir" 98 "138.898° right from path dir" 97 "137.48° right from path dir" 96 "136.063° right from path dir" 95 "134.646° right from path dir" 94 "133.228° right from path dir" 93 "131.811° right from path dir" 92 "130.394° right from path dir" 91 "128.976° right from path dir" 90 "127.559° right from path dir" 89 "126.142° right from path dir" 88 "124.724° right from path dir" 87 "123.307° right from path dir" 86 "121.89° right from path dir" 85 "120.472° right from path dir" 84 "119.055° right from path dir" 83 "117.638° right from path dir" 82 "116.22° right from path dir" 81 "114.803° right from path dir" 80 "113.386° right from path dir" 79 "111.969° right from path dir" 78 "110.551° right from path dir" 77 "109.134° right from path dir" 76 "107.717° right from path dir" 75 "106.299° right from path dir" 74 "104.882° right from path dir" 73 "103.465° right from path dir" 72 "102.047° right from path dir" 71 "100.63° right from path dir" 70 "99.213° right from path dir" 69 "97.795° right from path dir" 68 "96.378° right from path dir" 67 "94.961° right from path dir" 66 "93.543° right from path dir" 65 "92.126° right from path dir" 64 "90.709° right from path dir" 63 "89.291° right from path dir" 62 "87.874° right from path dir" 61 "86.457° right from path dir" 60 "85.039° right from path dir" 59 "83.622° right from path dir" 58 "82.205° right from path dir" 57 "80.787° right from path dir" 56 "79.37° right from path dir" 55 "77.953° right from path dir" 54 "76.535° right from path dir" 53 "75.118° right from path dir" 52 "73.701° right from path dir" 51 "72.283° right from path dir" 50 "70.866° right from path dir" 49 "69.449° right from path dir" 48 "68.031° right from path dir" 47 "66.614° right from path dir" 46 "65.197° right from path dir" 45 "63.78° right from path dir" 44 "62.362° right from path dir" 43 "60.945° right from path dir" 42 "59.528° right from path dir" 41 "58.11° right from path dir" 40 "56.693° right from path dir" 39 "55.276° right from path dir" 38 "53.858° right from path dir" 37 "52.441° right from path dir" 36 "51.024° right from path dir" 35 "49.606° right from path dir" 34 "48.189° right from path dir" 33 "46.772° right from path dir" 32 "45.354° right from path dir" 31 "43.937° right from path dir" 30 "42.52° right from path dir" 29 "41.102° right from path dir" 28 "39.685° right from path dir" 27 "38.268° right from path dir" 26 "36.85° right from path dir" 25 "35.433° right from path dir" 24 "34.016° right from path dir" 23 "32.598° right from path dir" 22 "31.181° right from path dir" 21 "29.764° right from path dir" 20 "28.346° right from path dir" 19 "26.929° right from path dir" 18 "25.512° right from path dir" 17 "24.094° right from path dir" 16 "22.677° right from path dir" 15 "21.26° right from path dir" 14 "19.843° right from path dir" 13 "18.425° right from path dir" 12 "17.008° right from path dir" 11 "15.591° right from path dir" 10 "14.173° right from path dir" 9 "12.756° right from path dir" 8 "11.339° right from path dir" 7 "9.921° right from path dir" 6 "8.504° right from path dir" 5 "7.087° right from path dir" 4 "5.669° right from path dir" 3 "4.252° right from path dir" 2 "2.835° right from path dir" 1 "1.417° right from path dir" 0 "In path direction" ;
VAL_ 2565928476 ProfShort_Val1_7_VarSpeedSignPos 1023 "Unknown" 0 "Unknown" ;
VAL_ 2565928476 ProfShort_Val1_6_RoadCond 1023 "Unknown" ;
VAL_ 2565928476 ProfShort_Val1_5_RoadAcc 1023 "Unknown or N/A" 0 "No access" ;
VAL_ 2565928476 ProfShort_Val1_4_Slope 1023 "Unknown" ;
VAL_ 2565928476 ProfShort_Val1_3_Slope 1023 "Unknown" ;
VAL_ 2565928476 ProfShort_Val1_2_RouteNumTypes 1023 "Unknown or N/A" 0 "N/A" ;
VAL_ 2565928476 ProfShort_Val1_1_Curv 1023 "Unknown" 1022 "> 0.16192" 1021 "0.16064" 960 "0.08256" 959 "0.08128" 958 "0.08064" 957 "0.08000" 896 "0.04096" 895 "0.04032" 894 "0.04000" 893 "0.03968" 833 "0.02048" 832 "0.02016" 831 "0.01984" 830 "0.01968" 768 "0.00976" 767 "0.00960" 766 "0.00952" 765 "0.00944" 704 "0.00456" 703 "0.00448" 702 "0.00444" 701 "0.00440" 640 "0.00196" 639 "0.00192" 638 "0.00190" 637 "0.00188" 576 "0.00066" 575 "0.00064" 574 "0.00063" 573 "0.00062" 513 "0.00002" 512 "0.00001" 511 "0.00000" 510 "-0.00001" 0 "< -0.16192" ;
VAL_ 2565928476 ProfShort_Val1_16_RsvdForSysSpec 1023 "Unknown or N/A" ;
VAL_ 2565928476 ProfShort_Val0_9_RsvdForStdTypes 1023 "Description for the value '0x0'" ;
VAL_ 2565928476 ProfShort_Val0_8_HeadChg 256 "N/A" 255 "N/A" 254 "Unknown" 253 "1.417° left from path dir" 252 "2.835° left from path dir" 251 "4.252° left from path dir" 250 "5.669° left from path dir" 249 "7.087° left from path dir" 248 "8.504° left from path dir" 247 "9.921° left from path dir" 246 "11.339° left from path dir" 245 "12.756° left from path dir" 244 "14.173° left from path dir" 243 "15.591° left from path dir" 242 "17.008° left from path dir" 241 "18.425° left from path dir" 240 "19.843° left from path dir" 239 "21.26° left from path dir" 238 "22.677° left from path dir" 237 "24.094° left from path dir" 236 "25.512° left from path dir" 235 "26.929° left from path dir" 234 "28.346° left from path dir" 233 "29.764° left from path dir" 232 "31.181° left from path dir" 231 "32.598° left from path dir" 230 "34.016° left from path dir" 229 "35.433° left from path dir" 228 "36.85° left from path dir" 227 "38.268° left from path dir" 226 "39.685° left from path dir" 225 "41.102° left from path dir" 224 "42.52° left from path dir" 223 "43.937° left from path dir" 222 "45.354° left from path dir" 221 "46.772° left from path dir" 220 "48.189° left from path dir" 219 "49.606° left from path dir" 218 "51.024° left from path dir" 217 "52.441° left from path dir" 216 "53.858° left from path dir" 215 "55.276° left from path dir" 214 "56.693° left from path dir" 213 "58.11° left from path dir" 212 "59.528° left from path dir" 211 "60.945° left from path dir" 210 "62.362° left from path dir" 209 "63.78° left from path dir" 208 "65.197° left from path dir" 207 "66.614° left from path dir" 206 "68.031° left from path dir" 205 "69.449° left from path dir" 204 "70.866° left from path dir" 203 "72.283° left from path dir" 202 "73.701° left from path dir" 201 "75.118° left from path dir" 200 "76.535° left from path dir" 199 "77.953° left from path dir" 198 "79.37° left from path dir" 197 "80.787° left from path dir" 196 "82.205° left from path dir" 195 "83.622° left from path dir" 194 "85.039° left from path dir" 193 "86.457° left from path dir" 192 "87.874° left from path dir" 191 "89.291° left from path dir" 190 "90.709° left from path dir" 189 "92.126° left from path dir" 188 "93.543° left from path dir" 187 "94.961° left from path dir" 186 "96.378° left from path dir" 185 "97.795° left from path dir" 184 "99.213° left from path dir" 183 "100.63° left from path dir" 182 "102.047° left from path dir" 181 "103.465° left from path dir" 180 "104.882° left from path dir" 179 "106.299° left from path dir" 178 "107.717° left from path dir" 177 "109.134° left from path dir" 176 "110.551° left from path dir" 175 "111.969° left from path dir" 174 "113.386° left from path dir" 173 "114.803° left from path dir" 172 "116.22° left from path dir" 171 "117.638° left from path dir" 170 "119.055° left from path dir" 169 "120.472° left from path dir" 168 "121.89° left from path dir" 167 "123.307° left from path dir" 166 "124.724° left from path dir" 165 "126.142° left from path dir" 164 "127.559° left from path dir" 163 "128.976° left from path dir" 162 "130.394° left from path dir" 161 "131.811° left from path dir" 160 "133.228° left from path dir" 159 "134.646° left from path dir" 158 "136.063° left from path dir" 157 "137.48° left from path dir" 156 "138.898° left from path dir" 155 "140.315° left from path dir" 154 "141.732° left from path dir" 153 "143.15° left from path dir" 152 "144.567° left from path dir" 151 "145.984° left from path dir" 150 "147.402° left from path dir" 149 "148.819° left from path dir" 148 "150.236° left from path dir" 147 "151.654° left from path dir" 146 "153.071° left from path dir" 145 "154.488° left from path dir" 144 "155.906° left from path dir" 143 "157.323° left from path dir" 142 "158.74° left from path dir" 141 "160.157° left from path dir" 140 "161.575° left from path dir" 139 "162.992° left from path dir" 138 "164.409° left from path dir" 137 "165.827° left from path dir" 136 "167.244° left from path dir" 135 "168.661° left from path dir" 134 "170.079° left from path dir" 133 "171.496° left from path dir" 132 "172.913° left from path dir" 131 "174.331° left from path dir" 130 "175.748° left from path dir" 129 "177.165° left from path dir" 128 "178.583° left from path dir" 127 "Opposite direction" 126 "178.583° right from path dir" 125 "177.165° right from path dir" 124 "175.748° right from path dir" 123 "174.331° right from path dir" 122 "172.913° right from path dir" 121 "171.496° right from path dir" 120 "170.079° right from path dir" 119 "168.661° right from path dir" 118 "167.244° right from path dir" 117 "165.827° right from path dir" 116 "164.409° right from path dir" 115 "162.992° right from path dir" 114 "161.575° right from path dir" 113 "160.157° right from path dir" 112 "158.74° right from path dir" 111 "157.323° right from path dir" 110 "155.906° right from path dir" 109 "154.488° right from path dir" 108 "153.071° right from path dir" 107 "151.654° right from path dir" 106 "150.236° right from path dir" 105 "148.819° right from path dir" 104 "147.402° right from path dir" 103 "145.984° right from path dir" 102 "144.567° right from path dir" 101 "143.15° right from path dir" 100 "141.732° right from path dir" 99 "140.315° right from path dir" 98 "138.898° right from path dir" 97 "137.48° right from path dir" 96 "136.063° right from path dir" 95 "134.646° right from path dir" 94 "133.228° right from path dir" 93 "131.811° right from path dir" 92 "130.394° right from path dir" 91 "128.976° right from path dir" 90 "127.559° right from path dir" 89 "126.142° right from path dir" 88 "124.724° right from path dir" 87 "123.307° right from path dir" 86 "121.89° right from path dir" 85 "120.472° right from path dir" 84 "119.055° right from path dir" 83 "117.638° right from path dir" 82 "116.22° right from path dir" 81 "114.803° right from path dir" 80 "113.386° right from path dir" 79 "111.969° right from path dir" 78 "110.551° right from path dir" 77 "109.134° right from path dir" 76 "107.717° right from path dir" 75 "106.299° right from path dir" 74 "104.882° right from path dir" 73 "103.465° right from path dir" 72 "102.047° right from path dir" 71 "100.63° right from path dir" 70 "99.213° right from path dir" 69 "97.795° right from path dir" 68 "96.378° right from path dir" 67 "94.961° right from path dir" 66 "93.543° right from path dir" 65 "92.126° right from path dir" 64 "90.709° right from path dir" 63 "89.291° right from path dir" 62 "87.874° right from path dir" 61 "86.457° right from path dir" 60 "85.039° right from path dir" 59 "83.622° right from path dir" 58 "82.205° right from path dir" 57 "80.787° right from path dir" 56 "79.37° right from path dir" 55 "77.953° right from path dir" 54 "76.535° right from path dir" 53 "75.118° right from path dir" 52 "73.701° right from path dir" 51 "72.283° right from path dir" 50 "70.866° right from path dir" 49 "69.449° right from path dir" 48 "68.031° right from path dir" 47 "66.614° right from path dir" 46 "65.197° right from path dir" 45 "63.78° right from path dir" 44 "62.362° right from path dir" 43 "60.945° right from path dir" 42 "59.528° right from path dir" 41 "58.11° right from path dir" 40 "56.693° right from path dir" 39 "55.276° right from path dir" 38 "53.858° right from path dir" 37 "52.441° right from path dir" 36 "51.024° right from path dir" 35 "49.606° right from path dir" 34 "48.189° right from path dir" 33 "46.772° right from path dir" 32 "45.354° right from path dir" 31 "43.937° right from path dir" 30 "42.52° right from path dir" 29 "41.102° right from path dir" 28 "39.685° right from path dir" 27 "38.268° right from path dir" 26 "36.85° right from path dir" 25 "35.433° right from path dir" 24 "34.016° right from path dir" 23 "32.598° right from path dir" 22 "31.181° right from path dir" 21 "29.764° right from path dir" 20 "28.346° right from path dir" 19 "26.929° right from path dir" 18 "25.512° right from path dir" 17 "24.094° right from path dir" 16 "22.677° right from path dir" 15 "21.26° right from path dir" 14 "19.843° right from path dir" 13 "18.425° right from path dir" 12 "17.008° right from path dir" 11 "15.591° right from path dir" 10 "14.173° right from path dir" 9 "12.756° right from path dir" 8 "11.339° right from path dir" 7 "9.921° right from path dir" 6 "8.504° right from path dir" 5 "7.087° right from path dir" 4 "5.669° right from path dir" 3 "4.252° right from path dir" 2 "2.835° right from path dir" 1 "1.417° right from path dir" 0 "In path direction" ;
VAL_ 2565928476 ProfShort_Val0_7_VarSpeedSignPos 1023 "Unknown" 0 "Unknown" ;
VAL_ 2565928476 ProfShort_Val0_6_RoadCond 1023 "Unknown" ;
VAL_ 2565928476 ProfShort_Val0_5_RoadAcc 1023 "Unknown or N/A" 0 "No access" ;
VAL_ 2565928476 ProfShort_Val0_4_Slope 1023 "Unknown" ;
VAL_ 2565928476 ProfShort_Val0_3_Slope 1023 "Unknown" ;
VAL_ 2565928476 ProfShort_Val0_2_RouteNumTypes 1023 "Unknown or N/A" 0 "N/A" ;
VAL_ 2565928476 ProfShort_Val0_1_Curv 1023 "Unknown" 1022 "> 0.16192" 1021 "0.16064" 960 "0.08256" 959 "0.08128" 958 "0.08064" 957 "0.08000" 896 "0.04096" 895 "0.04032" 894 "0.04000" 893 "0.03968" 833 "0.02048" 832 "0.02016" 831 "0.01984" 830 "0.01968" 768 "0.00976" 767 "0.00960" 766 "0.00952" 765 "0.00944" 704 "0.00456" 703 "0.00448" 702 "0.00444" 701 "0.00440" 640 "0.00196" 639 "0.00192" 638 "0.00190" 637 "0.00188" 576 "0.00066" 575 "0.00064" 574 "0.00063" 573 "0.00062" 513 "0.00002" 512 "0.00001" 511 "0.00000" 510 "-0.00001" 0 "< -0.16192" ;
VAL_ 2565928476 ProfShort_Val0_16_RsvdForSysSpec 1023 "Unknown or N/A" ;
VAL_ 2565928476 ProfShort_Update 1 "True" 0 "False" ;
VAL_ 2565928476 ProfShort_Retr 1 "True" 0 "False" ;
VAL_ 2565928476 ProfShort_ProfType 31 "Description for the value '0x1F'" 30 "Res. for system specific types" 29 "Res. for system specific types" 28 "Res. for system specific types" 27 "Res. for system specific types" 26 "Res. for system specific types" 25 "Res. for system specific types" 24 "Res. for system specific types" 23 "Res. for system specific types" 22 "Res. for system specific types" 21 "Res. for system specific types" 20 "Res. for system specific types" 19 "Res. for system specific types" 18 "Res. for system specific types" 17 "Res. for system specific types" 16 "Res. for system specific types" 15 "Res. for std types" 14 "Res. for std types" 13 "Res. for std types" 12 "Res. for std types" 11 "Res. for std types" 10 "Res. for std types" 9 "Res. for std types" 8 "Heading Change" 7 "Var Speed Sign Pos." 6 "Road condition, Step interp" 5 "Road accessibility, Step interp" 4 "Slope, Linear interp" 3 "Slope, Step interp" 2 "Route Number Types, Step interp" 1 "Curvature, Linear interp." 0 "N/A" ;
VAL_ 2565928476 ProfShort_PathIx 7 "Reserved" 0 "Unknown" ;
VAL_ 2565928476 ProfShort_Ofs 8191 "Invalid" ;
VAL_ 2565928476 ProfShort_Dist1 1023 "Invalid" ;
VAL_ 2565928476 ProfShort_CtrlPnt 1 "True" 0 "False" ;
VAL_ 2565928476 ProfShort_Accur 3 "Unknown" 2 "Lowest" 0 "Highest" ;
VAL_ 2565928476 ProfLong_Val9RsvdForStdTypes 1023 "Description for the value '0x0'" ;
VAL_ 2565928476 ProfLong_Val8RsvdForStdTypes -1 "Unknown or N/A" ;
VAL_ 2565928476 ProfLong_Val7RsvdForStdTypes -1 "Unknown or N/A" ;
VAL_ 2565928476 ProfLong_Val5RsvdForStdTypes -1 "Unknown or N/A" ;
VAL_ 2565928476 ProfLong_Val6RsvdForStdTypes -1 "Unknown or N/A" ;
VAL_ 2565928476 ProfLong_Val4RsvdForStdTypes -1 "Unknown or N/A" ;
VAL_ 2565928476 ProfLong_Val3RsvdForStdTypes -1 "Unknown or N/A" ;
VAL_ 2565928476 ProfLong_Val31RsvdForSysSpecType -1 "Unknown or N/A" ;
VAL_ 2565928476 ProfLong_Val30RsvdForSysSpecType -1 "Unknown or N/A" ;
VAL_ 2565928476 ProfLong_Val2Lat -1 "Unknown or N/A" ;
VAL_ 2565928476 ProfLong_Val1Long -1 "Unknown or N/A" ;
VAL_ 2565928476 ProfLong_Val29RsvdForSysSpecType -1 "Unknown or N/A" ;
VAL_ 2565928476 ProfLong_Val28RsvdForSysSpecType -1 "Unknown or N/A" ;
VAL_ 2565928476 ProfLong_Val27RsvdForSysSpecType -1 "Unknown or N/A" ;
VAL_ 2565928476 ProfLong_Val26RsvdForSysSpecType -1 "Unknown or N/A" ;
VAL_ 2565928476 ProfLong_Val24RsvdForSysSpecType -1 "Unknown or N/A" ;
VAL_ 2565928476 ProfLong_Val23RsvdForSysSpecType -1 "Unknown or N/A" ;
VAL_ 2565928476 ProfLong_Val21RsvdForSysSpecType -1 "Unknown or N/A" ;
VAL_ 2565928476 ProfLong_Val20RsvdForSysSpecType -1 "Unknown or N/A" ;
VAL_ 2565928476 ProfLong_Val22RsvdForSysSpecType -1 "Unknown or N/A" ;
VAL_ 2565928476 ProfLong_Val19RsvdForSysSpecType -1 "Unknown or N/A" ;
VAL_ 2565928476 ProfLong_Val18RsvdForSysSpecType -1 "Unknown or N/A" ;
VAL_ 2565928476 ProfLong_Val17RsvdForSysSpecType -1 "Unknown or N/A" ;
VAL_ 2565928476 ProfLong_Val16RsvdForSysSpecType -1 "Unknown or N/A" ;
VAL_ 2565928476 ProfLong_Val15RsvdForStdTypes -1 "Unknown or N/A" ;
VAL_ 2565928476 ProfLong_Val14RsvdForStdTypes -1 "Unknown or N/A" ;
VAL_ 2565928476 ProfLong_Val13RsvdForStdTypes -1 "Unknown or N/A" ;
VAL_ 2565928476 ProfLong_Val12RsvdForStdTypes -1 "Unknown or N/A" ;
VAL_ 2565928476 ProfLong_Val11RsvdForStdTypes -1 "Unknown or N/A" ;
VAL_ 2565928476 ProfLong_Val10RsvdForStdTypes -1 "Unknown or N/A" ;
VAL_ 2565928476 ProfLong_Update 1 "True" 0 "False" ;
VAL_ 2565928476 ProfLong_Retr 1 "True" 0 "False" ;
VAL_ 2565928476 ProfLong_ProfType 31 "Res. for system specific types" 30 "Res. for system specific types" 29 "Res. for system specific types" 28 "Res. for system specific types" 27 "Res. for system specific types" 26 "Res. for system specific types" 25 "Res. for system specific types" 24 "Res. for system specific types" 23 "Res. for system specific types" 22 "Res. for system specific types" 21 "Res. for system specific types" 20 "Res. for system specific types" 19 "Res. for system specific types" 18 "Res. for system specific types" 17 "Res. for system specific types" 16 "Res. for system specific types" 15 "Res. for std types" 14 "Res. for std types" 13 "Res. for std types" 12 "Res. for std types" 11 "Res. for std types" 10 "Res. for std types" 9 "Res. for std types" 8 "Res. for std types" 7 "Res. for std types" 6 "Res. for std types" 5 "Res. for std types" 4 "Res. for std types" 3 "Res. for std types" 2 "Latitude, Linear interp." 1 "Longitude, Linear interp." 0 "N/A" ;
VAL_ 2565928476 ProfLong_PathIx 7 "Reserved" 0 "Unknown" ;
VAL_ 2565928476 ProfLong_Ofs 8191 "Invalid" ;
VAL_ 2565928476 ProfLong_CtrlPnt 1 "True" 0 "False" ;
VAL_ 2565928476 Pos_Speed 511 "N/A" 510 "=+89.2 m/s" ;
VAL_ 2565928476 Pos_RelHead 255 "N/A" 254 "Unknown" 253 "1.417° left from path dir" 252 "2.835° left from path dir" 251 "4.252° left from path dir" 250 "5.669° left from path dir" 249 "7.087° left from path dir" 248 "8.504° left from path dir" 247 "9.921° left from path dir" 246 "11.339° left from path dir" 245 "12.756° left from path dir" 244 "14.173° left from path dir" 243 "15.591° left from path dir" 242 "17.008° left from path dir" 241 "18.425° left from path dir" 240 "19.843° left from path dir" 239 "21.26° left from path dir" 238 "22.677° left from path dir" 237 "24.094° left from path dir" 236 "25.512° left from path dir" 235 "26.929° left from path dir" 234 "28.346° left from path dir" 233 "29.764° left from path dir" 232 "31.181° left from path dir" 231 "32.598° left from path dir" 230 "34.016° left from path dir" 229 "35.433° left from path dir" 228 "36.85° left from path dir" 227 "38.268° left from path dir" 226 "39.685° left from path dir" 225 "41.102° left from path dir" 224 "42.52° left from path dir" 223 "43.937° left from path dir" 222 "45.354° left from path dir" 221 "46.772° left from path dir" 220 "48.189° left from path dir" 219 "49.606° left from path dir" 218 "51.024° left from path dir" 217 "52.441° left from path dir" 216 "53.858° left from path dir" 215 "55.276° left from path dir" 214 "56.693° left from path dir" 213 "58.11° left from path dir" 212 "59.528° left from path dir" 211 "60.945° left from path dir" 210 "62.362° left from path dir" 209 "63.78° left from path dir" 208 "65.197° left from path dir" 207 "66.614° left from path dir" 206 "68.031° left from path dir" 205 "69.449° left from path dir" 204 "70.866° left from path dir" 203 "72.283° left from path dir" 202 "73.701° left from path dir" 201 "75.118° left from path dir" 200 "76.535° left from path dir" 199 "77.953° left from path dir" 198 "79.37° left from path dir" 197 "80.787° left from path dir" 196 "82.205° left from path dir" 195 "83.622° left from path dir" 194 "85.039° left from path dir" 193 "86.457° left from path dir" 192 "87.874° left from path dir" 191 "89.291° left from path dir" 190 "90.709° left from path dir" 189 "92.126° left from path dir" 188 "93.543° left from path dir" 187 "94.961° left from path dir" 186 "96.378° left from path dir" 185 "97.795° left from path dir" 184 "99.213° left from path dir" 183 "100.63° left from path dir" 182 "102.047° left from path dir" 181 "103.465° left from path dir" 180 "104.882° left from path dir" 179 "106.299° left from path dir" 178 "107.717° left from path dir" 177 "109.134° left from path dir" 176 "110.551° left from path dir" 175 "111.969° left from path dir" 174 "113.386° left from path dir" 173 "114.803° left from path dir" 172 "116.22° left from path dir" 171 "117.638° left from path dir" 170 "119.055° left from path dir" 169 "120.472° left from path dir" 168 "121.89° left from path dir" 167 "123.307° left from path dir" 166 "124.724° left from path dir" 165 "126.142° left from path dir" 164 "127.559° left from path dir" 163 "128.976° left from path dir" 162 "130.394° left from path dir" 161 "131.811° left from path dir" 160 "133.228° left from path dir" 159 "134.646° left from path dir" 158 "136.063° left from path dir" 157 "137.48° left from path dir" 156 "138.898° left from path dir" 155 "140.315° left from path dir" 154 "141.732° left from path dir" 153 "143.15° left from path dir" 152 "144.567° left from path dir" 151 "145.984° left from path dir" 150 "147.402° left from path dir" 149 "148.819° left from path dir" 148 "150.236° left from path dir" 147 "151.654° left from path dir" 146 "153.071° left from path dir" 145 "154.488° left from path dir" 144 "155.906° left from path dir" 143 "157.323° left from path dir" 142 "158.74° left from path dir" 141 "160.157° left from path dir" 140 "161.575° left from path dir" 139 "162.992° left from path dir" 138 "164.409° left from path dir" 137 "165.827° left from path dir" 136 "167.244° left from path dir" 135 "168.661° left from path dir" 134 "170.079° left from path dir" 133 "171.496° left from path dir" 132 "172.913° left from path dir" 131 "174.331° left from path dir" 130 "175.748° left from path dir" 129 "177.165° left from path dir" 128 "178.583° left from path dir" 127 "Opposite direction" 126 "178.583° right from path dir" 125 "177.165° right from path dir" 124 "175.748° right from path dir" 123 "174.331° right from path dir" 122 "172.913° right from path dir" 121 "171.496° right from path dir" 120 "170.079° right from path dir" 119 "168.661° right from path dir" 118 "167.244° right from path dir" 117 "165.827° right from path dir" 116 "164.409° right from path dir" 115 "162.992° right from path dir" 114 "161.575° right from path dir" 113 "160.157° right from path dir" 112 "158.74° right from path dir" 111 "157.323° right from path dir" 110 "155.906° right from path dir" 109 "154.488° right from path dir" 108 "153.071° right from path dir" 107 "151.654° right from path dir" 106 "150.236° right from path dir" 105 "148.819° right from path dir" 104 "147.402° right from path dir" 103 "145.984° right from path dir" 102 "144.567° right from path dir" 101 "143.15° right from path dir" 100 "141.732° right from path dir" 99 "140.315° right from path dir" 98 "138.898° right from path dir" 97 "137.48° right from path dir" 96 "136.063° right from path dir" 95 "134.646° right from path dir" 94 "133.228° right from path dir" 93 "131.811° right from path dir" 92 "130.394° right from path dir" 91 "128.976° right from path dir" 90 "127.559° right from path dir" 89 "126.142° right from path dir" 88 "124.724° right from path dir" 87 "123.307° right from path dir" 86 "121.89° right from path dir" 85 "120.472° right from path dir" 84 "119.055° right from path dir" 83 "117.638° right from path dir" 82 "116.22° right from path dir" 81 "114.803° right from path dir" 80 "113.386° right from path dir" 79 "111.969° right from path dir" 78 "110.551° right from path dir" 77 "109.134° right from path dir" 76 "107.717° right from path dir" 75 "106.299° right from path dir" 74 "104.882° right from path dir" 73 "103.465° right from path dir" 72 "102.047° right from path dir" 71 "100.63° right from path dir" 70 "99.213° right from path dir" 69 "97.795° right from path dir" 68 "96.378° right from path dir" 67 "94.961° right from path dir" 66 "93.543° right from path dir" 65 "92.126° right from path dir" 64 "90.709° right from path dir" 63 "89.291° right from path dir" 62 "87.874° right from path dir" 61 "86.457° right from path dir" 60 "85.039° right from path dir" 59 "83.622° right from path dir" 58 "82.205° right from path dir" 57 "80.787° right from path dir" 56 "79.37° right from path dir" 55 "77.953° right from path dir" 54 "76.535° right from path dir" 53 "75.118° right from path dir" 52 "73.701° right from path dir" 51 "72.283° right from path dir" 50 "70.866° right from path dir" 49 "69.449° right from path dir" 48 "68.031° right from path dir" 47 "66.614° right from path dir" 46 "65.197° right from path dir" 45 "63.78° right from path dir" 44 "62.362° right from path dir" 43 "60.945° right from path dir" 42 "59.528° right from path dir" 41 "58.11° right from path dir" 40 "56.693° right from path dir" 39 "55.276° right from path dir" 38 "53.858° right from path dir" 37 "52.441° right from path dir" 36 "51.024° right from path dir" 35 "49.606° right from path dir" 34 "48.189° right from path dir" 33 "46.772° right from path dir" 32 "45.354° right from path dir" 31 "43.937° right from path dir" 30 "42.52° right from path dir" 29 "41.102° right from path dir" 28 "39.685° right from path dir" 27 "38.268° right from path dir" 26 "36.85° right from path dir" 25 "35.433° right from path dir" 24 "34.016° right from path dir" 23 "32.598° right from path dir" 22 "31.181° right from path dir" 21 "29.764° right from path dir" 20 "28.346° right from path dir" 19 "26.929° right from path dir" 18 "25.512° right from path dir" 17 "24.094° right from path dir" 16 "22.677° right from path dir" 15 "21.26° right from path dir" 14 "19.843° right from path dir" 13 "18.425° right from path dir" 12 "17.008° right from path dir" 11 "15.591° right from path dir" 10 "14.173° right from path dir" 9 "12.756° right from path dir" 8 "11.339° right from path dir" 7 "9.921° right from path dir" 6 "8.504° right from path dir" 5 "7.087° right from path dir" 4 "5.669° right from path dir" 3 "4.252° right from path dir" 2 "2.835° right from path dir" 1 "1.417° right from path dir" 0 "In path direction" ;
VAL_ 2565928476 Pos_PosProb 31 "N/A" 0 "Unknown" ;
VAL_ 2565928476 Pos_PosConf 7 "N/A" ;
VAL_ 2565928476 Pos_PosAge 511 "N/A" 510 "2545 ms" ;
VAL_ 2565928476 Pos_PathIx 7 "Reserved" 3 "Av2HP not calibrated" 2 "Not on-road" 1 "Not in Digitized Area" 0 "Unknown" ;
VAL_ 2565928476 Pos_Ofs 8191 "Invalid" ;
VAL_ 2565928476 Pos_CurLane 7 "N/A" 6 "Reserved" 5 "Middle (road with >3 lanes)" 4 "Right-most lane" 3 "Left-most lane" 2 "Single-lane road" 1 "Emergency lane" 0 "Unknown" ;
VAL_ 2565928476 MsgType 7 "Reserved" 6 "META-DATA" 5 "PROFILE LONG" 4 "PROFILE SHORT" 3 "STUB" 2 "SEGMENT" 1 "POSITION" 0 "Reserved" ;
VAL_ 2565928476 Meta_MapProvider 7 "Description for the value '0x7'" 6 "Reserved" 5 "Reserved" 4 "Reserved" 3 "Zenrin" 2 "TeleAtlas" 1 "NAVTEQ" 0 "Unknown" ;
VAL_ 2565928476 Meta_CntryCode 0 "Unknown" ;
VAL_ 2565928476 Meta_HwVer 0 "Unknown" ;
VAL_ 2565928476 Meta_DrivSide 1 "Right" 0 "Left." ;
VAL_ 2565928476 Meta_RegionCode 32767 "N/A" 0 "Unknown" ;
VAL_ 2565928476 Meta_MapVetYr 63 "N/A" ;
VAL_ 2565928476 Meta_SpeedUnits 1 "mph" 0 "km/h" ;
VAL_ 2564554494 FlowStatus 2 "Overflow" 1 "Wait " 0 "Continue To Send" ;
VAL_ 2564554494 ProtocolCtrlInformation 3 "Flow control " 2 "Consecutive frame" 1 "First frame" 0 "Single frame" ;
VAL_ 2564488958 FlowStatus 2 "Overflow" 1 "Wait " 0 "Continue To Send" ;
VAL_ 2564488958 ProtocolCtrlInformation 3 "Flow control " 2 "Consecutive frame" 1 "First frame" 0 "Single frame" ;
VAL_ 2566741502 FlashRedStopLamp 3 "Unavailable / Do Not Flash" 2 "Reserved" 1 "Fast Flash" 0 "Slow Flash" ;
VAL_ 2566741502 FlashProtectLamp 3 "Unavailable / Do Not Flash" 2 "Reserved" 1 "Fast Flash" 0 "Slow Flash" ;
VAL_ 2566741502 FlashMalfuncIndicatorLamp 3 "Unavailable / Do Not Flash" 2 "Reserved" 1 "Fast Flash" 0 "Slow Flash" ;
VAL_ 2566741502 FlashAmberWarningLamp 3 "Unavailable / Do Not Flash" 2 "Reserved" 1 "Fast Flash" 0 "Slow Flash" ;
VAL_ 2566741502 MalfunctionIndicatorLampStatus 3 "Not available" 2 "Reserved" 1 "Lamp on" 0 "Lamp off" ;
VAL_ 2566741502 AmberWarningLampStatus 3 "Not available" 2 "Reserved" 1 "Lamp on" 0 "Lamp off" ;
VAL_ 2566741502 RedStopLampState 3 "Not available" 2 "Reserved" 1 "Lamp on" 0 "Lamp off" ;
VAL_ 2566741502 ProtectLampStatus 3 "Not available" 2 "Reserved" 1 "Lamp on" 0 "Lamp off" ;
VAL_ 2566741758 FlashRedStopLamp 3 "Unavailable / Do Not Flash" 2 "Reserved" 1 "Fast Flash" 0 "Slow Flash" ;
VAL_ 2566741758 FlashProtectLamp 3 "Unavailable / Do Not Flash" 2 "Reserved" 1 "Fast Flash" 0 "Slow Flash" ;
VAL_ 2566741758 FlashMalfuncIndicatorLamp 3 "Unavailable / Do Not Flash" 2 "Reserved" 1 "Fast Flash" 0 "Slow Flash" ;
VAL_ 2566741758 FlashAmberWarningLamp 3 "Unavailable / Do Not Flash" 2 "Reserved" 1 "Fast Flash" 0 "Slow Flash" ;
VAL_ 2566741758 MalfunctionIndicatorLampStatus 3 "Not available" 2 "Reserved" 1 "Lamp on" 0 "Lamp off" ;
VAL_ 2566741758 AmberWarningLampStatus 3 "Not available" 2 "Reserved" 1 "Lamp on" 0 "Lamp off" ;
VAL_ 2566741758 RedStopLampState 3 "Not available" 2 "Reserved" 1 "Lamp on" 0 "Lamp off" ;
VAL_ 2566741758 ProtectLampStatus 3 "Not available" 2 "Reserved" 1 "Lamp on" 0 "Lamp off" ;
VAL_ 2566742014 FlashRedStopLamp 3 "Unavailable / Do Not Flash" 2 "Reserved" 1 "Fast Flash" 0 "Slow Flash" ;
VAL_ 2566742014 FlashProtectLamp 3 "Unavailable / Do Not Flash" 2 "Reserved" 1 "Fast Flash" 0 "Slow Flash" ;
VAL_ 2566742014 FlashMalfuncIndicatorLamp 3 "Unavailable / Do Not Flash" 2 "Reserved" 1 "Fast Flash" 0 "Slow Flash" ;
VAL_ 2566742014 FlashAmberWarningLamp 3 "Unavailable / Do Not Flash" 2 "Reserved" 1 "Fast Flash" 0 "Slow Flash" ;
VAL_ 2566742014 MalfunctionIndicatorLampStatus 3 "Not available" 2 "Reserved" 1 "Lamp on" 0 "Lamp off" ;
VAL_ 2566742014 AmberWarningLampStatus 3 "Not available" 2 "Reserved" 1 "Lamp on" 0 "Lamp off" ;
VAL_ 2566742014 RedStopLampState 3 "Not available" 2 "Reserved" 1 "Lamp on" 0 "Lamp off" ;
VAL_ 2566742014 ProtectLampStatus 3 "Not available" 2 "Reserved" 1 "Lamp on" 0 "Lamp off" ;
VAL_ 2560622334 FlashRedStopLamp 3 "Unavailable / Do Not Flash" 2 "Reserved" 1 "Fast Flash" 0 "Slow Flash" ;
VAL_ 2560622334 FlashProtectLamp 3 "Unavailable / Do Not Flash" 2 "Reserved" 1 "Fast Flash" 0 "Slow Flash" ;
VAL_ 2560622334 FlashMalfuncIndicatorLamp 3 "Unavailable / Do Not Flash" 2 "Reserved" 1 "Fast Flash" 0 "Slow Flash" ;
VAL_ 2560622334 FlashAmberWarningLamp 3 "Unavailable / Do Not Flash" 2 "Reserved" 1 "Fast Flash" 0 "Slow Flash" ;
VAL_ 2560622334 MalfunctionIndicatorLampStatus 3 "Not available" 2 "Reserved" 1 "Lamp on" 0 "Lamp off" ;
VAL_ 2560622334 AmberWarningLampStatus 3 "Not available" 2 "Reserved" 1 "Lamp on" 0 "Lamp off" ;
VAL_ 2560622334 RedStopLampState 3 "Not available" 2 "Reserved" 1 "Lamp on" 0 "Lamp off" ;
VAL_ 2560622334 ProtectLampStatus 3 "Not available" 2 "Reserved" 1 "Lamp on" 0 "Lamp off" ;
VAL_ 2566744062 ZeroNetVehicleWeightChange 3 "NotAvailable_NotApplicable" 2 "Reserved" 1 "ZeroNetVehicleWeightChange" 0 "NChangeToNetVehicleWeightChange" ;
VAL_ 2566750462 FlashRedStopLamp 3 "Unavailable / Do Not Flash" 2 "Reserved" 1 "Fast Flash" 0 "Slow Flash" ;
VAL_ 2566750462 FlashProtectLamp 3 "Unavailable / Do Not Flash" 2 "Reserved" 1 "Fast Flash" 0 "Slow Flash" ;
VAL_ 2566750462 FlashMalfuncIndicatorLamp 3 "Unavailable / Do Not Flash" 2 "Reserved" 1 "Fast Flash" 0 "Slow Flash" ;
VAL_ 2566750462 FlashAmberWarningLamp 3 "Unavailable / Do Not Flash" 2 "Reserved" 1 "Fast Flash" 0 "Slow Flash" ;
VAL_ 2566750462 MalfunctionIndicatorLampStatus 3 "Not available" 2 "Reserved" 1 "Lamp on" 0 "Lamp off" ;
VAL_ 2566750462 AmberWarningLampStatus 3 "Not available" 2 "Reserved" 1 "Lamp on" 0 "Lamp off" ;
VAL_ 2566750462 RedStopLampState 3 "Not available" 2 "Reserved" 1 "Lamp on" 0 "Lamp off" ;
VAL_ 2566750462 ProtectLampStatus 3 "Not available" 2 "Reserved" 1 "Lamp on" 0 "Lamp off" ;
VAL_ 2566750974 FlashRedStopLamp 3 "Unavailable / Do Not Flash" 2 "Reserved" 1 "Fast Flash" 0 "Slow Flash" ;
VAL_ 2566750974 FlashProtectLamp 3 "Unavailable / Do Not Flash" 2 "Reserved" 1 "Fast Flash" 0 "Slow Flash" ;
VAL_ 2566750974 FlashMalfuncIndicatorLamp 3 "Unavailable / Do Not Flash" 2 "Reserved" 1 "Fast Flash" 0 "Slow Flash" ;
VAL_ 2566750974 FlashAmberWarningLamp 3 "Unavailable / Do Not Flash" 2 "Reserved" 1 "Fast Flash" 0 "Slow Flash" ;
VAL_ 2566750974 MalfunctionIndicatorLampStatus 3 "Not available" 2 "Reserved" 1 "Lamp on" 0 "Lamp off" ;
VAL_ 2566750974 AmberWarningLampStatus 3 "Not available" 2 "Reserved" 1 "Lamp on" 0 "Lamp off" ;
VAL_ 2566750974 RedStopLampState 3 "Not available" 2 "Reserved" 1 "Lamp on" 0 "Lamp off" ;
VAL_ 2566750974 ProtectLampStatus 3 "Not available" 2 "Reserved" 1 "Lamp on" 0 "Lamp off" ;
VAL_ 2566754558 AETCDataCollectionStandard 15 "NotAvailable" 1 "1101NotDefined" 0 "SAEJ1995" ;
VAL_ 2566749950 RightHeadlampLightDistribution 15 "NotAvailable" 8 "1110Reserved" 7 "DffrntLghtDstrbtnsNtAvlblNAFSDs" 6 "LghtDstrbtnFlrMdlIsDmgdCrrntPsM" 5 "LghtDstrbtnFlSfPsMdlIsDmgdCrrnt" 4 "LghtDstrbtnAdvrsWthrAdvrsWthrLg" 3 "LghtDstrbtnHghBmHghBmDstrbtnOfT" 2 "LghtDstrbtnMtrwyTskOfMtrwyLghtI" 1 "LghtDstrbtnCntryCntryLghtIsMstl" 0 "LghtDstrbtnTwnBscLghtDstrbtnFrT" ;
VAL_ 2566749950 LeftHeadlampLightDistribution 15 "NotAvailable" 8 "1110Reserved" 7 "DffrntLghtDstrbtnsNtAvlblNAFSDs" 6 "LghtDstrbtnFlrMdlIsDmgdCrrntPsM" 5 "LghtDstrbtnFlSfPsMdlIsDmgdCrrnt" 4 "LghtDstrbtnAdvrsWthrAdvrsWthrLg" 3 "LghtDstrbtnHghBmHghBmDstrbtnOfT" 2 "LghtDstrbtnMtrwyTskOfMtrwyLghtI" 1 "LghtDstrbtnCntryCntryLghtIsMstl" 0 "LghtDstrbtnTwnBscLghtDstrbtnFrT" ;
VAL_ 2566749950 RghtHeadlampDynamicBendingLight 7 "NotAvailable" 4 "110Reserved" 3 "DynmcBndngLghtFlrBndngLghtDsNtW" 2 "DynmcBndngLghtFlSfPsBndngLghtIs" 1 "DynmcBndngLghtIsWrkngPrprlyNrml" 0 "DynmcBndngLghtDctvtdThrIsNPrblm" ;
VAL_ 2566749950 LeftHeadlampDynamicBendingLight 7 "NotAvailable" 4 "110Reserved" 3 "DynmcBndngLghtFlrBndngLghtDsNtW" 2 "DynmcBndngLghtFlSfPsBndngLghtIs" 1 "DynmcBndngLghtIsWrkngPrprlyNrml" 0 "DynmcBndngLghtDctvtdThrIsNPrblm" ;
VAL_ 2566838539 AuxI_O16 3 "NotAvailable" 2 "Error" 1 "AuxChannelOn" 0 "AuxChannelOff" ;
VAL_ 2566838539 AuxI_O15 3 "NotAvailable" 2 "Error" 1 "AuxChannelOn" 0 "AuxChannelOff" ;
VAL_ 2566838539 AuxI_O14 3 "NotAvailable" 2 "Error" 1 "AuxChannelOn" 0 "AuxChannelOff" ;
VAL_ 2566838539 AuxI_O13 3 "NotAvailable" 2 "Error" 1 "AuxChannelOn" 0 "AuxChannelOff" ;
VAL_ 2566838539 AuxI_O12 3 "NotAvailable" 2 "Error" 1 "AuxChannelOn" 0 "AuxChannelOff" ;
VAL_ 2566838539 AuxI_O11 3 "NotAvailable" 2 "Error" 1 "AuxChannelOn" 0 "AuxChannelOff" ;
VAL_ 2566838539 AuxI_O10 3 "NotAvailable" 2 "Error" 1 "AuxChannelOn" 0 "AuxChannelOff" ;
VAL_ 2566838539 AuxI_O09 3 "NotAvailable" 2 "Error" 1 "AuxChannelOn" 0 "AuxChannelOff" ;
VAL_ 2566838539 AuxI_O08_GearboxNeutralPos_AUX 3 "NotAvailable" 2 "Error" 1 "SecuredNeutralPosition" 0 "NotInSecuredNeutralPosition" ;
VAL_ 2566838539 AuxI_O07_TrailerABSFulOper_AUX 3 "NotAvailable" 2 "Error" 1 "TrailerABSFullyOperational" 0 "TrailerABSNotFullyOperational" ;
VAL_ 2566838539 AuxI_O06_TrailerABSDetected_AUX 3 "NotAvailable" 2 "Error" 1 "TrailerABSDetected" 0 "TrailerABSNotDetected" ;
VAL_ 2566838539 AuxI_O05_TrailerConnected_AUX 3 "NotAvailable" 1 "TrailerConnected" 0 "TrailerNotConnected" ;
VAL_ 2566838539 AuxI_O04 3 "NotAvailable" 2 "Error" 1 "AuxChannelOn" 0 "AuxChannelOff" ;
VAL_ 2566838539 AuxI_O03 3 "NotAvailable" 2 "Error" 1 "AuxChannelOn" 0 "AuxChannelOff" ;
VAL_ 2566838539 AuxI_O01 3 "NotAvailable" 2 "Error" 1 "AuxChannelOn" 0 "AuxChannelOff" ;
VAL_ 2561146622 AuxI_O45 3 "NtAvlblTkNoActionDependingOnApp" 2 "ErrrIndctrNotUsedDependingOnApp" 1 "AuxChannelOn" 0 "AuxChannelOff" ;
VAL_ 2561146622 AuxI_O46 3 "NtAvlblTkNoActionDependingOnApp" 2 "ErrrIndctrNotUsedDependingOnApp" 1 "AuxChannelOn" 0 "AuxChannelOff" ;
VAL_ 2561146622 AuxI_O47 3 "NtAvlblTkNoActionDependingOnApp" 2 "ErrrIndctrNotUsedDependingOnApp" 1 "AuxChannelOn" 0 "AuxChannelOff" ;
VAL_ 2561146622 AuxI_O48 3 "NtAvlblTkNoActionDependingOnApp" 2 "ErrrIndctrNotUsedDependingOnApp" 1 "AuxChannelOn" 0 "AuxChannelOff" ;
VAL_ 2561146622 AuxI_O41 3 "NtAvlblTkNoActionDependingOnApp" 2 "ErrrIndctrNotUsedDependingOnApp" 1 "AuxChannelOn" 0 "AuxChannelOff" ;
VAL_ 2561146622 AuxI_O42 3 "NtAvlblTkNoActionDependingOnApp" 2 "ErrrIndctrNotUsedDependingOnApp" 1 "AuxChannelOn" 0 "AuxChannelOff" ;
VAL_ 2561146622 AuxI_O43 3 "NtAvlblTkNoActionDependingOnApp" 2 "ErrrIndctrNotUsedDependingOnApp" 1 "AuxChannelOn" 0 "AuxChannelOff" ;
VAL_ 2561146622 AuxI_O44 3 "NtAvlblTkNoActionDependingOnApp" 2 "ErrrIndctrNotUsedDependingOnApp" 1 "AuxChannelOn" 0 "AuxChannelOff" ;
VAL_ 2561146622 AuxI_O37 3 "NtAvlblTkNoActionDependingOnApp" 2 "ErrrIndctrNotUsedDependingOnApp" 1 "AuxChannelOn" 0 "AuxChannelOff" ;
VAL_ 2561146622 AuxI_O38 3 "NtAvlblTkNoActionDependingOnApp" 2 "ErrrIndctrNotUsedDependingOnApp" 1 "AuxChannelOn" 0 "AuxChannelOff" ;
VAL_ 2561146622 AuxI_O39 3 "NtAvlblTkNoActionDependingOnApp" 2 "ErrrIndctrNotUsedDependingOnApp" 1 "AuxChannelOn" 0 "AuxChannelOff" ;
VAL_ 2561146622 AuxI_O40 3 "NtAvlblTkNoActionDependingOnApp" 2 "ErrrIndctrNotUsedDependingOnApp" 1 "AuxChannelOn" 0 "AuxChannelOff" ;
VAL_ 2561146622 AuxI_O33 3 "NtAvlblTkNoActionDependingOnApp" 2 "ErrrIndctrNotUsedDependingOnApp" 1 "AuxChannelOn" 0 "AuxChannelOff" ;
VAL_ 2561146622 AuxI_O34 3 "NtAvlblTkNoActionDependingOnApp" 2 "ErrrIndctrNotUsedDependingOnApp" 1 "AuxChannelOn" 0 "AuxChannelOff" ;
VAL_ 2561146622 AuxI_O35 3 "NtAvlblTkNoActionDependingOnApp" 2 "ErrrIndctrNotUsedDependingOnApp" 1 "AuxChannelOn" 0 "AuxChannelOff" ;
VAL_ 2561146622 AuxI_O36 3 "NtAvlblTkNoActionDependingOnApp" 2 "ErrrIndctrNotUsedDependingOnApp" 1 "AuxChannelOn" 0 "AuxChannelOff" ;
VAL_ 2561146622 AuxI_O29 3 "NtAvlblTkNoActionDependingOnApp" 2 "ErrrIndctrNotUsedDependingOnApp" 1 "AuxChannelOn" 0 "AuxChannelOff" ;
VAL_ 2561146622 AuxI_O30 3 "NtAvlblTkNoActionDependingOnApp" 2 "ErrrIndctrNotUsedDependingOnApp" 1 "AuxChannelOn" 0 "AuxChannelOff" ;
VAL_ 2561146622 AuxI_O31 3 "NtAvlblTkNoActionDependingOnApp" 2 "ErrrIndctrNotUsedDependingOnApp" 1 "AuxChannelOn" 0 "AuxChannelOff" ;
VAL_ 2561146622 AuxI_O32 3 "NtAvlblTkNoActionDependingOnApp" 2 "ErrrIndctrNotUsedDependingOnApp" 1 "AuxChannelOn" 0 "AuxChannelOff" ;
VAL_ 2561146622 AuxI_O25 3 "NtAvlblTkNoActionDependingOnApp" 2 "ErrrIndctrNotUsedDependingOnApp" 1 "AuxChannelOn" 0 "AuxChannelOff" ;
VAL_ 2561146622 AuxI_O26 3 "NtAvlblTkNoActionDependingOnApp" 2 "ErrrIndctrNotUsedDependingOnApp" 1 "AuxChannelOn" 0 "AuxChannelOff" ;
VAL_ 2561146622 AuxI_O27 3 "NtAvlblTkNoActionDependingOnApp" 2 "ErrrIndctrNotUsedDependingOnApp" 1 "AuxChannelOn" 0 "AuxChannelOff" ;
VAL_ 2561146622 AuxI_O28 3 "NtAvlblTkNoActionDependingOnApp" 2 "ErrrIndctrNotUsedDependingOnApp" 1 "AuxChannelOn" 0 "AuxChannelOff" ;
VAL_ 2561146622 AuxI_O21 3 "NtAvlblTkNoActionDependingOnApp" 2 "ErrrIndctrNotUsedDependingOnApp" 1 "AuxChannelOn" 0 "AuxChannelOff" ;
VAL_ 2561146622 AuxI_O22 3 "NtAvlblTkNoActionDependingOnApp" 2 "ErrrIndctrNotUsedDependingOnApp" 1 "AuxChannelOn" 0 "AuxChannelOff" ;
VAL_ 2561146622 AuxI_O23 3 "NtAvlblTkNoActionDependingOnApp" 2 "ErrrIndctrNotUsedDependingOnApp" 1 "AuxChannelOn" 0 "AuxChannelOff" ;
VAL_ 2561146622 AuxI_O24 3 "NtAvlblTkNoActionDependingOnApp" 2 "ErrrIndctrNotUsedDependingOnApp" 1 "AuxChannelOn" 0 "AuxChannelOff" ;
VAL_ 2561146622 AuxI_O17 3 "NtAvlblTkNoActionDependingOnApp" 2 "ErrrIndctrNotUsedDependingOnApp" 1 "AuxChannelOn" 0 "AuxChannelOff" ;
VAL_ 2561146622 AuxI_O18 3 "NtAvlblTkNoActionDependingOnApp" 2 "ErrrIndctrNotUsedDependingOnApp" 1 "AuxChannelOn" 0 "AuxChannelOff" ;
VAL_ 2561146622 AuxI_O19 3 "NtAvlblTkNoActionDependingOnApp" 2 "ErrrIndctrNotUsedDependingOnApp" 1 "AuxChannelOn" 0 "AuxChannelOff" ;
VAL_ 2561146622 AuxI_O20 3 "NtAvlblTkNoActionDependingOnApp" 2 "ErrrIndctrNotUsedDependingOnApp" 1 "AuxChannelOn" 0 "AuxChannelOff" ;
VAL_ 2561081086 AuxI_O77 3 "NtAvlblTkNoActionDependingOnApp" 2 "ErrrIndctrNotUsedDependingOnApp" 1 "AuxChannelOn" 0 "AuxChannelOff" ;
VAL_ 2561081086 AuxI_O78 3 "NtAvlblTkNoActionDependingOnApp" 2 "ErrrIndctrNotUsedDependingOnApp" 1 "AuxChannelOn" 0 "AuxChannelOff" ;
VAL_ 2561081086 AuxI_O79 3 "NtAvlblTkNoActionDependingOnApp" 2 "ErrrIndctrNotUsedDependingOnApp" 1 "AuxChannelOn" 0 "AuxChannelOff" ;
VAL_ 2561081086 AuxI_O80 3 "NtAvlblTkNoActionDependingOnApp" 2 "ErrrIndctrNotUsedDependingOnApp" 1 "AuxChannelOn" 0 "AuxChannelOff" ;
VAL_ 2561081086 AuxI_O73 3 "NtAvlblTkNoActionDependingOnApp" 2 "ErrrIndctrNotUsedDependingOnApp" 1 "AuxChannelOn" 0 "AuxChannelOff" ;
VAL_ 2561081086 AuxI_O74 3 "NtAvlblTkNoActionDependingOnApp" 2 "ErrrIndctrNotUsedDependingOnApp" 1 "AuxChannelOn" 0 "AuxChannelOff" ;
VAL_ 2561081086 AuxI_O75 3 "NtAvlblTkNoActionDependingOnApp" 2 "ErrrIndctrNotUsedDependingOnApp" 1 "AuxChannelOn" 0 "AuxChannelOff" ;
VAL_ 2561081086 AuxI_O76 3 "NtAvlblTkNoActionDependingOnApp" 2 "ErrrIndctrNotUsedDependingOnApp" 1 "AuxChannelOn" 0 "AuxChannelOff" ;
VAL_ 2561081086 AuxI_O69 3 "NtAvlblTkNoActionDependingOnApp" 2 "ErrrIndctrNotUsedDependingOnApp" 1 "AuxChannelOn" 0 "AuxChannelOff" ;
VAL_ 2561081086 AuxI_O70 3 "NtAvlblTkNoActionDependingOnApp" 2 "ErrrIndctrNotUsedDependingOnApp" 1 "AuxChannelOn" 0 "AuxChannelOff" ;
VAL_ 2561081086 AuxI_O71 3 "NtAvlblTkNoActionDependingOnApp" 2 "ErrrIndctrNotUsedDependingOnApp" 1 "AuxChannelOn" 0 "AuxChannelOff" ;
VAL_ 2561081086 AuxI_O72 3 "NtAvlblTkNoActionDependingOnApp" 2 "ErrrIndctrNotUsedDependingOnApp" 1 "AuxChannelOn" 0 "AuxChannelOff" ;
VAL_ 2561081086 AuxI_O65 3 "NtAvlblTkNoActionDependingOnApp" 2 "ErrrIndctrNotUsedDependingOnApp" 1 "AuxChannelOn" 0 "AuxChannelOff" ;
VAL_ 2561081086 AuxI_O66 3 "NtAvlblTkNoActionDependingOnApp" 2 "ErrrIndctrNotUsedDependingOnApp" 1 "AuxChannelOn" 0 "AuxChannelOff" ;
VAL_ 2561081086 AuxI_O67 3 "NtAvlblTkNoActionDependingOnApp" 2 "ErrrIndctrNotUsedDependingOnApp" 1 "AuxChannelOn" 0 "AuxChannelOff" ;
VAL_ 2561081086 AuxI_O68 3 "NtAvlblTkNoActionDependingOnApp" 2 "ErrrIndctrNotUsedDependingOnApp" 1 "AuxChannelOn" 0 "AuxChannelOff" ;
VAL_ 2561081086 AuxI_O61 3 "NtAvlblTkNoActionDependingOnApp" 2 "ErrrIndctrNotUsedDependingOnApp" 1 "AuxChannelOn" 0 "AuxChannelOff" ;
VAL_ 2561081086 AuxI_O62 3 "NtAvlblTkNoActionDependingOnApp" 2 "ErrrIndctrNotUsedDependingOnApp" 1 "AuxChannelOn" 0 "AuxChannelOff" ;
VAL_ 2561081086 AuxI_O63 3 "NtAvlblTkNoActionDependingOnApp" 2 "ErrrIndctrNotUsedDependingOnApp" 1 "AuxChannelOn" 0 "AuxChannelOff" ;
VAL_ 2561081086 AuxI_O64 3 "NtAvlblTkNoActionDependingOnApp" 2 "ErrrIndctrNotUsedDependingOnApp" 1 "AuxChannelOn" 0 "AuxChannelOff" ;
VAL_ 2561081086 AuxI_O57 3 "NtAvlblTkNoActionDependingOnApp" 2 "ErrrIndctrNotUsedDependingOnApp" 1 "AuxChannelOn" 0 "AuxChannelOff" ;
VAL_ 2561081086 AuxI_O58 3 "NtAvlblTkNoActionDependingOnApp" 2 "ErrrIndctrNotUsedDependingOnApp" 1 "AuxChannelOn" 0 "AuxChannelOff" ;
VAL_ 2561081086 AuxI_O59 3 "NtAvlblTkNoActionDependingOnApp" 2 "ErrrIndctrNotUsedDependingOnApp" 1 "AuxChannelOn" 0 "AuxChannelOff" ;
VAL_ 2561081086 AuxI_O60 3 "NtAvlblTkNoActionDependingOnApp" 2 "ErrrIndctrNotUsedDependingOnApp" 1 "AuxChannelOn" 0 "AuxChannelOff" ;
VAL_ 2561081086 AuxI_O53 3 "NtAvlblTkNoActionDependingOnApp" 2 "ErrrIndctrNotUsedDependingOnApp" 1 "AuxChannelOn" 0 "AuxChannelOff" ;
VAL_ 2561081086 AuxI_O54 3 "NtAvlblTkNoActionDependingOnApp" 2 "ErrrIndctrNotUsedDependingOnApp" 1 "AuxChannelOn" 0 "AuxChannelOff" ;
VAL_ 2561081086 AuxI_O55 3 "NtAvlblTkNoActionDependingOnApp" 2 "ErrrIndctrNotUsedDependingOnApp" 1 "AuxChannelOn" 0 "AuxChannelOff" ;
VAL_ 2561081086 AuxI_O56 3 "NtAvlblTkNoActionDependingOnApp" 2 "ErrrIndctrNotUsedDependingOnApp" 1 "AuxChannelOn" 0 "AuxChannelOff" ;
VAL_ 2561081086 AuxI_O49 3 "NtAvlblTkNoActionDependingOnApp" 2 "ErrrIndctrNotUsedDependingOnApp" 1 "AuxChannelOn" 0 "AuxChannelOff" ;
VAL_ 2561081086 AuxI_O50 3 "NtAvlblTkNoActionDependingOnApp" 2 "ErrrIndctrNotUsedDependingOnApp" 1 "AuxChannelOn" 0 "AuxChannelOff" ;
VAL_ 2561081086 AuxI_O51 3 "NtAvlblTkNoActionDependingOnApp" 2 "ErrrIndctrNotUsedDependingOnApp" 1 "AuxChannelOn" 0 "AuxChannelOff" ;
VAL_ 2561081086 AuxI_O52 3 "NtAvlblTkNoActionDependingOnApp" 2 "ErrrIndctrNotUsedDependingOnApp" 1 "AuxChannelOn" 0 "AuxChannelOff" ;
VAL_ 2561015550 AuxI_O92 3 "NtAvlblTkNoActionDependingOnApp" 2 "ErrrIndctrNotUsedDependingOnApp" 1 "AuxChannelOn" 0 "AuxChannelOff" ;
VAL_ 2561015550 AuxI_O85 3 "NtAvlblTkNoActionDependingOnApp" 2 "ErrrIndctrNotUsedDependingOnApp" 1 "AuxChannelOn" 0 "AuxChannelOff" ;
VAL_ 2561015550 AuxI_O86 3 "NtAvlblTkNoActionDependingOnApp" 2 "ErrrIndctrNotUsedDependingOnApp" 1 "AuxChannelOn" 0 "AuxChannelOff" ;
VAL_ 2561015550 AuxI_O87 3 "NtAvlblTkNoActionDependingOnApp" 2 "ErrrIndctrNotUsedDependingOnApp" 1 "AuxChannelOn" 0 "AuxChannelOff" ;
VAL_ 2561015550 AuxI_O88 3 "NtAvlblTkNoActionDependingOnApp" 2 "ErrrIndctrNotUsedDependingOnApp" 1 "AuxChannelOn" 0 "AuxChannelOff" ;
VAL_ 2561015550 AuxI_O81 3 "NtAvlblTkNoActionDependingOnApp" 2 "ErrrIndctrNotUsedDependingOnApp" 1 "AuxChannelOn" 0 "AuxChannelOff" ;
VAL_ 2561015550 AuxI_O82 3 "NtAvlblTkNoActionDependingOnApp" 2 "ErrrIndctrNotUsedDependingOnApp" 1 "AuxChannelOn" 0 "AuxChannelOff" ;
VAL_ 2561015550 AuxI_O83 3 "NtAvlblTkNoActionDependingOnApp" 2 "ErrrIndctrNotUsedDependingOnApp" 1 "AuxChannelOn" 0 "AuxChannelOff" ;
VAL_ 2561015550 AuxI_O84 3 "NtAvlblTkNoActionDependingOnApp" 2 "ErrrIndctrNotUsedDependingOnApp" 1 "AuxChannelOn" 0 "AuxChannelOff" ;
VAL_ 2561015550 AuxI_O109 3 "NtAvlblTkNoActionDependingOnApp" 2 "ErrrIndctrNotUsedDependingOnApp" 1 "AuxChannelOn" 0 "AuxChannelOff" ;
VAL_ 2561015550 AuxI_O110 3 "NtAvlblTkNoActionDependingOnApp" 2 "ErrrIndctrNotUsedDependingOnApp" 1 "AuxChannelOn" 0 "AuxChannelOff" ;
VAL_ 2561015550 AuxI_O111 3 "NtAvlblTkNoActionDependingOnApp" 2 "ErrrIndctrNotUsedDependingOnApp" 1 "AuxChannelOn" 0 "AuxChannelOff" ;
VAL_ 2561015550 AuxI_O112 3 "NtAvlblTkNoActionDependingOnApp" 2 "ErrrIndctrNotUsedDependingOnApp" 1 "AuxChannelOn" 0 "AuxChannelOff" ;
VAL_ 2561015550 AuxI_O105 3 "NtAvlblTkNoActionDependingOnApp" 2 "ErrrIndctrNotUsedDependingOnApp" 1 "AuxChannelOn" 0 "AuxChannelOff" ;
VAL_ 2561015550 AuxI_O106 3 "NtAvlblTkNoActionDependingOnApp" 2 "ErrrIndctrNotUsedDependingOnApp" 1 "AuxChannelOn" 0 "AuxChannelOff" ;
VAL_ 2561015550 AuxI_O107 3 "NtAvlblTkNoActionDependingOnApp" 2 "ErrrIndctrNotUsedDependingOnApp" 1 "AuxChannelOn" 0 "AuxChannelOff" ;
VAL_ 2561015550 AuxI_O108 3 "NtAvlblTkNoActionDependingOnApp" 2 "ErrrIndctrNotUsedDependingOnApp" 1 "AuxChannelOn" 0 "AuxChannelOff" ;
VAL_ 2561015550 AuxI_O101 2 "ErrrIndctrNotUsedDependingOnApp" 1 "AuxChannelOn" 0 "AuxChannelOff" 3 "NtAvlblTkNoActionDependingOnApp" ;
VAL_ 2561015550 AuxI_O102 3 "NtAvlblTkNoActionDependingOnApp" 2 "ErrrIndctrNotUsedDependingOnApp" 1 "AuxChannelOn" 0 "AuxChannelOff" ;
VAL_ 2561015550 AuxI_O103 3 "NtAvlblTkNoActionDependingOnApp" 2 "ErrrIndctrNotUsedDependingOnApp" 1 "AuxChannelOn" 0 "AuxChannelOff" ;
VAL_ 2561015550 AuxI_O104 3 "NtAvlblTkNoActionDependingOnApp" 2 "ErrrIndctrNotUsedDependingOnApp" 1 "AuxChannelOn" 0 "AuxChannelOff" ;
VAL_ 2561015550 AuxI_O97 3 "NtAvlblTkNoActionDependingOnApp" 2 "ErrrIndctrNotUsedDependingOnApp" 1 "AuxChannelOn" 0 "AuxChannelOff" ;
VAL_ 2561015550 AuxI_O98 3 "NtAvlblTkNoActionDependingOnApp" 2 "ErrrIndctrNotUsedDependingOnApp" 1 "AuxChannelOn" 0 "AuxChannelOff" ;
VAL_ 2561015550 AuxI_O99 3 "NtAvlblTkNoActionDependingOnApp" 2 "ErrrIndctrNotUsedDependingOnApp" 1 "AuxChannelOn" 0 "AuxChannelOff" ;
VAL_ 2561015550 AuxI_O100 3 "NtAvlblTkNoActionDependingOnApp" 2 "ErrrIndctrNotUsedDependingOnApp" 1 "AuxChannelOn" 0 "AuxChannelOff" ;
VAL_ 2561015550 AuxI_O93 3 "NtAvlblTkNoActionDependingOnApp" 2 "ErrrIndctrNotUsedDependingOnApp" 1 "AuxChannelOn" 0 "AuxChannelOff" ;
VAL_ 2561015550 AuxI_O94 3 "NtAvlblTkNoActionDependingOnApp" 2 "ErrrIndctrNotUsedDependingOnApp" 1 "AuxChannelOn" 0 "AuxChannelOff" ;
VAL_ 2561015550 AuxI_O95 3 "NtAvlblTkNoActionDependingOnApp" 2 "ErrrIndctrNotUsedDependingOnApp" 1 "AuxChannelOn" 0 "AuxChannelOff" ;
VAL_ 2561015550 AuxI_O96 3 "NtAvlblTkNoActionDependingOnApp" 2 "ErrrIndctrNotUsedDependingOnApp" 1 "AuxChannelOn" 0 "AuxChannelOff" ;
VAL_ 2561015550 AuxI_O89 3 "NtAvlblTkNoActionDependingOnApp" 2 "ErrrIndctrNotUsedDependingOnApp" 1 "AuxChannelOn" 0 "AuxChannelOff" ;
VAL_ 2561015550 AuxI_O90 3 "NtAvlblTkNoActionDependingOnApp" 2 "ErrrIndctrNotUsedDependingOnApp" 1 "AuxChannelOn" 0 "AuxChannelOff" ;
VAL_ 2561015550 AuxI_O91 3 "NtAvlblTkNoActionDependingOnApp" 2 "ErrrIndctrNotUsedDependingOnApp" 1 "AuxChannelOn" 0 "AuxChannelOff" ;
VAL_ 2566746622 TrailerBrakeStrokeAxle5Right 7 "NotAvailable" 6 "SensorError" 5 "Reserved" 3 "DraggingBrake" 2 "Overstroke" 1 "Nonfunctioning" 0 "OK" ;
VAL_ 2566746622 TrailerBrakeStrokeAxle5Left 7 "NotAvailable" 6 "SensorError" 5 "Reserved" 3 "DraggingBrake" 2 "Overstroke" 1 "Nonfunctioning" 0 "OK" ;
VAL_ 2566746622 TrailerBrakeStrokeAxle4Right 7 "NotAvailable" 6 "SensorError" 5 "Reserved" 3 "DraggingBrake" 2 "Overstroke" 1 "Nonfunctioning" 0 "OK" ;
VAL_ 2566746622 TrailerBrakeStrokeAxle4Left 7 "NotAvailable" 6 "SensorError" 5 "Reserved" 3 "DraggingBrake" 2 "Overstroke" 1 "Nonfunctioning" 0 "OK" ;
VAL_ 2566746622 TrailerBrakeStrokeAxle3Right 7 "NotAvailable" 6 "SensorError" 5 "Reserved" 3 "DraggingBrake" 2 "Overstroke" 1 "Nonfunctioning" 0 "OK" ;
VAL_ 2566746622 TrailerBrakeStrokeAxle3Left 7 "NotAvailable" 6 "SensorError" 5 "Reserved" 3 "DraggingBrake" 2 "Overstroke" 1 "Nonfunctioning" 0 "OK" ;
VAL_ 2566746622 TrailerBrakeStrokeAxle2Right 7 "NotAvailable" 6 "SensorError" 5 "Reserved" 3 "DraggingBrake" 2 "Overstroke" 1 "Nonfunctioning" 0 "OK" ;
VAL_ 2566746622 TrailerBrakeStrokeAxle2Left 7 "NotAvailable" 6 "SensorError" 5 "Reserved" 3 "DraggingBrake" 2 "Overstroke" 1 "Nonfunctioning" 0 "OK" ;
VAL_ 2566746622 TrailerBrakeStrokeAxle1Right 7 "NotAvailable" 6 "SensorError" 5 "Reserved" 3 "DraggingBrake" 2 "Overstroke" 1 "Nonfunctioning" 0 "OK" ;
VAL_ 2566746622 TrailerBrakeStrokeAxle1Left 7 "NotAvailable" 6 "SensorError" 5 "Reserved" 3 "DraggingBrake" 2 "Overstroke" 1 "Nonfunctioning" 0 "OK" ;
VAL_ 2566746622 TractorBrakeStrokeAxle5Right 7 "NotAvailable" 6 "SensorError" 5 "Reserved" 3 "DraggingBrake" 2 "Overstroke" 1 "Nonfunctioning" 0 "OK" ;
VAL_ 2566746622 TractorBrakeStrokeAxle5Left 7 "NotAvailable" 6 "SensorError" 5 "Reserved" 3 "DraggingBrake" 2 "Overstroke" 1 "Nonfunctioning" 0 "OK" ;
VAL_ 2566746622 TractorBrakeStrokeAxle4Right 7 "NotAvailable" 6 "SensorError" 5 "Reserved" 3 "DraggingBrake" 2 "Overstroke" 1 "Nonfunctioning" 0 "OK" ;
VAL_ 2566746622 TractorBrakeStrokeAxle4Left 7 "NotAvailable" 6 "SensorError" 5 "Reserved" 3 "DraggingBrake" 2 "Overstroke" 1 "Nonfunctioning" 0 "OK" ;
VAL_ 2566746622 TractorBrakeStrokeAxle3Right 7 "NotAvailable" 6 "SensorError" 5 "Reserved" 3 "DraggingBrake" 2 "Overstroke" 1 "Nonfunctioning" 0 "OK" ;
VAL_ 2566746622 TractorBrakeStrokeAxle3Left 7 "NotAvailable" 6 "SensorError" 5 "Reserved" 3 "DraggingBrake" 2 "Overstroke" 1 "Nonfunctioning" 0 "OK" ;
VAL_ 2566746622 TractorBrakeStrokeAxle2Right 7 "NotAvailable" 6 "SensorError" 5 "Reserved" 3 "DraggingBrake" 2 "Overstroke" 1 "Nonfunctioning" 0 "OK" ;
VAL_ 2566746622 TractorBrakeStrokeAxle2Left 7 "NotAvailable" 6 "SensorError" 5 "Reserved" 3 "DraggingBrake" 2 "Overstroke" 1 "Nonfunctioning" 0 "OK" ;
VAL_ 2566746622 TractorBrakeStrokeAxle1Right 7 "NotAvailable" 6 "SensorError" 5 "Reserved" 3 "DraggingBrake" 2 "Overstroke" 1 "Nonfunctioning" 0 "OK" ;
VAL_ 2566746622 TractorBrakeStrokeAxle1Left 7 "NotAvailable" 6 "SensorError" 5 "Reserved" 3 "DraggingBrake" 2 "Overstroke" 1 "Nonfunctioning" 0 "OK" ;
VAL_ 2566827568 AirCompressorStatus 3 "NotAvailable" 2 "ErrorIndicator" 1 "CompressorActive" 0 "CompressorNotActive" ;
VAL_ 2566803745 RequestedACCDistanceMode 7 "NotAvailable" 6 "ErrorCondition" 5 "NotDefined" 4 "Mode5_ShortestDistance" 3 "Mode4" 2 "Mode3" 1 "Mode2" 0 "Mode1_LargestDistance" ;
VAL_ 2566803745 ACCUsageDemand_ACC2 3 "dontCare" 2 "reserved" 1 "drvrDmndFrUsngACCDstncKpingCtrl" 0 "drvrDmndFrNtUsngACCDstncKpngCtr" ;
VAL_ 2432593918 ForwardCollisionWarning 3 "notAvailable" 2 "ErrorIndicator" 1 "CollisionIsImminent" 0 "NoWarning" ;
VAL_ 2432593918 ACCDistanceAlertSignal 3 "TakeNoAction" 2 "Reserved" 1 "ACCDASActive" 0 "ACCDASNotActive" ;
VAL_ 2432593918 ACCSystemShutoffWarning 3 "TakeNoAction" 2 "Reserved" 1 "ACCSSOWActive" 0 "ACCSSOWNotActive" ;
VAL_ 2432593918 ACCTargetDetected 3 "TakeNoAction" 2 "Reserved" 1 "TargetDetected" 0 "NoTargetsDetected" ;
VAL_ 2432593918 AdptveCruiseCtrlSetDistanceMode 7 "NotAvailable_NotValid" 6 "ErrorCondition" 5 "ConventionalCruiseCtrlMode" 4 "ACCDistanceMode5" 3 "ACCDistanceMode4" 2 "ACCDistanceMode3" 1 "ACCDistanceMode2" 0 "ACCDistanceMode1" ;
VAL_ 2432593918 AdaptiveCruiseCtrlMode 7 "NotAvailable_NotValid" 6 "DsbldErrrCndtnUsdTIndctThtACCIs" 5 "FinishMode" 4 "HldMdUsdTIndctThtACCHsLstThPrvs" 3 "OvertakeMode" 2 "DstncCtrlActvUsdTIndctThtACCIsO" 1 "SpeedCtrlActive" 0 "OffUsdTIndctACCIsEnbldInClbCnfg" ;
VAL_ 2565406462 ControlByte 3 "CannotRespond" 2 "AccessDenied" 1 "NACK" 0 "ACK" ;
VAL_ 2566803198 Status2OfDoors 3 "notAvailable" 2 "error" 1 "atLeast1BusDoorEnabled" 0 "allBusDoorsAreDisabled" ;
VAL_ 2566803198 Ramp_WheelChairLiftPos 3 "NotAvailable" 2 "Error" 1 "OutsideBus" 0 "InsideBus" ;
VAL_ 2566803198 PosOfDoors 15 "NotAvailable" 14 "Error" 3 "1101NotDefined" 2 "AllDoorsClosed" 1 "ClosingLastDoor" 0 "AtLeast1DoorIsOpen" ;
VAL_ 2565870334 FifthWheelRollWarningIndicator 3 "NotAvailable" 2 "error" 1 "LimitExceeded" 0 "LimitNotExceeded" ;
VAL_ 2566762238 FifthWheelSliderLockIndicator 3 "NotAvailable" 2 "Error" 1 "Locked" 0 "NotLocked" ;
VAL_ 2566762238 FfthWhlLckCoupleStatusIndicator 3 "NotAvailable" 2 "Error" 1 "SuccessfulCoupleDetected" 0 "IncmpltBdCplTrckShuldNotBeMoved" ;
VAL_ 2566762238 FfthWhlLckRadyToCoupleIndicator 3 "NotAvailable" 2 "Error" 1 "LockOpenReadyToCouple" 0 "LockNotOpenNotReadyToCouple" ;
VAL_ 2566762238 FifthWheelErrorStatus 15 "NotAvailable" 9 "Kingpin_LockOpen" 8 "KingpinMissingMoreThan5Seconds" 7 "CouplingTimingError" 6 "CouplingSequenceError_Kingpin" 5 "CouplingSequenceError" 14 "NotUsed" 2 "Kingpin_LocksOpenAtStartup" 1 "LocksClosed_NoKingpinAtStartup" 0 "ImproperCouple" ;
VAL_ 2364543998 PitchAndRollCompensated 1 "NotAvailable" 0 "CompensationOn" 3 "NotAvailable" 2 "Error" ;
VAL_ 2364543998 PitchRateFigureOfMerit 1 "NotAvailable" 0 "PtchRtDgrddDtIsSspctDTEnvrnmntl" 3 "NotAvailable" 2 "Error" ;
VAL_ 2364543998 RollAngleFigureOfMerit 1 "RollAngleDegraded" 0 "RollAngleFullyFunctional" 3 "NotAvailable" 2 "Error" ;
VAL_ 2364543998 PitchAngleFigureOfMerit 1 "NotAvailable" 0 "PtchAnglDgrddDtIsSspctDTEnvrnmn" 3 "NotAvailable" 2 "Error" ;
VAL_ 2566846718 TransOilLevelMeasurementStatus 15 "NotAvailable" 14 "Error" 13 "ConditionsNotValidOther" 12 "NotDefined" 9 "CnditionsNotValidNoRqForReading" 8 "CndtionsNotValidEngSpeedTooHigh" 7 "CnditionsNotValidEngSpeedTooLow" 6 "CndtionsNotValidVehicleNotLevel" 5 "CndtnsNtVldVhclMvngOtptShftSpdT" 4 "CndtnsNtVldTrnsFluidTempTooHigh" 3 "CndtnsNtVldTransFluidTempTooLow" 2 "ConditionsNotValidTransInGear" 1 "CndtnsNtVldSttlngTmrStllCntngDw" 0 "CndtnsVldFrTrnsOlLvlMeasurement" ;
VAL_ 2566846718 TransOilLevelCountdownTimer 15 "NotAvailable" 14 "Error" 13 "ThirteenMinutes" 12 "TwelveMinutes" 11 "ElevenMinutes" 10 "TenMinutes" 9 "NineMinutes" 8 "EightMinutes" 7 "SevenMinutes" 6 "SixMinutes" 5 "FiveMinutes" 4 "FourMinutes" 3 "ThreeMinutes" 2 "TwoMinutes" 1 "OneMinute" 0 "lessThan1Minute" ;
VAL_ 2566846718 TransOilLevelHigh_Low 251 "CondNotAcceptableForValidMeasure" ;
VAL_ 2566760702 WrlessCommunicationNetworkType2 1 "CellularNetwork2" 0 "CellularNetwork1" ;
VAL_ 2566760702 NetworkAntennaStatus2 1 "On" 0 "Off" ;
VAL_ 2566760702 NetworkServiceStatus2 1 "RoamingService" 0 "LocalService" ;
VAL_ 2566760702 NetworkTransceiverStatus2 1 "On" 0 "Off" ;
VAL_ 2566760958 WrlessCommunicationNetworkType1 1 "CellularNetwork2" 0 "CellularNetwork1" ;
VAL_ 2566760958 NetworkAntennaStatus1 1 "On" 0 "Off" ;
VAL_ 2566760958 NetworkServiceStatus1 1 "RoamingService" 0 "LocalService" ;
VAL_ 2566760958 NetworkTransceiverStatus1 1 "On" 0 "Off" ;
VAL_ 2633869310 VoltageRegulatorEnabled 3 "NotAvailable" 2 "Error" 1 "RegulatingVoltage" 0 "NtRegulatingVoltageUnitDisabled" ;
VAL_ 2633869310 VoltageRegulatorSoftStartState 3 "NotAvailable" 2 "Error" 1 "SoftStartIsActive" 0 "SoftStartIsInactive" ;
VAL_ 2633869310 VltgRgltrUndrfrqncyCmpnstnEnbld 3 "NotAvailable" 2 "Error" 1 "UndrfrquencyCompensationEnabled" 0 "UndrfrqencyCompensationDisabled" ;
VAL_ 2633869310 VltgRgltrVAr_PwrFctrOprtingMode 7 "NotAvailable" 6 "Error" 5 "Reserved" 2 "VArRegulationEnabled" 1 "PowerFactorRegulationEnabled" 0 "VAr_PwrFactorRegulationDisabled" ;
VAL_ 2633869310 VltgRglatorLoadCompensationMode 7 "NotAvailable" 6 "Error" 5 "Reserved" 2 "IRLineDropCompensationEnabled" 1 "VoltageDroopCompensationEnabled" 0 "LoadCompensationDisabled" ;

SG_MUL_VAL_ 2565928476 Stub_FormOfWay ProfShort_ProfType 3-3;
SG_MUL_VAL_ 2565928476 Stub_Update ProfShort_ProfType 3-3;
SG_MUL_VAL_ 2565928476 Stub_TurnAngle ProfShort_ProfType 3-3;
SG_MUL_VAL_ 2565928476 Stub_SubPathIx ProfShort_ProfType 3-3;
SG_MUL_VAL_ 2565928476 Stub_RightOfWay ProfShort_ProfType 3-3;
SG_MUL_VAL_ 2565928476 Stub_Retr ProfShort_ProfType 3-3;
SG_MUL_VAL_ 2565928476 Stub_RelProb ProfShort_ProfType 3-3;
SG_MUL_VAL_ 2565928476 Stub_PathIx ProfShort_ProfType 3-3;
SG_MUL_VAL_ 2565928476 Stub_PartOfCalcRoute ProfShort_ProfType 3-3;
SG_MUL_VAL_ 2565928476 Stub_Ofs ProfShort_ProfType 3-3;
SG_MUL_VAL_ 2565928476 Stub_NumOfLanesInOppDir ProfShort_ProfType 3-3;
SG_MUL_VAL_ 2565928476 Stub_NumOfLanesInDrivDir ProfShort_ProfType 3-3;
SG_MUL_VAL_ 2565928476 Stub_LastStubAtOfs ProfShort_ProfType 3-3;
SG_MUL_VAL_ 2565928476 Stub_FunctRoadClass ProfShort_ProfType 3-3;
SG_MUL_VAL_ 2565928476 Stub_CycCnt ProfShort_ProfType 3-3;
SG_MUL_VAL_ 2565928476 Stub_ComplexInters ProfShort_ProfType 3-3;
SG_MUL_VAL_ 2565928476 Seg_Update ProfShort_ProfType 2-2;
SG_MUL_VAL_ 2565928476 Seg_Tunnel ProfShort_ProfType 2-2;
SG_MUL_VAL_ 2565928476 Seg_Retr ProfShort_ProfType 2-2;
SG_MUL_VAL_ 2565928476 Seg_RelProb ProfShort_ProfType 2-2;
SG_MUL_VAL_ 2565928476 Seg_PathIx ProfShort_ProfType 2-2;
SG_MUL_VAL_ 2565928476 Seg_PartOfCalcRoute ProfShort_ProfType 2-2;
SG_MUL_VAL_ 2565928476 Seg_Ofs ProfShort_ProfType 2-2;
SG_MUL_VAL_ 2565928476 Seg_NumOfLanesInOppDir ProfShort_ProfType 2-2;
SG_MUL_VAL_ 2565928476 Seg_NumOfLanesInDrivDir ProfShort_ProfType 2-2;
SG_MUL_VAL_ 2565928476 Seg_FunctRoadClass ProfShort_ProfType 2-2;
SG_MUL_VAL_ 2565928476 Seg_FormOfWay ProfShort_ProfType 2-2;
SG_MUL_VAL_ 2565928476 Seg_EffSpeedLimType ProfShort_ProfType 2-2;
SG_MUL_VAL_ 2565928476 Seg_EffSpeedLim ProfShort_ProfType 2-2;
SG_MUL_VAL_ 2565928476 Seg_DividedRoad ProfShort_ProfType 2-2;
SG_MUL_VAL_ 2565928476 Seg_CycCnt ProfShort_ProfType 2-2;
SG_MUL_VAL_ 2565928476 Seg_ComplexInters ProfShort_ProfType 2-2;
SG_MUL_VAL_ 2565928476 Seg_BuiltUpArea ProfShort_ProfType 2-2;
SG_MUL_VAL_ 2565928476 Seg_Bridge ProfShort_ProfType 2-2;
SG_MUL_VAL_ 2565928476 ProfShort_Val1_9_RsvdForStdTypes ProfShort_ProfType 9-9;
SG_MUL_VAL_ 2565928476 ProfShort_Val1_8_HeadChg ProfShort_ProfType 8-8;
SG_MUL_VAL_ 2565928476 ProfShort_Val1_7_VarSpeedSignPos ProfShort_ProfType 7-7;
SG_MUL_VAL_ 2565928476 ProfShort_Val1_6_RoadCond ProfShort_ProfType 6-6;
SG_MUL_VAL_ 2565928476 ProfShort_Val1_5_RoadAcc ProfShort_ProfType 5-5;
SG_MUL_VAL_ 2565928476 ProfShort_Val1_4_Slope ProfShort_ProfType 4-4;
SG_MUL_VAL_ 2565928476 ProfShort_Val1_3_Slope ProfShort_ProfType 3-3;
SG_MUL_VAL_ 2565928476 ProfShort_Val1_2_RouteNumTypes ProfShort_ProfType 2-2;
SG_MUL_VAL_ 2565928476 ProfShort_Val1_1_Curv ProfShort_ProfType 1-1;
SG_MUL_VAL_ 2565928476 ProfShort_Val1_16_RsvdForSysSpec ProfShort_ProfType 16-16;
SG_MUL_VAL_ 2565928476 ProfShort_Val0_9_RsvdForStdTypes ProfShort_ProfType 9-9;
SG_MUL_VAL_ 2565928476 ProfShort_Val0_8_HeadChg ProfShort_ProfType 8-8;
SG_MUL_VAL_ 2565928476 ProfShort_Val0_7_VarSpeedSignPos ProfShort_ProfType 7-7;
SG_MUL_VAL_ 2565928476 ProfShort_Val0_6_RoadCond ProfShort_ProfType 6-6;
SG_MUL_VAL_ 2565928476 ProfShort_Val0_5_RoadAcc ProfShort_ProfType 5-5;
SG_MUL_VAL_ 2565928476 ProfShort_Val0_4_Slope ProfShort_ProfType 4-4;
SG_MUL_VAL_ 2565928476 ProfShort_Val0_3_Slope ProfShort_ProfType 3-3;
SG_MUL_VAL_ 2565928476 ProfShort_Val0_2_RouteNumTypes ProfShort_ProfType 2-2;
SG_MUL_VAL_ 2565928476 ProfShort_Val0_1_Curv ProfShort_ProfType 1-1;
SG_MUL_VAL_ 2565928476 ProfShort_Val0_16_RsvdForSysSpec ProfShort_ProfType 16-16;
SG_MUL_VAL_ 2565928476 ProfShort_Update ProfShort_ProfType 4-4;
SG_MUL_VAL_ 2565928476 ProfShort_Retr ProfShort_ProfType 4-4;
SG_MUL_VAL_ 2565928476 ProfShort_PathIx ProfShort_ProfType 4-4;
SG_MUL_VAL_ 2565928476 ProfShort_Ofs ProfShort_ProfType 4-4;
SG_MUL_VAL_ 2565928476 ProfShort_Dist1 ProfShort_ProfType 4-4;
SG_MUL_VAL_ 2565928476 ProfShort_CycCnt ProfShort_ProfType 4-4;
SG_MUL_VAL_ 2565928476 ProfShort_CtrlPnt ProfShort_ProfType 4-4;
SG_MUL_VAL_ 2565928476 ProfShort_Accur ProfShort_ProfType 4-4;
SG_MUL_VAL_ 2565928476 ProfLong_Val9RsvdForStdTypes ProfShort_ProfType 9-9;
SG_MUL_VAL_ 2565928476 ProfLong_Val8RsvdForStdTypes ProfShort_ProfType 8-8;
SG_MUL_VAL_ 2565928476 ProfLong_Val7RsvdForStdTypes ProfShort_ProfType 7-7;
SG_MUL_VAL_ 2565928476 ProfLong_Val5RsvdForStdTypes ProfShort_ProfType 5-5;
SG_MUL_VAL_ 2565928476 ProfLong_Val6RsvdForStdTypes ProfShort_ProfType 6-6;
SG_MUL_VAL_ 2565928476 ProfLong_Val4RsvdForStdTypes ProfShort_ProfType 4-4;
SG_MUL_VAL_ 2565928476 ProfLong_Val3RsvdForStdTypes ProfShort_ProfType 3-3;
SG_MUL_VAL_ 2565928476 ProfLong_Val31RsvdForSysSpecType ProfShort_ProfType 31-31;
SG_MUL_VAL_ 2565928476 ProfLong_Val30RsvdForSysSpecType ProfShort_ProfType 30-30;
SG_MUL_VAL_ 2565928476 ProfLong_Val2Lat ProfShort_ProfType 2-2;
SG_MUL_VAL_ 2565928476 ProfLong_Val1Long ProfShort_ProfType 1-1;
SG_MUL_VAL_ 2565928476 ProfLong_Val29RsvdForSysSpecType ProfShort_ProfType 29-29;
SG_MUL_VAL_ 2565928476 ProfLong_Val28RsvdForSysSpecType ProfShort_ProfType 28-28;
SG_MUL_VAL_ 2565928476 ProfLong_Val27RsvdForSysSpecType ProfShort_ProfType 27-27;
SG_MUL_VAL_ 2565928476 ProfLong_Val26RsvdForSysSpecType ProfShort_ProfType 26-26;
SG_MUL_VAL_ 2565928476 ProfLong_Val25RsvdForSysSpecType ProfShort_ProfType 25-25;
SG_MUL_VAL_ 2565928476 ProfLong_Val24RsvdForSysSpecType ProfShort_ProfType 24-24;
SG_MUL_VAL_ 2565928476 ProfLong_Val23RsvdForSysSpecType ProfShort_ProfType 23-23;
SG_MUL_VAL_ 2565928476 ProfLong_Val21RsvdForSysSpecType ProfShort_ProfType 21-21;
SG_MUL_VAL_ 2565928476 ProfLong_Val20RsvdForSysSpecType ProfShort_ProfType 20-20;
SG_MUL_VAL_ 2565928476 ProfLong_Val22RsvdForSysSpecType ProfShort_ProfType 22-22;
SG_MUL_VAL_ 2565928476 ProfLong_Val19RsvdForSysSpecType ProfShort_ProfType 19-19;
SG_MUL_VAL_ 2565928476 ProfLong_Val18RsvdForSysSpecType ProfShort_ProfType 18-18;
SG_MUL_VAL_ 2565928476 ProfLong_Val17RsvdForSysSpecType ProfShort_ProfType 17-17;
SG_MUL_VAL_ 2565928476 ProfLong_Val16RsvdForSysSpecType ProfShort_ProfType 16-16;
SG_MUL_VAL_ 2565928476 ProfLong_Val15RsvdForStdTypes ProfShort_ProfType 15-15;
SG_MUL_VAL_ 2565928476 ProfLong_Val14RsvdForStdTypes ProfShort_ProfType 14-14;
SG_MUL_VAL_ 2565928476 ProfLong_Val13RsvdForStdTypes ProfShort_ProfType 13-13;
SG_MUL_VAL_ 2565928476 ProfLong_Val12RsvdForStdTypes ProfShort_ProfType 12-12;
SG_MUL_VAL_ 2565928476 ProfLong_Val11RsvdForStdTypes ProfShort_ProfType 11-11;
SG_MUL_VAL_ 2565928476 ProfLong_Val10RsvdForStdTypes ProfShort_ProfType 10-10;
SG_MUL_VAL_ 2565928476 ProfLong_Update ProfShort_ProfType 5-5;
SG_MUL_VAL_ 2565928476 ProfLong_Retr ProfShort_ProfType 5-5;
SG_MUL_VAL_ 2565928476 ProfLong_PathIx ProfShort_ProfType 5-5;
SG_MUL_VAL_ 2565928476 ProfLong_Ofs ProfShort_ProfType 5-5;
SG_MUL_VAL_ 2565928476 ProfLong_CycCnt ProfShort_ProfType 5-5;
SG_MUL_VAL_ 2565928476 ProfLong_CtrlPnt ProfShort_ProfType 5-5;
SG_MUL_VAL_ 2565928476 Pos_Speed ProfShort_ProfType 1-1;
SG_MUL_VAL_ 2565928476 Pos_RelHead ProfShort_ProfType 1-1;
SG_MUL_VAL_ 2565928476 Pos_PosProb ProfShort_ProfType 1-1;
SG_MUL_VAL_ 2565928476 Pos_PosIx ProfShort_ProfType 1-1;
SG_MUL_VAL_ 2565928476 Pos_PosConf ProfShort_ProfType 1-1;
SG_MUL_VAL_ 2565928476 Pos_PosAge ProfShort_ProfType 1-1;
SG_MUL_VAL_ 2565928476 Pos_PathIx ProfShort_ProfType 1-1;
SG_MUL_VAL_ 2565928476 Pos_Ofs ProfShort_ProfType 1-1;
SG_MUL_VAL_ 2565928476 Pos_CycCnt ProfShort_ProfType 1-1;
SG_MUL_VAL_ 2565928476 Pos_CurLane ProfShort_ProfType 1-1;
SG_MUL_VAL_ 2565928476 Meta_MapProvider ProfShort_ProfType 6-6;
SG_MUL_VAL_ 2565928476 Meta_CntryCode ProfShort_ProfType 6-6;
SG_MUL_VAL_ 2565928476 Meta_MinorProtoSubVer ProfShort_ProfType 6-6;
SG_MUL_VAL_ 2565928476 Meta_MajorProtoVer ProfShort_ProfType 6-6;
SG_MUL_VAL_ 2565928476 Meta_CycCnt ProfShort_ProfType 6-6;
SG_MUL_VAL_ 2565928476 Meta_HwVer ProfShort_ProfType 6-6;
SG_MUL_VAL_ 2565928476 Meta_DrivSide ProfShort_ProfType 6-6;
SG_MUL_VAL_ 2565928476 Meta_RegionCode ProfShort_ProfType 6-6;
SG_MUL_VAL_ 2565928476 Meta_MapVetYr ProfShort_ProfType 6-6;
SG_MUL_VAL_ 2565928476 Meta_MapVerQtr ProfShort_ProfType 6-6;
SG_MUL_VAL_ 2565928476 Meta_MinorProtoVer ProfShort_ProfType 6-6;
SG_MUL_VAL_ 2565928476 Meta_SpeedUnits ProfShort_ProfType 6-6;
